[part 4 of 5: packages /Cluster to /NmConfig]
AUTOSAR XML (schema 4-3-0)
package /Cluster  (continued)
  can cluster BMC_CAN01: baudrate=500000, protocol-name=CAN, protocol-version=2.0, bus-off-recovery={bor-counter-l-1-to-l-2=1, bor-time-l-1=0.05, bor-time-l-2=0.2}
    can physical channel CHNL: comm-connectors=CN_BMC_CAN01
      frame BJB_08_XIX_BMC_CAN01: id 0x12DD556E, to BMC_HV, frame-length=8, can-addressing-mode=EXTENDED, can-frame-rx-behavior=CAN-20, can-frame-tx-behavior=CAN-20
        pdu BJB_08_XIX_BMC_CAN01: length=8, transmission-mode-true-timing=cyclic-timing={time-offset=0, time-period=0.1}, unused-bit-pattern=0
          signal BJB_ErrMem_State_XIX_BJB_08_XIX_BMC_CAN01: start 12, 2 bit, little-endian, data-type-policy=OVERRIDE, i-signal-type=PRIMITIVE, init-value=2, base-type=BT_BJB_ErrMem_State, compu-method=CM_BJB_ErrMem_State, data-constr=DC_BJB_ErrMem_State, transfer-property=PENDING, to BMC_HV(timeout 1 s)  # Error Memory State
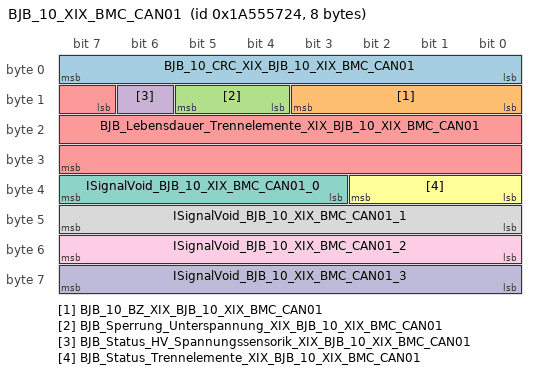
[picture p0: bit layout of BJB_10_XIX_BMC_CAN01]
      frame BJB_10_XIX_BMC_CAN01: id 0x1A555724, to BMC_HV, frame-length=8, can-addressing-mode=EXTENDED, can-frame-rx-behavior=CAN-20, can-frame-tx-behavior=CAN-20
        pdu BJB_10_XIX_BMC_CAN01_E2E: length=8, transmission-mode-true-timing=event-controlled-timing={number-of-repetitions=0, repetition-period=0}, unused-bit-pattern=0  # Fuer die Botschaft ist das Cyclic-Timing 1.0 zu verwenden.
          signal BJB_10_CRC_XIX_BJB_10_XIX_BMC_CAN01: start 0, 8 bit, little-endian, data-type-policy=OVERRIDE, i-signal-type=PRIMITIVE, init-value=0, base-type=BT_BJB_10_CRC, to BMC_HV(timeout 5 s)
          signal BJB_10_BZ_XIX_BJB_10_XIX_BMC_CAN01: start 8, 4 bit, little-endian, data-type-policy=OVERRIDE, i-signal-type=PRIMITIVE, init-value=0, base-type=BT_BJB_10_BZ, to BMC_HV(timeout 5 s)
          signal BJB_Sperrung_Unterspannung_XIX_BJB_10_XIX_BMC_CAN01: start 12, 2 bit, little-endian, data-type-policy=OVERRIDE, i-signal-type=PRIMITIVE, init-value=2, base-type=BT_BJB_Sperrung_Unterspannung, invalid-value=Invalid_BJB_Sperrung_Unterspannung_XIX_BJB_10_XIX_BMC_CAN01:3, compu-method=CM_BJB_Sperrung_Unterspannung, data-constr=DC_BJB_Sperrung_Unterspannung, to BMC_HV(timeout 5 s)  # Status Sperrung durch Unterspannung zum Datenaustausch für redundante Datenspeicherung
          signal BJB_Status_HV_Spannungssensorik_XIX_BJB_10_XIX_BMC_CAN01: start 14, 1 bit, little-endian, data-type-policy=OVERRIDE, i-signal-type=PRIMITIVE, init-value=0, base-type=BT_BJB_Status_HV_Spannungssensorik, invalid-value=Invalid_BJB_Status_HV_Spannungssensorik_XIX_BJB_10_XIX_BMC_CAN01:1, compu-method=CM_BJB_Status_HV_Spannungssensorik, data-constr=DC_BJB_Status_HV_Spannungssensorik, to BMC_HV(timeout 5 s)  # Status HV Spannungssensorik zum Datenaustausch für redundante Datenspeicherung
          signal BJB_Lebensdauer_Trennelemente_XIX_BJB_10_XIX_BMC_CAN01: start 15, 17 bit, little-endian, data-type-policy=OVERRIDE, i-signal-type=PRIMITIVE, init-value=131070, base-type=BT_BJB_Lebensdauer_Trennelemente, invalid-value=Invalid_BJB_Lebensdauer_Trennelemente_XIX_BJB_10_XIX_BMC_CAN01:131071, compu-method=CM_BJB_Lebensdauer_Trennelemente, data-constr=DC_BJB_Lebensdauer_Trennelemente, unit=Unit_Unit_None, to BMC_HV(timeout 5 s)  # Lebensdauerzähler Trennelemente zum Datenaustausch für redundante Datenspeicherung
          signal BJB_Status_Trennelemente_XIX_BJB_10_XIX_BMC_CAN01: start 32, 3 bit, little-endian, data-type-policy=OVERRIDE, i-signal-type=PRIMITIVE, init-value=6, base-type=BT_BJB_Status_Trennelemente, invalid-value=Invalid_BJB_Status_Trennelemente_XIX_BJB_10_XIX_BMC_CAN01:7, compu-method=CM_BJB_Status_Trennelemente, data-constr=DC_BJB_Status_Trennelemente, to BMC_HV(timeout 5 s)  # Status Trennelemente zum Datenaustausch für redundante Datenspeicherung
          signal ISignalVoid_BJB_10_XIX_BMC_CAN01_0: start 35, 5 bit, little-endian, system signal SignalVoid_BJB_10_0, data-type-policy=OVERRIDE, i-signal-type=PRIMITIVE, base-type=BT_SignalVoid
          signal ISignalVoid_BJB_10_XIX_BMC_CAN01_1: start 40, 8 bit, little-endian, system signal SignalVoid_BJB_10_1, data-type-policy=OVERRIDE, i-signal-type=PRIMITIVE, base-type=BT_SignalVoid
          signal ISignalVoid_BJB_10_XIX_BMC_CAN01_2: start 48, 8 bit, little-endian, system signal SignalVoid_BJB_10_2, data-type-policy=OVERRIDE, i-signal-type=PRIMITIVE, base-type=BT_SignalVoid
          signal ISignalVoid_BJB_10_XIX_BMC_CAN01_3: start 56, 8 bit, little-endian, system signal SignalVoid_BJB_10_3, data-type-policy=OVERRIDE, i-signal-type=PRIMITIVE, base-type=BT_SignalVoid
          mapping SG_BJB_10_XIX_BMC_CAN01: i-signal-group=SG_BJB_10_XIX_BMC_CAN01, transfer-property=TRIGGERED-WITHOUT-REPETITION
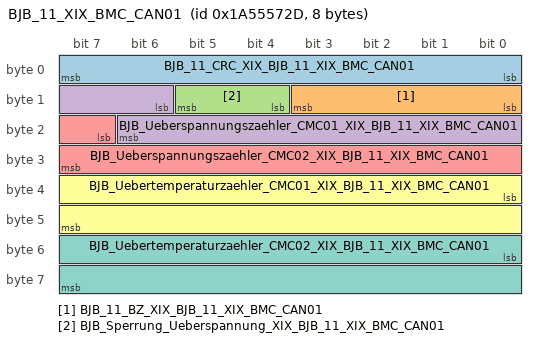
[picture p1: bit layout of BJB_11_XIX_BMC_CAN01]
      frame BJB_11_XIX_BMC_CAN01: id 0x1A55572D, to BMC_HV, frame-length=8, can-addressing-mode=EXTENDED, can-frame-rx-behavior=CAN-20, can-frame-tx-behavior=CAN-20
        pdu BJB_11_XIX_BMC_CAN01_E2E: length=8, transmission-mode-true-timing=event-controlled-timing={number-of-repetitions=0, repetition-period=0}, unused-bit-pattern=0  # Fuer die Botschaft ist das Cyclic-Timing 1.0 zu verwenden.
          signal BJB_11_CRC_XIX_BJB_11_XIX_BMC_CAN01: start 0, 8 bit, little-endian, data-type-policy=OVERRIDE, i-signal-type=PRIMITIVE, init-value=0, base-type=BT_BJB_11_CRC, to BMC_HV(timeout 5 s)
          signal BJB_11_BZ_XIX_BJB_11_XIX_BMC_CAN01: start 8, 4 bit, little-endian, data-type-policy=OVERRIDE, i-signal-type=PRIMITIVE, init-value=0, base-type=BT_BJB_11_BZ, to BMC_HV(timeout 5 s)
          signal BJB_Sperrung_Ueberspannung_XIX_BJB_11_XIX_BMC_CAN01: start 12, 2 bit, little-endian, data-type-policy=OVERRIDE, i-signal-type=PRIMITIVE, init-value=2, base-type=BT_BJB_Sperrung_Ueberspannung, invalid-value=Invalid_BJB_Sperrung_Ueberspannung_XIX_BJB_11_XIX_BMC_CAN01:3, compu-method=CM_BJB_Sperrung_Ueberspannung, data-constr=DC_BJB_Sperrung_Ueberspannung, to BMC_HV(timeout 5 s)  # Status Sperrung durch Ueberspannung zum Datenaustausch für redundante Datenspeicherung
          signal BJB_Ueberspannungszaehler_CMC01_XIX_BJB_11_XIX_BMC_CAN01: start 14, 9 bit, little-endian, data-type-policy=OVERRIDE, i-signal-type=PRIMITIVE, init-value=510, base-type=BT_BJB_Ueberspannungszaehler_CMC01, invalid-value=Invalid_BJB_Ueberspannungszaehler_CMC01_XIX_BJB_11_XIX_BMC_CAN01:511, compu-method=CM_BJB_Ueberspannungszaehler_CMC01, data-constr=DC_BJB_Ueberspannungszaehler_CMC01, unit=Unit_Unit_None, to BMC_HV(timeout 5 s)  # Überspannungszähler zum Datenaustausch für redundante Datenspeicherung
          signal BJB_Ueberspannungszaehler_CMC02_XIX_BJB_11_XIX_BMC_CAN01: start 23, 9 bit, little-endian, data-type-policy=OVERRIDE, i-signal-type=PRIMITIVE, init-value=510, base-type=BT_BJB_Ueberspannungszaehler_CMC02, invalid-value=Invalid_BJB_Ueberspannungszaehler_CMC02_XIX_BJB_11_XIX_BMC_CAN01:511, compu-method=CM_BJB_Ueberspannungszaehler_CMC02, data-constr=DC_BJB_Ueberspannungszaehler_CMC02, unit=Unit_Unit_None, to BMC_HV(timeout 5 s)  # Überspannungszähler zum Datenaustausch für redundante Datenspeicherung
          signal BJB_Uebertemperaturzaehler_CMC01_XIX_BJB_11_XIX_BMC_CAN01: start 32, 16 bit, little-endian, data-type-policy=OVERRIDE, i-signal-type=PRIMITIVE, init-value=65534, base-type=BT_BJB_Uebertemperaturzaehler_CMC01, invalid-value=Invalid_BJB_Uebertemperaturzaehler_CMC01_XIX_BJB_11_XIX_BMC_CAN01:65535, compu-method=CM_BJB_Uebertemperaturzaehler_CMC01, data-constr=DC_BJB_Uebertemperaturzaehler_CMC01, unit=Unit_Unit_None, to BMC_HV(timeout 5 s)  # Übertemperaturzähler zum Datenaustausch für redundante Datenspeicherung
          signal BJB_Uebertemperaturzaehler_CMC02_XIX_BJB_11_XIX_BMC_CAN01: start 48, 16 bit, little-endian, data-type-policy=OVERRIDE, i-signal-type=PRIMITIVE, init-value=65534, base-type=BT_BJB_Uebertemperaturzaehler_CMC02, invalid-value=Invalid_BJB_Uebertemperaturzaehler_CMC02_XIX_BJB_11_XIX_BMC_CAN01:65535, compu-method=CM_BJB_Uebertemperaturzaehler_CMC02, data-constr=DC_BJB_Uebertemperaturzaehler_CMC02, unit=Unit_Unit_None, to BMC_HV(timeout 5 s)  # Übertemperaturzähler zum Datenaustausch für redundante Datenspeicherung
          mapping SG_BJB_11_XIX_BMC_CAN01: i-signal-group=SG_BJB_11_XIX_BMC_CAN01, transfer-property=TRIGGERED-WITHOUT-REPETITION
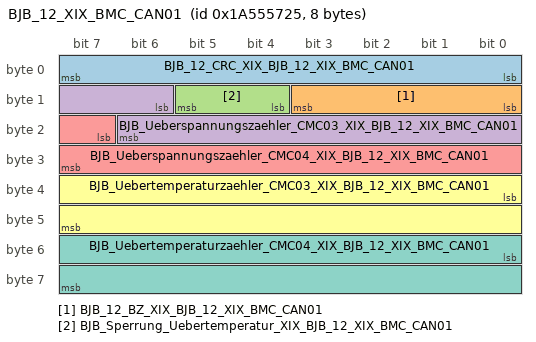
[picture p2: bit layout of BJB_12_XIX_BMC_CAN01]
      frame BJB_12_XIX_BMC_CAN01: id 0x1A555725, to BMC_HV, frame-length=8, can-addressing-mode=EXTENDED, can-frame-rx-behavior=CAN-20, can-frame-tx-behavior=CAN-20
        pdu BJB_12_XIX_BMC_CAN01_E2E: length=8, transmission-mode-true-timing=event-controlled-timing={number-of-repetitions=0, repetition-period=0}, unused-bit-pattern=0  # Fuer die Botschaft ist das Cyclic-Timing 1.0 zu verwenden.
          signal BJB_12_CRC_XIX_BJB_12_XIX_BMC_CAN01: start 0, 8 bit, little-endian, data-type-policy=OVERRIDE, i-signal-type=PRIMITIVE, init-value=0, base-type=BT_BJB_12_CRC, to BMC_HV(timeout 5 s)
          signal BJB_12_BZ_XIX_BJB_12_XIX_BMC_CAN01: start 8, 4 bit, little-endian, data-type-policy=OVERRIDE, i-signal-type=PRIMITIVE, init-value=0, base-type=BT_BJB_12_BZ, to BMC_HV(timeout 5 s)
          signal BJB_Sperrung_Uebertemperatur_XIX_BJB_12_XIX_BMC_CAN01: start 12, 2 bit, little-endian, data-type-policy=OVERRIDE, i-signal-type=PRIMITIVE, init-value=2, base-type=BT_BJB_Sperrung_Uebertemperatur, invalid-value=Invalid_BJB_Sperrung_Uebertemperatur_XIX_BJB_12_XIX_BMC_CAN01:3, compu-method=CM_BJB_Sperrung_Uebertemperatur, data-constr=DC_BJB_Sperrung_Uebertemperatur, to BMC_HV(timeout 5 s)  # Status Sperrung durch Uebertemperatur zum Datenaustausch für redundante Datenspeicherung
          signal BJB_Ueberspannungszaehler_CMC03_XIX_BJB_12_XIX_BMC_CAN01: start 14, 9 bit, little-endian, data-type-policy=OVERRIDE, i-signal-type=PRIMITIVE, init-value=510, base-type=BT_BJB_Ueberspannungszaehler_CMC03, invalid-value=Invalid_BJB_Ueberspannungszaehler_CMC03_XIX_BJB_12_XIX_BMC_CAN01:511, compu-method=CM_BJB_Ueberspannungszaehler_CMC03, data-constr=DC_BJB_Ueberspannungszaehler_CMC03, unit=Unit_Unit_None, to BMC_HV(timeout 5 s)  # Überspannungszähler zum Datenaustausch für redundante Datenspeicherung
          signal BJB_Ueberspannungszaehler_CMC04_XIX_BJB_12_XIX_BMC_CAN01: start 23, 9 bit, little-endian, data-type-policy=OVERRIDE, i-signal-type=PRIMITIVE, init-value=510, base-type=BT_BJB_Ueberspannungszaehler_CMC04, invalid-value=Invalid_BJB_Ueberspannungszaehler_CMC04_XIX_BJB_12_XIX_BMC_CAN01:511, compu-method=CM_BJB_Ueberspannungszaehler_CMC04, data-constr=DC_BJB_Ueberspannungszaehler_CMC04, unit=Unit_Unit_None, to BMC_HV(timeout 5 s)  # Überspannungszähler zum Datenaustausch für redundante Datenspeicherung
          signal BJB_Uebertemperaturzaehler_CMC03_XIX_BJB_12_XIX_BMC_CAN01: start 32, 16 bit, little-endian, data-type-policy=OVERRIDE, i-signal-type=PRIMITIVE, init-value=65534, base-type=BT_BJB_Uebertemperaturzaehler_CMC03, invalid-value=Invalid_BJB_Uebertemperaturzaehler_CMC03_XIX_BJB_12_XIX_BMC_CAN01:65535, compu-method=CM_BJB_Uebertemperaturzaehler_CMC03, data-constr=DC_BJB_Uebertemperaturzaehler_CMC03, unit=Unit_Unit_None, to BMC_HV(timeout 5 s)  # Übertemperaturzähler zum Datenaustausch für redundante Datenspeicherung
          signal BJB_Uebertemperaturzaehler_CMC04_XIX_BJB_12_XIX_BMC_CAN01: start 48, 16 bit, little-endian, data-type-policy=OVERRIDE, i-signal-type=PRIMITIVE, init-value=65534, base-type=BT_BJB_Uebertemperaturzaehler_CMC04, invalid-value=Invalid_BJB_Uebertemperaturzaehler_CMC04_XIX_BJB_12_XIX_BMC_CAN01:65535, compu-method=CM_BJB_Uebertemperaturzaehler_CMC04, data-constr=DC_BJB_Uebertemperaturzaehler_CMC04, unit=Unit_Unit_None, to BMC_HV(timeout 5 s)  # Übertemperaturzähler zum Datenaustausch für redundante Datenspeicherung
          mapping SG_BJB_12_XIX_BMC_CAN01: i-signal-group=SG_BJB_12_XIX_BMC_CAN01, transfer-property=TRIGGERED-WITHOUT-REPETITION
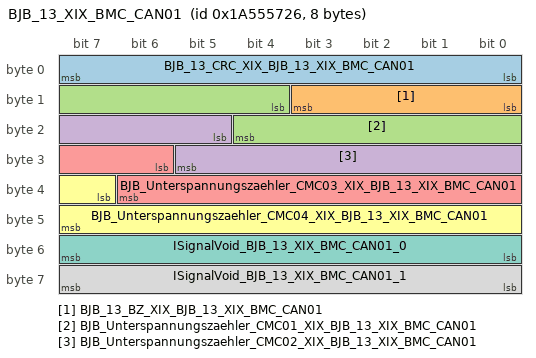
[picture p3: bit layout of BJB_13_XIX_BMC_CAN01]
      frame BJB_13_XIX_BMC_CAN01: id 0x1A555726, to BMC_HV, frame-length=8, can-addressing-mode=EXTENDED, can-frame-rx-behavior=CAN-20, can-frame-tx-behavior=CAN-20
        pdu BJB_13_XIX_BMC_CAN01_E2E: length=8, transmission-mode-true-timing=event-controlled-timing={number-of-repetitions=0, repetition-period=0}, unused-bit-pattern=0  # Fuer die Botschaft ist das Cyclic-Timing 1.0 zu verwenden.
          signal BJB_13_CRC_XIX_BJB_13_XIX_BMC_CAN01: start 0, 8 bit, little-endian, data-type-policy=OVERRIDE, i-signal-type=PRIMITIVE, init-value=0, base-type=BT_BJB_13_CRC, to BMC_HV(timeout 5 s)
          signal BJB_13_BZ_XIX_BJB_13_XIX_BMC_CAN01: start 8, 4 bit, little-endian, data-type-policy=OVERRIDE, i-signal-type=PRIMITIVE, init-value=0, base-type=BT_BJB_13_BZ, to BMC_HV(timeout 5 s)
          signal BJB_Unterspannungszaehler_CMC01_XIX_BJB_13_XIX_BMC_CAN01: start 12, 9 bit, little-endian, data-type-policy=OVERRIDE, i-signal-type=PRIMITIVE, init-value=510, base-type=BT_BJB_Unterspannungszaehler_CMC01, invalid-value=Invalid_BJB_Unterspannungszaehler_CMC01_XIX_BJB_13_XIX_BMC_CAN01:511, compu-method=CM_BJB_Unterspannungszaehler_CMC01, data-constr=DC_BJB_Unterspannungszaehler_CMC01, unit=Unit_Unit_None, to BMC_HV(timeout 5 s)  # Unterspannungszähler zum Datenaustausch für redundante Datenspeicherung
          signal BJB_Unterspannungszaehler_CMC02_XIX_BJB_13_XIX_BMC_CAN01: start 21, 9 bit, little-endian, data-type-policy=OVERRIDE, i-signal-type=PRIMITIVE, init-value=510, base-type=BT_BJB_Unterspannungszaehler_CMC02, invalid-value=Invalid_BJB_Unterspannungszaehler_CMC02_XIX_BJB_13_XIX_BMC_CAN01:511, compu-method=CM_BJB_Unterspannungszaehler_CMC02, data-constr=DC_BJB_Unterspannungszaehler_CMC02, unit=Unit_Unit_None, to BMC_HV(timeout 5 s)  # Unterspannungszähler zum Datenaustausch für redundante Datenspeicherung
          signal BJB_Unterspannungszaehler_CMC03_XIX_BJB_13_XIX_BMC_CAN01: start 30, 9 bit, little-endian, data-type-policy=OVERRIDE, i-signal-type=PRIMITIVE, init-value=510, base-type=BT_BJB_Unterspannungszaehler_CMC03, invalid-value=Invalid_BJB_Unterspannungszaehler_CMC03_XIX_BJB_13_XIX_BMC_CAN01:511, compu-method=CM_BJB_Unterspannungszaehler_CMC03, data-constr=DC_BJB_Unterspannungszaehler_CMC03, unit=Unit_Unit_None, to BMC_HV(timeout 5 s)  # Unterspannungszähler zum Datenaustausch für redundante Datenspeicherung
          signal BJB_Unterspannungszaehler_CMC04_XIX_BJB_13_XIX_BMC_CAN01: start 39, 9 bit, little-endian, data-type-policy=OVERRIDE, i-signal-type=PRIMITIVE, init-value=510, base-type=BT_BJB_Unterspannungszaehler_CMC04, invalid-value=Invalid_BJB_Unterspannungszaehler_CMC04_XIX_BJB_13_XIX_BMC_CAN01:511, compu-method=CM_BJB_Unterspannungszaehler_CMC04, data-constr=DC_BJB_Unterspannungszaehler_CMC04, unit=Unit_Unit_None, to BMC_HV(timeout 5 s)  # Unterspannungszähler zum Datenaustausch für redundante Datenspeicherung
          signal ISignalVoid_BJB_13_XIX_BMC_CAN01_0: start 48, 8 bit, little-endian, system signal SignalVoid_BJB_13_0, data-type-policy=OVERRIDE, i-signal-type=PRIMITIVE, base-type=BT_SignalVoid
          signal ISignalVoid_BJB_13_XIX_BMC_CAN01_1: start 56, 8 bit, little-endian, system signal SignalVoid_BJB_13_1, data-type-policy=OVERRIDE, i-signal-type=PRIMITIVE, base-type=BT_SignalVoid
          mapping SG_BJB_13_XIX_BMC_CAN01: i-signal-group=SG_BJB_13_XIX_BMC_CAN01, transfer-property=TRIGGERED-WITHOUT-REPETITION
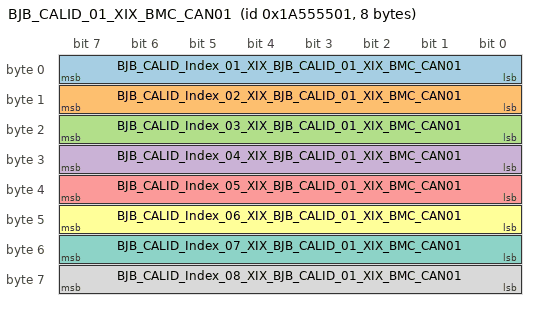
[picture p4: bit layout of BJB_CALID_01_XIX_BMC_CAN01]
      frame BJB_CALID_01_XIX_BMC_CAN01: id 0x1A555501, to BMC_HV, frame-length=8, can-addressing-mode=EXTENDED, can-frame-rx-behavior=CAN-20, can-frame-tx-behavior=CAN-20
        pdu BJB_CALID_01_XIX_BMC_CAN01: length=8, transmission-mode-true-timing=cyclic-timing={time-offset=0, time-period=1}, unused-bit-pattern=0
          signal BJB_CALID_Index_01_XIX_BJB_CALID_01_XIX_BMC_CAN01: start 0, 8 bit, little-endian, data-type-policy=OVERRIDE, i-signal-type=PRIMITIVE, init-value=63, base-type=BT_BJB_CALID_Index_01, compu-method=CM_BJB_CALID_Index_01, data-constr=DC_BJB_CALID_Index_01, transfer-property=PENDING, to BMC_HV(timeout 5 s)  # Calibration-Identification Index_01
          signal BJB_CALID_Index_02_XIX_BJB_CALID_01_XIX_BMC_CAN01: start 8, 8 bit, little-endian, data-type-policy=OVERRIDE, i-signal-type=PRIMITIVE, init-value=63, base-type=BT_BJB_CALID_Index_02, compu-method=CM_BJB_CALID_Index_02, data-constr=DC_BJB_CALID_Index_02, transfer-property=PENDING, to BMC_HV(timeout 5 s)  # Calibration-Identification Index_02
          signal BJB_CALID_Index_03_XIX_BJB_CALID_01_XIX_BMC_CAN01: start 16, 8 bit, little-endian, data-type-policy=OVERRIDE, i-signal-type=PRIMITIVE, init-value=63, base-type=BT_BJB_CALID_Index_03, compu-method=CM_BJB_CALID_Index_03, data-constr=DC_BJB_CALID_Index_03, transfer-property=PENDING, to BMC_HV(timeout 5 s)  # Calibration-Identification Index_03
          signal BJB_CALID_Index_04_XIX_BJB_CALID_01_XIX_BMC_CAN01: start 24, 8 bit, little-endian, data-type-policy=OVERRIDE, i-signal-type=PRIMITIVE, init-value=63, base-type=BT_BJB_CALID_Index_04, compu-method=CM_BJB_CALID_Index_04, data-constr=DC_BJB_CALID_Index_04, transfer-property=PENDING, to BMC_HV(timeout 5 s)  # Calibration-Identification Index_04
          signal BJB_CALID_Index_05_XIX_BJB_CALID_01_XIX_BMC_CAN01: start 32, 8 bit, little-endian, data-type-policy=OVERRIDE, i-signal-type=PRIMITIVE, init-value=63, base-type=BT_BJB_CALID_Index_05, compu-method=CM_BJB_CALID_Index_05, data-constr=DC_BJB_CALID_Index_05, transfer-property=PENDING, to BMC_HV(timeout 5 s)  # Calibration-Identification Index_05
          signal BJB_CALID_Index_06_XIX_BJB_CALID_01_XIX_BMC_CAN01: start 40, 8 bit, little-endian, data-type-policy=OVERRIDE, i-signal-type=PRIMITIVE, init-value=63, base-type=BT_BJB_CALID_Index_06, compu-method=CM_BJB_CALID_Index_06, data-constr=DC_BJB_CALID_Index_06, transfer-property=PENDING, to BMC_HV(timeout 5 s)  # Calibration-Identification Index_06
          signal BJB_CALID_Index_07_XIX_BJB_CALID_01_XIX_BMC_CAN01: start 48, 8 bit, little-endian, data-type-policy=OVERRIDE, i-signal-type=PRIMITIVE, init-value=63, base-type=BT_BJB_CALID_Index_07, compu-method=CM_BJB_CALID_Index_07, data-constr=DC_BJB_CALID_Index_07, transfer-property=PENDING, to BMC_HV(timeout 5 s)  # Calibration-Identification Index_07
          signal BJB_CALID_Index_08_XIX_BJB_CALID_01_XIX_BMC_CAN01: start 56, 8 bit, little-endian, data-type-policy=OVERRIDE, i-signal-type=PRIMITIVE, init-value=63, base-type=BT_BJB_CALID_Index_08, compu-method=CM_BJB_CALID_Index_08, data-constr=DC_BJB_CALID_Index_08, transfer-property=PENDING, to BMC_HV(timeout 5 s)  # Calibration-Identification Index_08
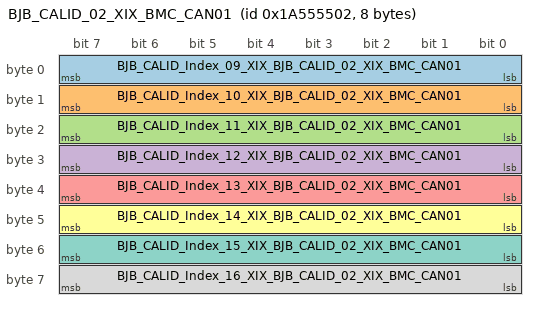
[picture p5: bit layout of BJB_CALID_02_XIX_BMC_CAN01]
      frame BJB_CALID_02_XIX_BMC_CAN01: id 0x1A555502, to BMC_HV, frame-length=8, can-addressing-mode=EXTENDED, can-frame-rx-behavior=CAN-20, can-frame-tx-behavior=CAN-20
        pdu BJB_CALID_02_XIX_BMC_CAN01: length=8, transmission-mode-true-timing=cyclic-timing={time-offset=0, time-period=1}, unused-bit-pattern=0
          signal BJB_CALID_Index_09_XIX_BJB_CALID_02_XIX_BMC_CAN01: start 0, 8 bit, little-endian, data-type-policy=OVERRIDE, i-signal-type=PRIMITIVE, init-value=63, base-type=BT_BJB_CALID_Index_09, compu-method=CM_BJB_CALID_Index_09, data-constr=DC_BJB_CALID_Index_09, transfer-property=PENDING, to BMC_HV(timeout 5 s)  # Calibration-Identification Index_09
          signal BJB_CALID_Index_10_XIX_BJB_CALID_02_XIX_BMC_CAN01: start 8, 8 bit, little-endian, data-type-policy=OVERRIDE, i-signal-type=PRIMITIVE, init-value=63, base-type=BT_BJB_CALID_Index_10, compu-method=CM_BJB_CALID_Index_10, data-constr=DC_BJB_CALID_Index_10, transfer-property=PENDING, to BMC_HV(timeout 5 s)  # Calibration-Identification Index_10
          signal BJB_CALID_Index_11_XIX_BJB_CALID_02_XIX_BMC_CAN01: start 16, 8 bit, little-endian, data-type-policy=OVERRIDE, i-signal-type=PRIMITIVE, init-value=63, base-type=BT_BJB_CALID_Index_11, compu-method=CM_BJB_CALID_Index_11, data-constr=DC_BJB_CALID_Index_11, transfer-property=PENDING, to BMC_HV(timeout 5 s)  # Calibration-Identification Index_01
          signal BJB_CALID_Index_12_XIX_BJB_CALID_02_XIX_BMC_CAN01: start 24, 8 bit, little-endian, data-type-policy=OVERRIDE, i-signal-type=PRIMITIVE, init-value=63, base-type=BT_BJB_CALID_Index_12, compu-method=CM_BJB_CALID_Index_12, data-constr=DC_BJB_CALID_Index_12, transfer-property=PENDING, to BMC_HV(timeout 5 s)  # Calibration-Identification Index_12
          signal BJB_CALID_Index_13_XIX_BJB_CALID_02_XIX_BMC_CAN01: start 32, 8 bit, little-endian, data-type-policy=OVERRIDE, i-signal-type=PRIMITIVE, init-value=63, base-type=BT_BJB_CALID_Index_13, compu-method=CM_BJB_CALID_Index_13, data-constr=DC_BJB_CALID_Index_13, transfer-property=PENDING, to BMC_HV(timeout 5 s)  # Calibration-Identification Index_13
          signal BJB_CALID_Index_14_XIX_BJB_CALID_02_XIX_BMC_CAN01: start 40, 8 bit, little-endian, data-type-policy=OVERRIDE, i-signal-type=PRIMITIVE, init-value=63, base-type=BT_BJB_CALID_Index_14, compu-method=CM_BJB_CALID_Index_14, data-constr=DC_BJB_CALID_Index_14, transfer-property=PENDING, to BMC_HV(timeout 5 s)  # Calibration-Identification Index_14
          signal BJB_CALID_Index_15_XIX_BJB_CALID_02_XIX_BMC_CAN01: start 48, 8 bit, little-endian, data-type-policy=OVERRIDE, i-signal-type=PRIMITIVE, init-value=63, base-type=BT_BJB_CALID_Index_15, compu-method=CM_BJB_CALID_Index_15, data-constr=DC_BJB_CALID_Index_15, transfer-property=PENDING, to BMC_HV(timeout 5 s)  # Calibration-Identification Index_15
          signal BJB_CALID_Index_16_XIX_BJB_CALID_02_XIX_BMC_CAN01: start 56, 8 bit, little-endian, data-type-policy=OVERRIDE, i-signal-type=PRIMITIVE, init-value=63, base-type=BT_BJB_CALID_Index_16, compu-method=CM_BJB_CALID_Index_16, data-constr=DC_BJB_CALID_Index_16, transfer-property=PENDING, to BMC_HV(timeout 5 s)  # Calibration-Identification Index_16
      frame BJB_CVN_01_XIX_BMC_CAN01: id 0x1A555503, to BMC_HV, frame-length=8, can-addressing-mode=EXTENDED, can-frame-rx-behavior=CAN-20, can-frame-tx-behavior=CAN-20
        pdu BJB_CVN_01_XIX_BMC_CAN01: length=8, transmission-mode-true-timing=cyclic-timing={time-offset=0, time-period=1}, unused-bit-pattern=0
          signal BJB_CVN_VLD_XIX_BJB_CVN_01_XIX_BMC_CAN01: start 0, 1 bit, little-endian, data-type-policy=OVERRIDE, i-signal-type=PRIMITIVE, init-value=0, base-type=BT_BJB_CVN_VLD, compu-method=CM_BJB_CVN_VLD, data-constr=DC_BJB_CVN_VLD, transfer-property=PENDING, to BMC_HV(timeout 5 s)  # Über dieses Signal wird gekennzeichnet, ob die Berechnung der CVN im SecondaryOBDECU abgeschlossen ist.
          signal BJB_CVN_Byte_1_XIX_BJB_CVN_01_XIX_BMC_CAN01: start 1, 8 bit, little-endian, data-type-policy=OVERRIDE, i-signal-type=PRIMITIVE, init-value=0, base-type=BT_BJB_CVN_Byte_1, compu-method=CM_BJB_CVN_Byte_1, data-constr=DC_BJB_CVN_Byte_1, transfer-property=PENDING, to BMC_HV(timeout 5 s)  # Calibration Verification Number
          signal BJB_CVN_Byte_2_XIX_BJB_CVN_01_XIX_BMC_CAN01: start 9, 8 bit, little-endian, data-type-policy=OVERRIDE, i-signal-type=PRIMITIVE, init-value=0, base-type=BT_BJB_CVN_Byte_2, compu-method=CM_BJB_CVN_Byte_2, data-constr=DC_BJB_CVN_Byte_2, transfer-property=PENDING, to BMC_HV(timeout 5 s)  # Calibration Verification Number
          signal BJB_CVN_Byte_3_XIX_BJB_CVN_01_XIX_BMC_CAN01: start 17, 8 bit, little-endian, data-type-policy=OVERRIDE, i-signal-type=PRIMITIVE, init-value=0, base-type=BT_BJB_CVN_Byte_3, compu-method=CM_BJB_CVN_Byte_3, data-constr=DC_BJB_CVN_Byte_3, transfer-property=PENDING, to BMC_HV(timeout 5 s)  # Calibration Verification Number
          signal BJB_CVN_Byte_4_XIX_BJB_CVN_01_XIX_BMC_CAN01: start 25, 8 bit, little-endian, data-type-policy=OVERRIDE, i-signal-type=PRIMITIVE, init-value=0, base-type=BT_BJB_CVN_Byte_4, compu-method=CM_BJB_CVN_Byte_4, data-constr=DC_BJB_CVN_Byte_4, transfer-property=PENDING, to BMC_HV(timeout 5 s)  # Calibration Verification Number
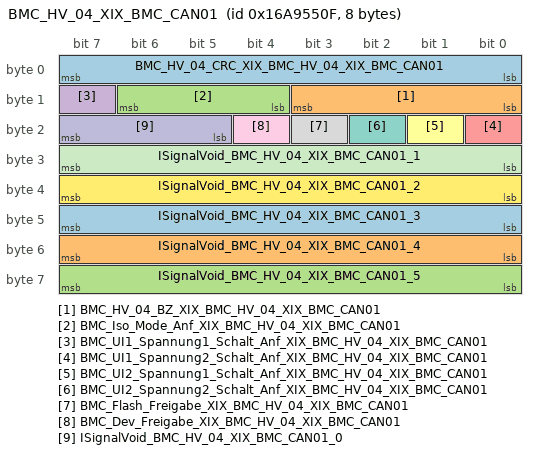
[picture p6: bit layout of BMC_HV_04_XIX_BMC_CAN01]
      frame BMC_HV_04_XIX_BMC_CAN01: id 0x16A9550F, from BMC_HV, frame-length=8, can-addressing-mode=EXTENDED, can-frame-rx-behavior=CAN-20, can-frame-tx-behavior=CAN-20
        pdu BMC_HV_04_XIX_BMC_CAN01_E2E: length=8, minimum-delay=0.05, transmission-mode-true-timing=event-controlled-timing={number-of-repetitions=0, repetition-period=0}, unused-bit-pattern=0  # Fuer die Botschaft ist das Cyclic-Timing 1.0 zu verwenden.
          signal BMC_HV_04_CRC_XIX_BMC_HV_04_XIX_BMC_CAN01: start 0, 8 bit, little-endian, data-type-policy=OVERRIDE, i-signal-type=PRIMITIVE, init-value=0, base-type=BT_BMC_HV_04_CRC, compu-method=CM_BMC_HV_04_CRC, data-constr=DC_BMC_HV_04_CRC
          signal BMC_HV_04_BZ_XIX_BMC_HV_04_XIX_BMC_CAN01: start 8, 4 bit, little-endian, data-type-policy=OVERRIDE, i-signal-type=PRIMITIVE, init-value=0, base-type=BT_BMC_HV_04_BZ, compu-method=CM_BMC_HV_04_BZ, data-constr=DC_BMC_HV_04_BZ
          signal BMC_Iso_Mode_Anf_XIX_BMC_HV_04_XIX_BMC_CAN01: start 12, 3 bit, little-endian, data-type-policy=OVERRIDE, i-signal-type=PRIMITIVE, init-value=0, base-type=BT_BMC_Iso_Mode_Anf, compu-method=CM_BMC_Iso_Mode_Anf, data-constr=DC_BMC_Iso_Mode_Anf  # Anforderung Isolationsmessung an UI-Sensor
          signal BMC_UI1_Spannung1_Schalt_Anf_XIX_BMC_HV_04_XIX_BMC_CAN01: start 15, 1 bit, little-endian, data-type-policy=OVERRIDE, i-signal-type=PRIMITIVE, init-value=0, base-type=BT_BMC_UI1_Spannung1_Schalt_Anf, compu-method=CM_BMC_UI1_Spannung1_Schalt_Anf, data-constr=DC_BMC_UI1_Spannung1_Schalt_Anf  # Aktivierung des Spannungsmesskanals1
          signal BMC_UI1_Spannung2_Schalt_Anf_XIX_BMC_HV_04_XIX_BMC_CAN01: start 16, 1 bit, little-endian, data-type-policy=OVERRIDE, i-signal-type=PRIMITIVE, init-value=0, base-type=BT_BMC_UI1_Spannung2_Schalt_Anf, compu-method=CM_BMC_UI1_Spannung2_Schalt_Anf, data-constr=DC_BMC_UI1_Spannung2_Schalt_Anf  # Aktivierung des Spannungsmesskanals2
          signal BMC_UI2_Spannung1_Schalt_Anf_XIX_BMC_HV_04_XIX_BMC_CAN01: start 17, 1 bit, little-endian, data-type-policy=OVERRIDE, i-signal-type=PRIMITIVE, init-value=0, base-type=BT_BMC_UI2_Spannung1_Schalt_Anf, compu-method=CM_BMC_UI2_Spannung1_Schalt_Anf, data-constr=DC_BMC_UI2_Spannung1_Schalt_Anf  # Aktivierung des Spannungsmesskanals1
          signal BMC_UI2_Spannung2_Schalt_Anf_XIX_BMC_HV_04_XIX_BMC_CAN01: start 18, 1 bit, little-endian, data-type-policy=OVERRIDE, i-signal-type=PRIMITIVE, init-value=0, base-type=BT_BMC_UI2_Spannung2_Schalt_Anf, compu-method=CM_BMC_UI2_Spannung2_Schalt_Anf, data-constr=DC_BMC_UI2_Spannung2_Schalt_Anf  # Aktivierung des Spannungsmesskanals2
          signal BMC_Flash_Freigabe_XIX_BMC_HV_04_XIX_BMC_CAN01: start 19, 1 bit, little-endian, data-type-policy=OVERRIDE, i-signal-type=PRIMITIVE, init-value=0, base-type=BT_BMC_Flash_Freigabe, compu-method=CM_BMC_Flash_Freigabe, data-constr=DC_BMC_Flash_Freigabe
          signal BMC_Dev_Freigabe_XIX_BMC_HV_04_XIX_BMC_CAN01: start 20, 1 bit, little-endian, data-type-policy=OVERRIDE, i-signal-type=PRIMITIVE, init-value=0, base-type=BT_BMC_Dev_Freigabe, compu-method=CM_BMC_Dev_Freigabe, data-constr=DC_BMC_Dev_Freigabe  # Aktivierung der Entwicklerbotschaften von BMC Subkomponenten
          signal ISignalVoid_BMC_HV_04_XIX_BMC_CAN01_0: start 21, 3 bit, little-endian, system signal SignalVoid_BMC_HV_04_0, data-type-policy=OVERRIDE, i-signal-type=PRIMITIVE, base-type=BT_SignalVoid
          signal ISignalVoid_BMC_HV_04_XIX_BMC_CAN01_1: start 24, 8 bit, little-endian, system signal SignalVoid_BMC_HV_04_1, data-type-policy=OVERRIDE, i-signal-type=PRIMITIVE, base-type=BT_SignalVoid
          signal ISignalVoid_BMC_HV_04_XIX_BMC_CAN01_2: start 32, 8 bit, little-endian, system signal SignalVoid_BMC_HV_04_2, data-type-policy=OVERRIDE, i-signal-type=PRIMITIVE, base-type=BT_SignalVoid
          signal ISignalVoid_BMC_HV_04_XIX_BMC_CAN01_3: start 40, 8 bit, little-endian, system signal SignalVoid_BMC_HV_04_3, data-type-policy=OVERRIDE, i-signal-type=PRIMITIVE, base-type=BT_SignalVoid
          signal ISignalVoid_BMC_HV_04_XIX_BMC_CAN01_4: start 48, 8 bit, little-endian, system signal SignalVoid_BMC_HV_04_4, data-type-policy=OVERRIDE, i-signal-type=PRIMITIVE, base-type=BT_SignalVoid
          signal ISignalVoid_BMC_HV_04_XIX_BMC_CAN01_5: start 56, 8 bit, little-endian, system signal SignalVoid_BMC_HV_04_5, data-type-policy=OVERRIDE, i-signal-type=PRIMITIVE, base-type=BT_SignalVoid
          mapping SG_BMC_HV_04_XIX_BMC_CAN01: i-signal-group=SG_BMC_HV_04_XIX_BMC_CAN01, transfer-property=TRIGGERED-WITHOUT-REPETITION
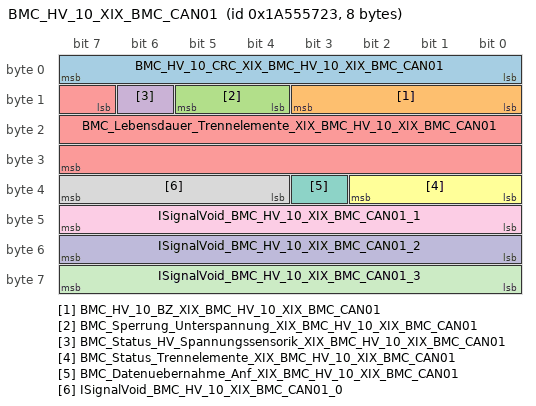
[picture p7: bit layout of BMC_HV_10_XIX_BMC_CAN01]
      frame BMC_HV_10_XIX_BMC_CAN01: id 0x1A555723, from BMC_HV, frame-length=8, can-addressing-mode=EXTENDED, can-frame-rx-behavior=CAN-20, can-frame-tx-behavior=CAN-20
        pdu BMC_HV_10_XIX_BMC_CAN01_E2E: length=8, transmission-mode-true-timing=event-controlled-timing={number-of-repetitions=0, repetition-period=0}, unused-bit-pattern=0  # Fuer die Botschaft ist das Cyclic-Timing 1.0 zu verwenden.
          signal BMC_HV_10_CRC_XIX_BMC_HV_10_XIX_BMC_CAN01: start 0, 8 bit, little-endian, data-type-policy=OVERRIDE, i-signal-type=PRIMITIVE, init-value=0, base-type=BT_BMC_HV_10_CRC
          signal BMC_HV_10_BZ_XIX_BMC_HV_10_XIX_BMC_CAN01: start 8, 4 bit, little-endian, data-type-policy=OVERRIDE, i-signal-type=PRIMITIVE, init-value=0, base-type=BT_BMC_HV_10_BZ
          signal BMC_Sperrung_Unterspannung_XIX_BMC_HV_10_XIX_BMC_CAN01: start 12, 2 bit, little-endian, data-type-policy=OVERRIDE, i-signal-type=PRIMITIVE, init-value=2, base-type=BT_BMC_Sperrung_Unterspannung, invalid-value=Invalid_BMC_Sperrung_Unterspannung_XIX_BMC_HV_10_XIX_BMC_CAN01:3, compu-method=CM_BMC_Sperrung_Unterspannung, data-constr=DC_BMC_Sperrung_Unterspannung  # Status Sperrung durch Unterspannung zum Datenaustausch für redundante Datenspeicherung
          signal BMC_Status_HV_Spannungssensorik_XIX_BMC_HV_10_XIX_BMC_CAN01: start 14, 1 bit, little-endian, data-type-policy=OVERRIDE, i-signal-type=PRIMITIVE, init-value=0, base-type=BT_BMC_Status_HV_Spannungssensorik, invalid-value=Invalid_BMC_Status_HV_Spannungssensorik_XIX_BMC_HV_10_XIX_BMC_CAN01:1, compu-method=CM_BMC_Status_HV_Spannungssensorik, data-constr=DC_BMC_Status_HV_Spannungssensorik  # Status HV Spannungssensorik zum Datenaustausch für redundante Datenspeicherung
          signal BMC_Lebensdauer_Trennelemente_XIX_BMC_HV_10_XIX_BMC_CAN01: start 15, 17 bit, little-endian, data-type-policy=OVERRIDE, i-signal-type=PRIMITIVE, init-value=131070, base-type=BT_BMC_Lebensdauer_Trennelemente, invalid-value=Invalid_BMC_Lebensdauer_Trennelemente_XIX_BMC_HV_10_XIX_BMC_CAN01:131071, compu-method=CM_BMC_Lebensdauer_Trennelemente, data-constr=DC_BMC_Lebensdauer_Trennelemente, unit=Unit_Unit_None  # Lebensdauerzähler Trennelemente zum Datenaustausch für redundante Datenspeicherung
          signal BMC_Status_Trennelemente_XIX_BMC_HV_10_XIX_BMC_CAN01: start 32, 3 bit, little-endian, data-type-policy=OVERRIDE, i-signal-type=PRIMITIVE, init-value=6, base-type=BT_BMC_Status_Trennelemente, invalid-value=Invalid_BMC_Status_Trennelemente_XIX_BMC_HV_10_XIX_BMC_CAN01:7, compu-method=CM_BMC_Status_Trennelemente, data-constr=DC_BMC_Status_Trennelemente  # Status Trennelemente zum Datenaustausch für redundante Datenspeicherung
          signal BMC_Datenuebernahme_Anf_XIX_BMC_HV_10_XIX_BMC_CAN01: start 35, 1 bit, little-endian, data-type-policy=OVERRIDE, i-signal-type=PRIMITIVE, init-value=0, base-type=BT_BMC_Datenuebernahme_Anf, compu-method=CM_BMC_Datenuebernahme_Anf, data-constr=DC_BMC_Datenuebernahme_Anf  # Trigger zur Datenuebernahme für redundante Datenspeicherung
          signal ISignalVoid_BMC_HV_10_XIX_BMC_CAN01_0: start 36, 4 bit, little-endian, system signal SignalVoid_BMC_HV_10_0, data-type-policy=OVERRIDE, i-signal-type=PRIMITIVE, base-type=BT_SignalVoid
          signal ISignalVoid_BMC_HV_10_XIX_BMC_CAN01_1: start 40, 8 bit, little-endian, system signal SignalVoid_BMC_HV_10_1, data-type-policy=OVERRIDE, i-signal-type=PRIMITIVE, base-type=BT_SignalVoid
          signal ISignalVoid_BMC_HV_10_XIX_BMC_CAN01_2: start 48, 8 bit, little-endian, system signal SignalVoid_BMC_HV_10_2, data-type-policy=OVERRIDE, i-signal-type=PRIMITIVE, base-type=BT_SignalVoid
          signal ISignalVoid_BMC_HV_10_XIX_BMC_CAN01_3: start 56, 8 bit, little-endian, system signal SignalVoid_BMC_HV_10_3, data-type-policy=OVERRIDE, i-signal-type=PRIMITIVE, base-type=BT_SignalVoid
          mapping SG_BMC_HV_10_XIX_BMC_CAN01: i-signal-group=SG_BMC_HV_10_XIX_BMC_CAN01, transfer-property=TRIGGERED-WITHOUT-REPETITION
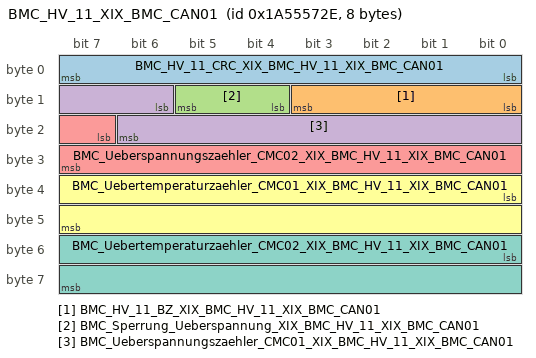
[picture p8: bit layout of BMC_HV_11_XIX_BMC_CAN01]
      frame BMC_HV_11_XIX_BMC_CAN01: id 0x1A55572E, from BMC_HV, frame-length=8, can-addressing-mode=EXTENDED, can-frame-rx-behavior=CAN-20, can-frame-tx-behavior=CAN-20
        pdu BMC_HV_11_XIX_BMC_CAN01_E2E: length=8, transmission-mode-true-timing=event-controlled-timing={number-of-repetitions=0, repetition-period=0}, unused-bit-pattern=0
          signal BMC_HV_11_CRC_XIX_BMC_HV_11_XIX_BMC_CAN01: start 0, 8 bit, little-endian, data-type-policy=OVERRIDE, i-signal-type=PRIMITIVE, init-value=0, base-type=BT_BMC_HV_11_CRC
          signal BMC_HV_11_BZ_XIX_BMC_HV_11_XIX_BMC_CAN01: start 8, 4 bit, little-endian, data-type-policy=OVERRIDE, i-signal-type=PRIMITIVE, init-value=0, base-type=BT_BMC_HV_11_BZ
          signal BMC_Sperrung_Ueberspannung_XIX_BMC_HV_11_XIX_BMC_CAN01: start 12, 2 bit, little-endian, data-type-policy=OVERRIDE, i-signal-type=PRIMITIVE, init-value=2, base-type=BT_BMC_Sperrung_Ueberspannung, invalid-value=Invalid_BMC_Sperrung_Ueberspannung_XIX_BMC_HV_11_XIX_BMC_CAN01:3, compu-method=CM_BMC_Sperrung_Ueberspannung, data-constr=DC_BMC_Sperrung_Ueberspannung  # Status Sperrung durch Ueberspannung zum Datenaustausch für redundante Datenspeicherung
          signal BMC_Ueberspannungszaehler_CMC01_XIX_BMC_HV_11_XIX_BMC_CAN01: start 14, 9 bit, little-endian, data-type-policy=OVERRIDE, i-signal-type=PRIMITIVE, init-value=510, base-type=BT_BMC_Ueberspannungszaehler_CMC01, invalid-value=Invalid_BMC_Ueberspannungszaehler_CMC01_XIX_BMC_HV_11_XIX_BMC_CAN01:511, compu-method=CM_BMC_Ueberspannungszaehler_CMC01, data-constr=DC_BMC_Ueberspannungszaehler_CMC01, unit=Unit_Unit_None  # Überspannungszähler zum Datenaustausch für redundante Datenspeicherung
          signal BMC_Ueberspannungszaehler_CMC02_XIX_BMC_HV_11_XIX_BMC_CAN01: start 23, 9 bit, little-endian, data-type-policy=OVERRIDE, i-signal-type=PRIMITIVE, init-value=510, base-type=BT_BMC_Ueberspannungszaehler_CMC02, invalid-value=Invalid_BMC_Ueberspannungszaehler_CMC02_XIX_BMC_HV_11_XIX_BMC_CAN01:511, compu-method=CM_BMC_Ueberspannungszaehler_CMC02, data-constr=DC_BMC_Ueberspannungszaehler_CMC02, unit=Unit_Unit_None  # Überspannungszähler zum Datenaustausch für redundante Datenspeicherung
          signal BMC_Uebertemperaturzaehler_CMC01_XIX_BMC_HV_11_XIX_BMC_CAN01: start 32, 16 bit, little-endian, data-type-policy=OVERRIDE, i-signal-type=PRIMITIVE, init-value=65534, base-type=BT_BMC_Uebertemperaturzaehler_CMC01, invalid-value=Invalid_BMC_Uebertemperaturzaehler_CMC01_XIX_BMC_HV_11_XIX_BMC_CAN01:65535, compu-method=CM_BMC_Uebertemperaturzaehler_CMC01, data-constr=DC_BMC_Uebertemperaturzaehler_CMC01, unit=Unit_Unit_None  # Übertemperaturzähler zum Datenaustausch für redundante Datenspeicherung
          signal BMC_Uebertemperaturzaehler_CMC02_XIX_BMC_HV_11_XIX_BMC_CAN01: start 48, 16 bit, little-endian, data-type-policy=OVERRIDE, i-signal-type=PRIMITIVE, init-value=65534, base-type=BT_BMC_Uebertemperaturzaehler_CMC02, invalid-value=Invalid_BMC_Uebertemperaturzaehler_CMC02_XIX_BMC_HV_11_XIX_BMC_CAN01:65535, compu-method=CM_BMC_Uebertemperaturzaehler_CMC02, data-constr=DC_BMC_Uebertemperaturzaehler_CMC02, unit=Unit_Unit_None  # Übertemperaturzähler zum Datenaustausch für redundante Datenspeicherung
          mapping SG_BMC_HV_11_XIX_BMC_CAN01: i-signal-group=SG_BMC_HV_11_XIX_BMC_CAN01, transfer-property=TRIGGERED-WITHOUT-REPETITION
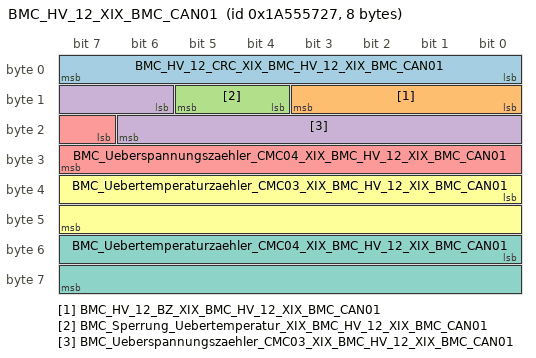
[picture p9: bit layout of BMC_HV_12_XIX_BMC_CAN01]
      frame BMC_HV_12_XIX_BMC_CAN01: id 0x1A555727, from BMC_HV, frame-length=8, can-addressing-mode=EXTENDED, can-frame-rx-behavior=CAN-20, can-frame-tx-behavior=CAN-20
        pdu BMC_HV_12_XIX_BMC_CAN01_E2E: length=8, transmission-mode-true-timing=event-controlled-timing={number-of-repetitions=0, repetition-period=0}, unused-bit-pattern=0
          signal BMC_HV_12_CRC_XIX_BMC_HV_12_XIX_BMC_CAN01: start 0, 8 bit, little-endian, data-type-policy=OVERRIDE, i-signal-type=PRIMITIVE, init-value=0, base-type=BT_BMC_HV_12_CRC
          signal BMC_HV_12_BZ_XIX_BMC_HV_12_XIX_BMC_CAN01: start 8, 4 bit, little-endian, data-type-policy=OVERRIDE, i-signal-type=PRIMITIVE, init-value=0, base-type=BT_BMC_HV_12_BZ
          signal BMC_Sperrung_Uebertemperatur_XIX_BMC_HV_12_XIX_BMC_CAN01: start 12, 2 bit, little-endian, data-type-policy=OVERRIDE, i-signal-type=PRIMITIVE, init-value=2, base-type=BT_BMC_Sperrung_Uebertemperatur, invalid-value=Invalid_BMC_Sperrung_Uebertemperatur_XIX_BMC_HV_12_XIX_BMC_CAN01:3, compu-method=CM_BMC_Sperrung_Uebertemperatur, data-constr=DC_BMC_Sperrung_Uebertemperatur  # Status Sperrung durch Uebertemperatur zum Datenaustausch für redundante Datenspeicherung
          signal BMC_Ueberspannungszaehler_CMC03_XIX_BMC_HV_12_XIX_BMC_CAN01: start 14, 9 bit, little-endian, data-type-policy=OVERRIDE, i-signal-type=PRIMITIVE, init-value=510, base-type=BT_BMC_Ueberspannungszaehler_CMC03, invalid-value=Invalid_BMC_Ueberspannungszaehler_CMC03_XIX_BMC_HV_12_XIX_BMC_CAN01:511, compu-method=CM_BMC_Ueberspannungszaehler_CMC03, data-constr=DC_BMC_Ueberspannungszaehler_CMC03, unit=Unit_Unit_None  # Überspannungszähler zum Datenaustausch für redundante Datenspeicherung
          signal BMC_Ueberspannungszaehler_CMC04_XIX_BMC_HV_12_XIX_BMC_CAN01: start 23, 9 bit, little-endian, data-type-policy=OVERRIDE, i-signal-type=PRIMITIVE, init-value=510, base-type=BT_BMC_Ueberspannungszaehler_CMC04, invalid-value=Invalid_BMC_Ueberspannungszaehler_CMC04_XIX_BMC_HV_12_XIX_BMC_CAN01:511, compu-method=CM_BMC_Ueberspannungszaehler_CMC04, data-constr=DC_BMC_Ueberspannungszaehler_CMC04, unit=Unit_Unit_None  # Überspannungszähler zum Datenaustausch für redundante Datenspeicherung
          signal BMC_Uebertemperaturzaehler_CMC03_XIX_BMC_HV_12_XIX_BMC_CAN01: start 32, 16 bit, little-endian, data-type-policy=OVERRIDE, i-signal-type=PRIMITIVE, init-value=65534, base-type=BT_BMC_Uebertemperaturzaehler_CMC03, invalid-value=Invalid_BMC_Uebertemperaturzaehler_CMC03_XIX_BMC_HV_12_XIX_BMC_CAN01:65535, compu-method=CM_BMC_Uebertemperaturzaehler_CMC03, data-constr=DC_BMC_Uebertemperaturzaehler_CMC03, unit=Unit_Unit_Ohm  # Übertemperaturzähler zum Datenaustausch für redundante Datenspeicherung
          signal BMC_Uebertemperaturzaehler_CMC04_XIX_BMC_HV_12_XIX_BMC_CAN01: start 48, 16 bit, little-endian, data-type-policy=OVERRIDE, i-signal-type=PRIMITIVE, init-value=65534, base-type=BT_BMC_Uebertemperaturzaehler_CMC04, invalid-value=Invalid_BMC_Uebertemperaturzaehler_CMC04_XIX_BMC_HV_12_XIX_BMC_CAN01:65535, compu-method=CM_BMC_Uebertemperaturzaehler_CMC04, data-constr=DC_BMC_Uebertemperaturzaehler_CMC04, unit=Unit_Unit_None  # Übertemperaturzähler zum Datenaustausch für redundante Datenspeicherung
          mapping SG_BMC_HV_12_XIX_BMC_CAN01: i-signal-group=SG_BMC_HV_12_XIX_BMC_CAN01, transfer-property=TRIGGERED-WITHOUT-REPETITION
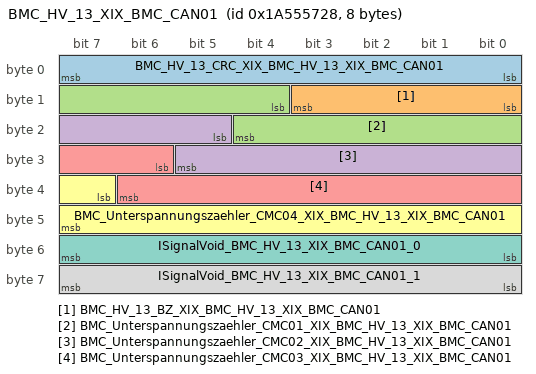
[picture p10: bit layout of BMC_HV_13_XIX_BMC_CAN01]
      frame BMC_HV_13_XIX_BMC_CAN01: id 0x1A555728, from BMC_HV, frame-length=8, can-addressing-mode=EXTENDED, can-frame-rx-behavior=CAN-20, can-frame-tx-behavior=CAN-20
        pdu BMC_HV_13_XIX_BMC_CAN01_E2E: length=8, transmission-mode-true-timing=event-controlled-timing={number-of-repetitions=0, repetition-period=0}, unused-bit-pattern=0
          signal BMC_HV_13_CRC_XIX_BMC_HV_13_XIX_BMC_CAN01: start 0, 8 bit, little-endian, data-type-policy=OVERRIDE, i-signal-type=PRIMITIVE, init-value=0, base-type=BT_BMC_HV_13_CRC
          signal BMC_HV_13_BZ_XIX_BMC_HV_13_XIX_BMC_CAN01: start 8, 4 bit, little-endian, data-type-policy=OVERRIDE, i-signal-type=PRIMITIVE, init-value=0, base-type=BT_BMC_HV_13_BZ
          signal BMC_Unterspannungszaehler_CMC01_XIX_BMC_HV_13_XIX_BMC_CAN01: start 12, 9 bit, little-endian, data-type-policy=OVERRIDE, i-signal-type=PRIMITIVE, init-value=510, base-type=BT_BMC_Unterspannungszaehler_CMC01, invalid-value=Invalid_BMC_Unterspannungszaehler_CMC01_XIX_BMC_HV_13_XIX_BMC_CAN01:511, compu-method=CM_BMC_Unterspannungszaehler_CMC01, data-constr=DC_BMC_Unterspannungszaehler_CMC01, unit=Unit_Unit_None  # Unterspannungszähler zum Datenaustausch für redundante Datenspeicherung
          signal BMC_Unterspannungszaehler_CMC02_XIX_BMC_HV_13_XIX_BMC_CAN01: start 21, 9 bit, little-endian, data-type-policy=OVERRIDE, i-signal-type=PRIMITIVE, init-value=510, base-type=BT_BMC_Unterspannungszaehler_CMC02, invalid-value=Invalid_BMC_Unterspannungszaehler_CMC02_XIX_BMC_HV_13_XIX_BMC_CAN01:511, compu-method=CM_BMC_Unterspannungszaehler_CMC02, data-constr=DC_BMC_Unterspannungszaehler_CMC02, unit=Unit_Unit_None  # Unterspannungszähler zum Datenaustausch für redundante Datenspeicherung
          signal BMC_Unterspannungszaehler_CMC03_XIX_BMC_HV_13_XIX_BMC_CAN01: start 30, 9 bit, little-endian, data-type-policy=OVERRIDE, i-signal-type=PRIMITIVE, init-value=510, base-type=BT_BMC_Unterspannungszaehler_CMC03, invalid-value=Invalid_BMC_Unterspannungszaehler_CMC03_XIX_BMC_HV_13_XIX_BMC_CAN01:511, compu-method=CM_BMC_Unterspannungszaehler_CMC03, data-constr=DC_BMC_Unterspannungszaehler_CMC03, unit=Unit_Unit_None  # Unterspannungszähler zum Datenaustausch für redundante Datenspeicherung
          signal BMC_Unterspannungszaehler_CMC04_XIX_BMC_HV_13_XIX_BMC_CAN01: start 39, 9 bit, little-endian, data-type-policy=OVERRIDE, i-signal-type=PRIMITIVE, init-value=510, base-type=BT_BMC_Unterspannungszaehler_CMC04, invalid-value=Invalid_BMC_Unterspannungszaehler_CMC04_XIX_BMC_HV_13_XIX_BMC_CAN01:511, compu-method=CM_BMC_Unterspannungszaehler_CMC04, data-constr=DC_BMC_Unterspannungszaehler_CMC04, unit=Unit_Unit_None  # Unterspannungszähler zum Datenaustausch für redundante Datenspeicherung
          signal ISignalVoid_BMC_HV_13_XIX_BMC_CAN01_0: start 48, 8 bit, little-endian, system signal SignalVoid_BMC_HV_13_0, data-type-policy=OVERRIDE, i-signal-type=PRIMITIVE, base-type=BT_SignalVoid
          signal ISignalVoid_BMC_HV_13_XIX_BMC_CAN01_1: start 56, 8 bit, little-endian, system signal SignalVoid_BMC_HV_13_1, data-type-policy=OVERRIDE, i-signal-type=PRIMITIVE, base-type=BT_SignalVoid
          mapping SG_BMC_HV_13_XIX_BMC_CAN01: i-signal-group=SG_BMC_HV_13_XIX_BMC_CAN01, transfer-property=TRIGGERED-WITHOUT-REPETITION
      frame ClampControl_01_XIX_BMC_CAN01: id 0x12DD54FE, from BMC_HV, frame-length=8, can-addressing-mode=EXTENDED, can-frame-rx-behavior=CAN-20, can-frame-tx-behavior=CAN-20
        pdu ClampControl_01_XIX_BMC_CAN01: length=8, minimum-delay=0.01, transmission-mode-true-timing={cyclic-timing={time-offset=0, time-period=0.1}, event-controlled-timing={number-of-repetitions=0, repetition-period=0}}, unused-bit-pattern=0
          signal ClampControl_01_CRC_XIX_ClampControl_01_XIX_BMC_CAN01: start 0, 8 bit, little-endian, data-type-policy=OVERRIDE, i-signal-type=PRIMITIVE, init-value=0, base-type=BT_ClampControl_01_CRC, compu-method=CM_ClampControl_01_CRC, data-constr=DC_ClampControl_01_CRC, transfer-property=PENDING  # Für MLB: Berechnung siehe Lastenheft "Kommunikationsabsicherung für FlexRay und CAN" Ab MQB und MLBevo: Berechnung siehe Lastenheft "End-to-End Kommunikationsabsicherung" Endwerte siehe Begleitdokument "S-PDU Kennungsfolgen"
          signal ClampControl_01_BZ_XIX_ClampControl_01_XIX_BMC_CAN01: start 8, 4 bit, little-endian, data-type-policy=OVERRIDE, i-signal-type=PRIMITIVE, init-value=0, base-type=BT_ClampControl_01_BZ, compu-method=CM_ClampControl_01_BZ, data-constr=DC_ClampControl_01_BZ, transfer-property=PENDING  # 4bit Botschaftszähler, wird mit jeder Sendebotschaft inkrementiert
          signal KST_Warn_P1_ZAT_def_XIX_ClampControl_01_XIX_BMC_CAN01: start 12, 1 bit, little-endian, data-type-policy=OVERRIDE, i-signal-type=PRIMITIVE, init-value=0, base-type=BT_KST_Warn_P1_ZAT_def, compu-method=CM_KST_Warn_P1_ZAT_def, data-constr=DC_KST_Warn_P1_ZAT_def, transfer-property=TRIGGERED-ON-CHANGE-WITHOUT-REPETITION  # Kombi Prio Warnung Klemmensteuerung Zündschloß defekt, Service aufsuchen!
          signal KST_Warn_P2_ZAT_def_XIX_ClampControl_01_XIX_BMC_CAN01: start 13, 1 bit, little-endian, data-type-policy=OVERRIDE, i-signal-type=PRIMITIVE, init-value=0, base-type=BT_KST_Warn_P2_ZAT_def, compu-method=CM_KST_Warn_P2_ZAT_def, data-constr=DC_KST_Warn_P2_ZAT_def, transfer-property=TRIGGERED-ON-CHANGE-WITHOUT-REPETITION  # Kombi Prio Warnung Klemmensteuerung Zündschloß defekt!
          signal KST_Deaktivierungs_Trigger_XIX_ClampControl_01_XIX_BMC_CAN01: start 14, 2 bit, little-endian, data-type-policy=OVERRIDE, i-signal-type=PRIMITIVE, init-value=0, base-type=BT_KST_Deaktivierungs_Trigger, compu-method=CM_KST_Deaktivierungs_Trigger, data-constr=DC_KST_Deaktivierungs_Trigger, transfer-property=TRIGGERED-ON-CHANGE-WITHOUT-REPETITION  # Ausgabe des Deaktivierungstriggers für Funktionen mit Goodbye-Szenario zur Unterscheidung zwischen manueller und automatischer Deaktivierung bei Fzg.-Verlassen
          signal KST_Kl_S_XIX_ClampControl_01_XIX_BMC_CAN01: start 16, 1 bit, little-endian, data-type-policy=OVERRIDE, i-signal-type=PRIMITIVE, init-value=0, base-type=BT_KST_Kl_S, compu-method=CM_KST_Kl_S, data-constr=DC_KST_Kl_S, transfer-property=TRIGGERED-ON-CHANGE-WITHOUT-REPETITION  # Klemme S: S-Kontakt (Schluessel steckt)
          signal KST_KL_15_XIX_ClampControl_01_XIX_BMC_CAN01: start 17, 1 bit, little-endian, data-type-policy=OVERRIDE, i-signal-type=PRIMITIVE, init-value=0, base-type=BT_KST_KL_15, compu-method=CM_KST_KL_15, data-constr=DC_KST_KL_15, transfer-property=TRIGGERED-ON-CHANGE-WITHOUT-REPETITION  # Klemme 15: Zuendung (SW-Kl.15)
          signal KST_Kl_50_Startanforderung_XIX_ClampControl_01_XIX_BMC_CAN01: start 18, 1 bit, little-endian, data-type-policy=OVERRIDE, i-signal-type=PRIMITIVE, init-value=0, base-type=BT_KST_Kl_50_Startanforderung, compu-method=CM_KST_Kl_50_Startanforderung, data-constr=DC_KST_Kl_50_Startanforderung, transfer-property=TRIGGERED-ON-CHANGE-WITHOUT-REPETITION  # Klemme 50: Startwunsch Fahrer
          signal KST_Sonderzustand_Status_XIX_ClampControl_01_XIX_BMC_CAN01: start 19, 2 bit, little-endian, data-type-policy=OVERRIDE, i-signal-type=PRIMITIVE, init-value=0, base-type=BT_KST_Sonderzustand_Status, invalid-value=Invalid_KST_Sonderzustand_Status_XIX_ClampControl_01_XIX_BMC_CAN01:3, compu-method=CM_KST_Sonderzustand_Status, data-constr=DC_KST_Sonderzustand_Status, transfer-property=TRIGGERED-ON-CHANGE-WITHOUT-REPETITION  # Hiermit wird signalisiert, dass eine Sonderfunktion aktiv ist und die Klemme 15 durch diese angefordert wurde bzw. ein Übergang von Sonderfunktionen stattfindet
          signal KST_Ausstiegswunsch_Status_XIX_ClampControl_01_XIX_BMC_CAN01: start 21, 1 bit, little-endian, data-type-policy=OVERRIDE, i-signal-type=PRIMITIVE, init-value=0, base-type=BT_KST_Ausstiegswunsch_Status, compu-method=CM_KST_Ausstiegswunsch_Status, data-constr=DC_KST_Ausstiegswunsch_Status, transfer-property=TRIGGERED-ON-CHANGE-WITHOUT-REPETITION  # Ausstiegswunsch über den Funktionen mit Goodbye-Szenario zentral getriggert werden können.
          signal KST_BulbCheckReq_XIX_ClampControl_01_XIX_BMC_CAN01: start 23, 1 bit, little-endian, data-type-policy=OVERRIDE, i-signal-type=PRIMITIVE, init-value=0, base-type=BT_KST_BulbCheckReq, compu-method=CM_KST_BulbCheckReq, data-constr=DC_KST_BulbCheckReq, transfer-property=TRIGGERED-ON-CHANGE-WITHOUT-REPETITION  # Signal fordert eine Lampenaufprüfung (Bulb Check) an.
          signal KST_Kl_X_XIX_ClampControl_01_XIX_BMC_CAN01: start 24, 1 bit, little-endian, data-type-policy=OVERRIDE, i-signal-type=PRIMITIVE, init-value=0, base-type=BT_KST_Kl_X, compu-method=CM_KST_Kl_X, data-constr=DC_KST_Kl_X, transfer-property=TRIGGERED-ON-CHANGE-WITHOUT-REPETITION  # Ausgabe der Klemme 75 aus Kompatibilitätsgründen für COP-Übernahmen aus MEB.
          signal KST_Ausparken_Betrieb_XIX_ClampControl_01_XIX_BMC_CAN01: start 25, 1 bit, little-endian, data-type-policy=OVERRIDE, i-signal-type=PRIMITIVE, init-value=0, base-type=BT_KST_Ausparken_Betrieb, compu-method=CM_KST_Ausparken_Betrieb, data-constr=DC_KST_Ausparken_Betrieb, transfer-property=TRIGGERED-ON-CHANGE-WITHOUT-REPETITION  # Anforderung zur erneuten Lampenaufprüfung und Anzeige von Warnhinweisen nach einem pilotierten Ausparkvorgang (Trigger: fallende Flanke)
          signal KST_Fahrerhinweis_1_XIX_ClampControl_01_XIX_BMC_CAN01: start 26, 1 bit, little-endian, data-type-policy=OVERRIDE, i-signal-type=PRIMITIVE, init-value=0, base-type=BT_KST_Fahrerhinweis_1, compu-method=CM_KST_Fahrerhinweis_1, data-constr=DC_KST_Fahrerhinweis_1, transfer-property=TRIGGERED-ON-CHANGE-WITHOUT-REPETITION  # Signalisierung Fahrerhinweis 1 der Klemmensteuerung an das Kombi
          signal KST_Fahrerhinweis_2_XIX_ClampControl_01_XIX_BMC_CAN01: start 27, 1 bit, little-endian, data-type-policy=OVERRIDE, i-signal-type=PRIMITIVE, init-value=0, base-type=BT_KST_Fahrerhinweis_2, compu-method=CM_KST_Fahrerhinweis_2, data-constr=DC_KST_Fahrerhinweis_2, transfer-property=TRIGGERED-ON-CHANGE-WITHOUT-REPETITION  # Signalisierung Fahrerhinweis 2 der Klemmensteuerung an das Kombi
          signal KST_Fahrerhinweis_3_XIX_ClampControl_01_XIX_BMC_CAN01: start 28, 1 bit, little-endian, data-type-policy=OVERRIDE, i-signal-type=PRIMITIVE, init-value=0, base-type=BT_KST_Fahrerhinweis_3, compu-method=CM_KST_Fahrerhinweis_3, data-constr=DC_KST_Fahrerhinweis_3, transfer-property=TRIGGERED-ON-CHANGE-WITHOUT-REPETITION  # Signalisierung Fahrerhinweis 3 der Klemmensteuerung an das Kombi
          signal KST_Fahrerhinweis_4_XIX_ClampControl_01_XIX_BMC_CAN01: start 29, 1 bit, little-endian, data-type-policy=OVERRIDE, i-signal-type=PRIMITIVE, init-value=0, base-type=BT_KST_Fahrerhinweis_4, compu-method=CM_KST_Fahrerhinweis_4, data-constr=DC_KST_Fahrerhinweis_4, transfer-property=TRIGGERED-ON-CHANGE-WITHOUT-REPETITION  # Signalisierung Fahrerhinweis 4 der Klemmensteuerung an das Kombi
          signal KST_Fahrerhinweis_5_XIX_ClampControl_01_XIX_BMC_CAN01: start 30, 1 bit, little-endian, data-type-policy=OVERRIDE, i-signal-type=PRIMITIVE, init-value=0, base-type=BT_KST_Fahrerhinweis_5, compu-method=CM_KST_Fahrerhinweis_5, data-constr=DC_KST_Fahrerhinweis_5, transfer-property=TRIGGERED-ON-CHANGE-WITHOUT-REPETITION  # Anzeigesignal für RemoteStart
          signal KST_Fahrerhinweis_6_XIX_ClampControl_01_XIX_BMC_CAN01: start 31, 1 bit, little-endian, data-type-policy=OVERRIDE, i-signal-type=PRIMITIVE, init-value=0, base-type=BT_KST_Fahrerhinweis_6, compu-method=CM_KST_Fahrerhinweis_6, data-constr=DC_KST_Fahrerhinweis_6, transfer-property=TRIGGERED-ON-CHANGE-WITHOUT-REPETITION  # Signal aktiviert die Kombi-Anzeigeinstrumente (Drehzahl, Tankinhalt, Kühlmitteltemperatur) während aktiviertem RemoteStart-Betrieb
          signal KST_Txt_Panikabschaltung_XIX_ClampControl_01_XIX_BMC_CAN01: start 34, 1 bit, little-endian, data-type-policy=OVERRIDE, i-signal-type=PRIMITIVE, init-value=0, base-type=BT_KST_Txt_Panikabschaltung, compu-method=CM_KST_Txt_Panikabschaltung, data-constr=DC_KST_Txt_Panikabschaltung, transfer-property=TRIGGERED-ON-CHANGE-WITHOUT-REPETITION  # Text: 'Notabschaltung''
          signal KST_Anf_Klemmenfreigabe_ELV_XIX_ClampControl_01_XIX_BMC_CAN01: start 41, 1 bit, little-endian, data-type-policy=OVERRIDE, i-signal-type=PRIMITIVE, init-value=0, base-type=BT_KST_Anf_Klemmenfreigabe_ELV, compu-method=CM_KST_Anf_Klemmenfreigabe_ELV, data-constr=DC_KST_Anf_Klemmenfreigabe_ELV, transfer-property=PENDING  # Klemmensteuerung fordert Klemmen-Freigabe durch die ELV an.
          signal KST_aut_Abschaltung_Zuendung_XIX_ClampControl_01_XIX_BMC_CAN01: start 42, 1 bit, little-endian, data-type-policy=OVERRIDE, i-signal-type=PRIMITIVE, init-value=0, base-type=BT_KST_aut_Abschaltung_Zuendung, compu-method=CM_KST_aut_Abschaltung_Zuendung, data-constr=DC_KST_aut_Abschaltung_Zuendung, transfer-property=TRIGGERED-ON-CHANGE-WITHOUT-REPETITION  # Falls bei eingeschalteter Zündung das Abblendlicht aktiv war, muss nach der automatischen Abschaltung der Kl_15 & Kl_S, dass Standlicht aktiv bleiben. Das Signal sendet die Information, dass eine automatische Abschaltung der Kl_15 und Kl_S erfogt.
          signal KST_StPtAcvReq_XIX_ClampControl_01_XIX_BMC_CAN01: start 43, 2 bit, little-endian, data-type-policy=OVERRIDE, i-signal-type=PRIMITIVE, init-value=0, base-type=BT_KST_StPtAcvReq, compu-method=CM_KST_StPtAcvReq, data-constr=DC_KST_StPtAcvReq, transfer-property=TRIGGERED-ON-CHANGE-WITHOUT-REPETITION  # ZAT-activation-demand
          signal KST_StPtDeacReq_XIX_ClampControl_01_XIX_BMC_CAN01: start 45, 1 bit, little-endian, data-type-policy=OVERRIDE, i-signal-type=PRIMITIVE, init-value=0, base-type=BT_KST_StPtDeacReq, compu-method=CM_KST_StPtDeacReq, data-constr=DC_KST_StPtDeacReq, transfer-property=TRIGGERED-ON-CHANGE-WITHOUT-REPETITION  # Anforderung Deaktivierung des Antriebsstrangs durch Klemmensteuerung
          signal KST_ZAT_betaetigt_XIX_ClampControl_01_XIX_BMC_CAN01: start 46, 1 bit, little-endian, data-type-policy=OVERRIDE, i-signal-type=PRIMITIVE, init-value=0, base-type=BT_KST_ZAT_betaetigt, compu-method=CM_KST_ZAT_betaetigt, data-constr=DC_KST_ZAT_betaetigt, transfer-property=TRIGGERED-ON-CHANGE-WITHOUT-REPETITION  # Zündanlass-Taster (ZAT) betätigt
          signal KST_ComfortReadyStatus_XIX_ClampControl_01_XIX_BMC_CAN01: start 47, 1 bit, little-endian, data-type-policy=OVERRIDE, i-signal-type=PRIMITIVE, init-value=0, base-type=BT_KST_ComfortReadyStatus, compu-method=CM_KST_ComfortReadyStatus, data-constr=DC_KST_ComfortReadyStatus, transfer-property=TRIGGERED-ON-CHANGE-WITHOUT-REPETITION  # Zustand des ComfortReadyStatus über den Komfortfunktionen aktiviert werden können.
          signal KST_Sonderzustand_Anforderung_XIX_ClampControl_01_XIX_BMC_CAN01: start 48, 5 bit, little-endian, data-type-policy=OVERRIDE, i-signal-type=PRIMITIVE, init-value=0, base-type=BT_KST_Sonderzustand_Anforderung, invalid-value=Invalid_KST_Sonderzustand_Anforderung_XIX_ClampControl_01_XIX_BMC_CAN01:31, compu-method=CM_KST_Sonderzustand_Anforderung, data-constr=DC_KST_Sonderzustand_Anforderung, transfer-property=TRIGGERED-ON-CHANGE-WITHOUT-REPETITION  # Hiermit wird die aktive bzw. aktuell angeforderte (s. KST_Sonderzustand_Status) Sonderfunktion identifiziert
          signal KST_WFS_Fahrfreigabe_Anforderung_XIX_ClampControl_01_XIX_BMC_CAN01: start 53, 2 bit, little-endian, data-type-policy=OVERRIDE, i-signal-type=PRIMITIVE, init-value=0, base-type=BT_KST_WFS_Fahrfreigabe_Anforderung, compu-method=CM_KST_WFS_Fahrfreigabe_Anforderung, data-constr=DC_KST_WFS_Fahrfreigabe_Anforderung, transfer-property=TRIGGERED-ON-CHANGE-WITHOUT-REPETITION  # Hiermit wird den Wegfahrsperren-Teilnehmern signalisiert welche Art der Fahrfreigabe von der anfordernden Sonderfunktion benötigt wird
      frame DEV_BJB_Req_01_XIX_BMC_CAN01: id 0x18FED000, from BMC_HV, frame-length=8, can-addressing-mode=EXTENDED, can-frame-rx-behavior=CAN-20, can-frame-tx-behavior=CAN-20
        user defined pdu CDD_DEV_BJB_Req_01_XIX_BMC_CAN01: length=8, cdd-type=EID
      frame DEV_BJB_Resp_FF_XIX_BMC_CAN01: id 0x18FED0FF, to BMC_HV, frame-length=8, can-addressing-mode=EXTENDED, can-frame-rx-behavior=CAN-20, can-frame-tx-behavior=CAN-20
        user defined pdu CDD_DEV_BJB_Resp_FF_XIX_BMC_CAN01: length=8, cdd-type=EID
      frame DEV_BMS_Resp_00_XIX_BMC_CAN01: id 0x1BFFDA00, to BMC_HV, frame-length=8, can-addressing-mode=EXTENDED, can-frame-rx-behavior=CAN-20, can-frame-tx-behavior=CAN-20
        user defined pdu CDD_DEV_BMS_Resp_00_XIX_BMC_CAN01: length=8, cdd-type=EID
      frame DEV_BMS_Resp_01_XIX_BMC_CAN01: id 0x1BFFDA01, to BMC_HV, frame-length=8, can-addressing-mode=EXTENDED, can-frame-rx-behavior=CAN-20, can-frame-tx-behavior=CAN-20
        user defined pdu CDD_DEV_BMS_Resp_01_XIX_BMC_CAN01: length=8, cdd-type=EID
      frame DEV_BMS_Resp_176_XIX_BMC_CAN01: id 0x1BFFDAB0, to BMC_HV, frame-length=8, can-addressing-mode=EXTENDED, can-frame-rx-behavior=CAN-20, can-frame-tx-behavior=CAN-20
        user defined pdu CDD_DEV_BMS_Resp_176_XIX_BMC_CAN01: length=8, cdd-type=EID
      frame DEV_BMS_Resp_177_XIX_BMC_CAN01: id 0x1BFFDAB1, to BMC_HV, frame-length=8, can-addressing-mode=EXTENDED, can-frame-rx-behavior=CAN-20, can-frame-tx-behavior=CAN-20
        user defined pdu CDD_DEV_BMS_Resp_177_XIX_BMC_CAN01: length=8, cdd-type=EID
      frame DEV_BMS_Resp_178_XIX_BMC_CAN01: id 0x1BFFDAB2, to BMC_HV, frame-length=8, can-addressing-mode=EXTENDED, can-frame-rx-behavior=CAN-20, can-frame-tx-behavior=CAN-20
        user defined pdu CDD_DEV_BMS_Resp_178_XIX_BMC_CAN01: length=8, cdd-type=EID
      frame DEV_BMS_Resp_192_XIX_BMC_CAN01: id 0x1BFFDAC0, to BMC_HV, frame-length=8, can-addressing-mode=EXTENDED, can-frame-rx-behavior=CAN-20, can-frame-tx-behavior=CAN-20
        user defined pdu CDD_DEV_BMS_Resp_192_XIX_BMC_CAN01: length=8, cdd-type=EID
      frame DEV_BMS_Resp_193_XIX_BMC_CAN01: id 0x1BFFDAC1, to BMC_HV, frame-length=8, can-addressing-mode=EXTENDED, can-frame-rx-behavior=CAN-20, can-frame-tx-behavior=CAN-20
        user defined pdu CDD_DEV_BMS_Resp_193_XIX_BMC_CAN01: length=8, cdd-type=EID
      frame DEV_BMS_Resp_194_XIX_BMC_CAN01: id 0x1BFFDAC2, to BMC_HV, frame-length=8, can-addressing-mode=EXTENDED, can-frame-rx-behavior=CAN-20, can-frame-tx-behavior=CAN-20
        user defined pdu CDD_DEV_BMS_Resp_194_XIX_BMC_CAN01: length=8, cdd-type=EID
      frame DIA_BJB_Req_XIX_BMC_CAN01: id 0x17FC16D0, from BMC_HV, frame-length=8, can-addressing-mode=EXTENDED, can-frame-rx-behavior=CAN-20, can-frame-tx-behavior=CAN-20
        n pdu DIA_BJB_Req_XIX_BMC_CAN01: length=8
      frame DIA_BJB_Resp_XIX_BMC_CAN01: id 0x17FE16D0, to BMC_HV, frame-length=8, can-addressing-mode=EXTENDED, can-frame-rx-behavior=CAN-20, can-frame-tx-behavior=CAN-20
        n pdu DIA_BJB_Resp_XIX_BMC_CAN01: length=8
      frame DIA_UI2Sens01_Req_XIX_BMC_CAN01: id 0x17FC17B1, from BMC_HV, frame-length=8, can-addressing-mode=EXTENDED, can-frame-rx-behavior=CAN-20, can-frame-tx-behavior=CAN-20
        n pdu DIA_UI2Sens01_Req_XIX_BMC_CAN01: length=8
      frame DIA_UI2Sens01_Resp_XIX_BMC_CAN01: id 0x17FE17B1, to BMC_HV, frame-length=8, can-addressing-mode=EXTENDED, can-frame-rx-behavior=CAN-20, can-frame-tx-behavior=CAN-20
        n pdu DIA_UI2Sens01_Resp_XIX_BMC_CAN01: length=8
      frame DIA_UI2Sens02_Req_XIX_BMC_CAN01: id 0x17FC17B2, from BMC_HV, frame-length=8, can-addressing-mode=EXTENDED, can-frame-rx-behavior=CAN-20, can-frame-tx-behavior=CAN-20
        n pdu DIA_UI2Sens02_Req_XIX_BMC_CAN01: length=8
      frame DIA_UI2Sens02_Resp_XIX_BMC_CAN01: id 0x17FE17B2, to BMC_HV, frame-length=8, can-addressing-mode=EXTENDED, can-frame-rx-behavior=CAN-20, can-frame-tx-behavior=CAN-20
        n pdu DIA_UI2Sens02_Resp_XIX_BMC_CAN01: length=8
      frame ISO_Funktionaler_Req_All_XIX_BMC_CAN01: id 0x700, from BMC_HV, frame-length=8, can-addressing-mode=STANDARD, can-frame-rx-behavior=CAN-20, can-frame-tx-behavior=CAN-20
        n pdu ISO_Funktionaler_Req_All_XIX_BMC_CAN01: length=8
      frame NM_Dummy01_XIX_BMC_CAN01: id 0x1B0003FF, to BMC_HV, frame-length=8, can-addressing-mode=EXTENDED, can-frame-rx-behavior=CAN-20, can-frame-tx-behavior=CAN-20, rx-identifier-range={lower-can-id=452984832, upper-can-id=452985855}
        nm pdu NM_Dummy01_XIX_BMC_CAN01: length=8, unused-bit-pattern=0
          signal NM_Dummy01_CBV_AWB_XIX_NM_Dummy01_XIX_BMC_CAN01: start 12, 1 bit, little-endian, data-type-policy=OVERRIDE, i-signal-type=PRIMITIVE, init-value=0, base-type=BT_NM_Dummy01_CBV_AWB, compu-method=CM_NM_Dummy01_CBV_AWB, data-constr=DC_NM_Dummy01_CBV_AWB, transfer-property=TRIGGERED  # Das Signal ist zu setzen, wenn das SG aktiv den Bus geweckt hat 0 = Passiver_WakeUp = SG hat das Netzwerk nicht aktiv geweckt 1 = Akitiver_WakeUp = SG hat das Netzwerk aktiv geweckt
          signal NM_Dummy01_CBV_CRI_XIX_NM_Dummy01_XIX_BMC_CAN01: start 14, 1 bit, little-endian, data-type-policy=OVERRIDE, i-signal-type=PRIMITIVE, init-value=0, base-type=BT_NM_Dummy01_CBV_CRI, compu-method=CM_NM_Dummy01_CBV_CRI, data-constr=DC_NM_Dummy01_CBV_CRI, transfer-property=TRIGGERED  # Das Signal ist dauerhaft gesetzt, wenn das NM-Layout Cluster- Anforderungen enthält
          signal NM_Dummy01_NM_State_XIX_NM_Dummy01_XIX_BMC_CAN01: start 16, 6 bit, little-endian, data-type-policy=OVERRIDE, i-signal-type=PRIMITIVE, init-value=0, base-type=BT_NM_Dummy01_NM_State, compu-method=CM_NM_Dummy01_NM_State, data-constr=DC_NM_Dummy01_NM_State, transfer-property=TRIGGERED, to BMC_HV(timeout 2 s)  # 1 = Zustand Repeat Message (<-- Bus-Sleep Mode) 2 = Zustand Repeat Message (<-- Prepare Bus-Sleep Mode) 4 = Zustand Normal Operation (<-- Repeat Message) 8 = Zustand Normal Operation (<-- Ready Sleep)
          signal NM_Dummy01_CAB_XIX_NM_Dummy01_XIX_BMC_CAN01: start 40, 24 bit, opaque, data-type-policy=OVERRIDE, i-signal-type=ARRAY, init-value=[0, 0, 0], base-type=BT_NM_Dummy01_CAB, compu-method=CM_NM_Dummy01_CAB, data-constr=DC_NM_Dummy01_CAB, transfer-property=TRIGGERED-ON-CHANGE  # CAB = Clusteraktivbits
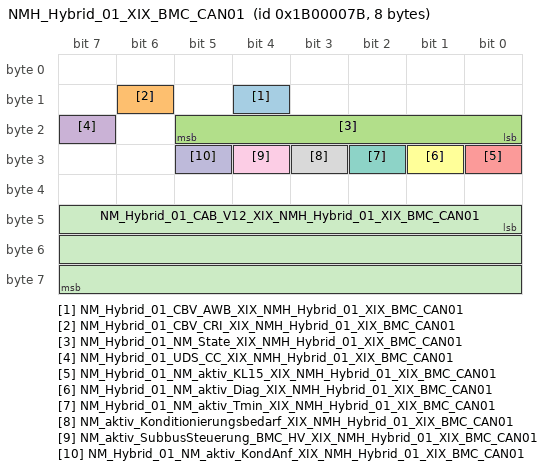
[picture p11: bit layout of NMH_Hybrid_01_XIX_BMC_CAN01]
      frame NMH_Hybrid_01_XIX_BMC_CAN01: id 0x1B00007B, from BMC_HV, frame-length=8, can-addressing-mode=EXTENDED, can-frame-rx-behavior=CAN-20, can-frame-tx-behavior=CAN-20, rx-identifier-range={lower-can-id=452984832, upper-can-id=452985855}
        nm pdu NMH_Hybrid_01_XIX_BMC_CAN01: length=8, unused-bit-pattern=0
          signal NM_Hybrid_01_CBV_AWB_XIX_NMH_Hybrid_01_XIX_BMC_CAN01: start 12, 1 bit, little-endian, data-type-policy=OVERRIDE, i-signal-type=PRIMITIVE, init-value=0, base-type=BT_NM_Hybrid_01_CBV_AWB, compu-method=CM_NM_Hybrid_01_CBV_AWB, data-constr=DC_NM_Hybrid_01_CBV_AWB, transfer-property=TRIGGERED  # Das Signal ist zu setzen, wenn das SG aktiv den Bus geweckt hat 0 = Passiver_WakeUp = SG hat das Netzwerk nicht aktiv geweckt 1 = Akitiver_WakeUp = SG hat das Netzwerk aktiv geweckt
          signal NM_Hybrid_01_CBV_CRI_XIX_NMH_Hybrid_01_XIX_BMC_CAN01: start 14, 1 bit, little-endian, data-type-policy=OVERRIDE, i-signal-type=PRIMITIVE, init-value=1, base-type=BT_NM_Hybrid_01_CBV_CRI, compu-method=CM_NM_Hybrid_01_CBV_CRI, data-constr=DC_NM_Hybrid_01_CBV_CRI, transfer-property=TRIGGERED  # Das Signal ist dauerhaft gesetzt, wenn das NM-Layout Cluster- Anforderungen enthält
          signal NM_Hybrid_01_NM_State_XIX_NMH_Hybrid_01_XIX_BMC_CAN01: start 16, 6 bit, little-endian, data-type-policy=OVERRIDE, i-signal-type=PRIMITIVE, init-value=0, base-type=BT_NM_Hybrid_01_NM_State, compu-method=CM_NM_Hybrid_01_NM_State, data-constr=DC_NM_Hybrid_01_NM_State, transfer-property=TRIGGERED-ON-CHANGE  # 1 = Zustand Repeat Message (<-- Bus-Sleep Mode) 2 = Zustand Repeat Message (<-- Prepare Bus-Sleep Mode) 4 = Zustand Normal Operation (<-- Repeat Message) 8 = Zustand Normal Operation (<-- Ready Sleep)
          signal NM_Hybrid_01_UDS_CC_XIX_NMH_Hybrid_01_XIX_BMC_CAN01: start 23, 1 bit, little-endian, data-type-policy=OVERRIDE, i-signal-type=PRIMITIVE, init-value=0, base-type=BT_NM_Hybrid_01_UDS_CC, compu-method=CM_NM_Hybrid_01_UDS_CC, data-constr=DC_NM_Hybrid_01_UDS_CC, transfer-property=TRIGGERED  # Funktionseinschränkung aufgrund aktivem UDS-Communication Control, siehe VW80124
          signal NM_Hybrid_01_NM_aktiv_KL15_XIX_NMH_Hybrid_01_XIX_BMC_CAN01: start 24, 1 bit, little-endian, data-type-policy=OVERRIDE, i-signal-type=PRIMITIVE, init-value=0, base-type=BT_NM_Hybrid_01_NM_aktiv_KL15, compu-method=CM_NM_Hybrid_01_NM_aktiv_KL15, data-constr=DC_NM_Hybrid_01_NM_aktiv_KL15, transfer-property=TRIGGERED  # Steuergerät hat KL15-EIN erkannt
          signal NM_Hybrid_01_NM_aktiv_Diag_XIX_NMH_Hybrid_01_XIX_BMC_CAN01: start 25, 1 bit, little-endian, data-type-policy=OVERRIDE, i-signal-type=PRIMITIVE, init-value=0, base-type=BT_NM_Hybrid_01_NM_aktiv_Diag, compu-method=CM_NM_Hybrid_01_NM_aktiv_Diag, data-constr=DC_NM_Hybrid_01_NM_aktiv_Diag, transfer-property=TRIGGERED  # Diagnose befindet sich nach VW80124 in einer NonDefaultDiagnostic-Session, z.B. ExtendedDiagnostic-Session
          signal NM_Hybrid_01_NM_aktiv_Tmin_XIX_NMH_Hybrid_01_XIX_BMC_CAN01: start 26, 1 bit, little-endian, data-type-policy=OVERRIDE, i-signal-type=PRIMITIVE, init-value=0, base-type=BT_NM_Hybrid_01_NM_aktiv_Tmin, compu-method=CM_NM_Hybrid_01_NM_aktiv_Tmin, data-constr=DC_NM_Hybrid_01_NM_aktiv_Tmin, transfer-property=TRIGGERED  # Mindestaktivzeit ist noch nicht abgelaufen (bei jedem Weckereignis wird die Mindestaktivzeit neu gestartet)
          signal NM_aktiv_Konditionierungsbedarf_XIX_NMH_Hybrid_01_XIX_BMC_CAN01: start 27, 1 bit, little-endian, data-type-policy=OVERRIDE, i-signal-type=PRIMITIVE, init-value=0, base-type=BT_NM_aktiv_Konditionierungsbedarf, compu-method=CM_NM_aktiv_Konditionierungsbedarf, data-constr=DC_NM_aktiv_Konditionierungsbedarf, transfer-property=TRIGGERED  # Die Batterie überwacht die Temperatur der Batterie und kann eine Konditionierung fordern.
          signal NM_aktiv_SubbusSteuerung_BMC_HV_XIX_NMH_Hybrid_01_XIX_BMC_CAN01: start 28, 1 bit, little-endian, data-type-policy=OVERRIDE, i-signal-type=PRIMITIVE, init-value=0, base-type=BT_NM_aktiv_SubbusSteuerung_BMC_HV, compu-method=CM_NM_aktiv_SubbusSteuerung_BMC_HV, data-constr=DC_NM_aktiv_SubbusSteuerung_BMC_HV, transfer-property=TRIGGERED  # Wird für die Weiterleitung der Weckanforderungen an den SubCAN benötigt.
          signal NM_Hybrid_01_NM_aktiv_KondAnf_XIX_NMH_Hybrid_01_XIX_BMC_CAN01: start 29, 1 bit, little-endian, data-type-policy=OVERRIDE, i-signal-type=PRIMITIVE, base-type=BT_NM_Hybrid_01_NM_aktiv_KondAnf, compu-method=CM_NM_Hybrid_01_NM_aktiv_KondAnf, data-constr=DC_NM_Hybrid_01_NM_aktiv_KondAnf, transfer-property=TRIGGERED  # Hochvoltbatterie Dauerkonditionierung
          signal NM_Hybrid_01_CAB_V12_XIX_NMH_Hybrid_01_XIX_BMC_CAN01: start 40, 24 bit, opaque, data-type-policy=OVERRIDE, i-signal-type=ARRAY, init-value=[0, 0, 0], base-type=BT_NM_Hybrid_01_CAB_V12, compu-method=CM_NM_Hybrid_01_CAB_V12, data-constr=DC_NM_Hybrid_01_CAB_V12, transfer-property=TRIGGERED  # CAB = Clusteraktivbits
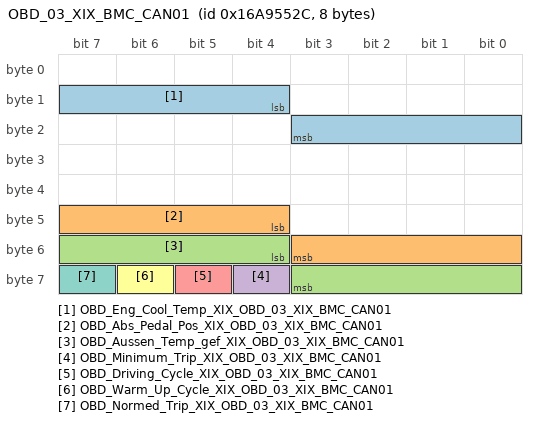
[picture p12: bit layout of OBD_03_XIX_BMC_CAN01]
      frame OBD_03_XIX_BMC_CAN01: id 0x16A9552C, from BMC_HV, frame-length=8, can-addressing-mode=EXTENDED, can-frame-rx-behavior=CAN-20, can-frame-tx-behavior=CAN-20
        pdu OBD_03_XIX_BMC_CAN01: length=8, transmission-mode-true-timing=cyclic-timing={time-offset=0, time-period=0.32}, unused-bit-pattern=0
          signal OBD_Eng_Cool_Temp_XIX_OBD_03_XIX_BMC_CAN01: start 12, 8 bit, little-endian, data-type-policy=OVERRIDE, i-signal-type=PRIMITIVE, init-value=255, base-type=BT_OBD_Eng_Cool_Temp, compu-method=CM_OBD_Eng_Cool_Temp, data-constr=DC_OBD_Eng_Cool_Temp, unit=Unit_Unit_DegreCelsi, transfer-property=PENDING  # Engine Coolant Temperature Übertragung von Meßgrößen an das Getriebesteuergerät für Freeze Frame Abspeicherung bei Getriebefehlern PID $05 Engine Coolant Temperature; -40 .. +215°C mit 1°C/bit und 40°C Offset
          signal OBD_Abs_Pedal_Pos_XIX_OBD_03_XIX_BMC_CAN01: start 44, 8 bit, little-endian, data-type-policy=OVERRIDE, i-signal-type=PRIMITIVE, init-value=255, base-type=BT_OBD_Abs_Pedal_Pos, compu-method=CM_OBD_Abs_Pedal_Pos, data-constr=DC_OBD_Abs_Pedal_Pos, unit=Unit_Unit_PerCent, transfer-property=PENDING  # Absolute Pedal Position Übertragung von Meßgrößen an das Getriebesteuergerät für Freeze Frame Abspeicherung bei Getriebefehlern PID $49 Accelerator Pedal Position D; 0 .. 100% mit 100/255 %/bit
          signal OBD_Aussen_Temp_gef_XIX_OBD_03_XIX_BMC_CAN01: start 52, 8 bit, little-endian, data-type-policy=OVERRIDE, i-signal-type=PRIMITIVE, init-value=254, base-type=BT_OBD_Aussen_Temp_gef, invalid-value=Invalid_OBD_Aussen_Temp_gef_XIX_OBD_03_XIX_BMC_CAN01:255, compu-method=CM_OBD_Aussen_Temp_gef, data-constr=DC_OBD_Aussen_Temp_gef, unit=Unit_Unit_DegreCelsi, transfer-property=PENDING  # Gefilterte Aussentemperatur vom Motor für OBD Funktionen.
          signal OBD_Minimum_Trip_XIX_OBD_03_XIX_BMC_CAN01: start 60, 1 bit, little-endian, data-type-policy=OVERRIDE, i-signal-type=PRIMITIVE, init-value=0, base-type=BT_OBD_Minimum_Trip, compu-method=CM_OBD_Minimum_Trip, data-constr=DC_OBD_Minimum_Trip, transfer-property=PENDING  # Grundlage OBD-Gesetz CCR 1968.2 (d)(4.3) Denominator Specifications Bildung des General Denominator "Normed Trip": 600 sec. (kumulativ) Zeit nach Motorstart 300 sec. (kumulativ) mit Fahrzeuggeschwindigkeit > 25 mph (40 km/h) 30 sec. (kontinuierlich) Leerlauf Wenn alle diese Bedingungen erfüllt wurden ist ein OBD_Min_Normed_Trip erfüllt
          signal OBD_Driving_Cycle_XIX_OBD_03_XIX_BMC_CAN01: start 61, 1 bit, little-endian, data-type-policy=OVERRIDE, i-signal-type=PRIMITIVE, init-value=0, base-type=BT_OBD_Driving_Cycle, compu-method=CM_OBD_Driving_Cycle, data-constr=DC_OBD_Driving_Cycle, transfer-property=PENDING  # Signalisierung Driving Cycle Qualifizierung - Trigger Ignition Cycle Counter
          signal OBD_Warm_Up_Cycle_XIX_OBD_03_XIX_BMC_CAN01: start 62, 1 bit, little-endian, data-type-policy=OVERRIDE, i-signal-type=PRIMITIVE, init-value=0, base-type=BT_OBD_Warm_Up_Cycle, compu-method=CM_OBD_Warm_Up_Cycle, data-constr=DC_OBD_Warm_Up_Cycle, transfer-property=PENDING  # Mit dem Warm-Up-Cycle wird der zentrale Verlernzähler vom Gateway inkrementiert
          signal OBD_Normed_Trip_XIX_OBD_03_XIX_BMC_CAN01: start 63, 1 bit, little-endian, data-type-policy=OVERRIDE, i-signal-type=PRIMITIVE, init-value=0, base-type=BT_OBD_Normed_Trip, compu-method=CM_OBD_Normed_Trip, data-constr=DC_OBD_Normed_Trip, transfer-property=PENDING  # Gesetzlich definierte "Normed Condition" erfüllt, "General Denominator" darf erhöht werden
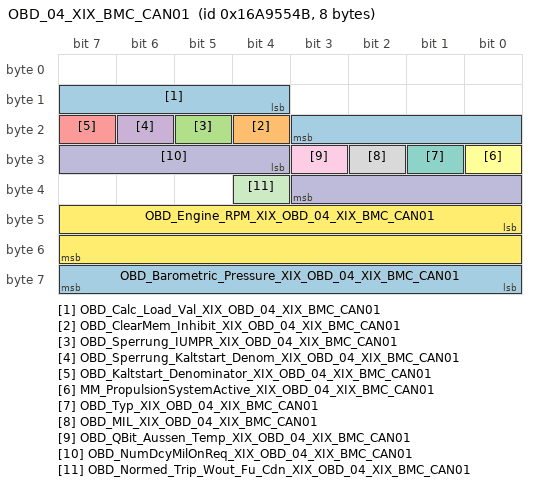
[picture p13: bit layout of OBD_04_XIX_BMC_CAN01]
      frame OBD_04_XIX_BMC_CAN01: id 0x16A9554B, from BMC_HV, frame-length=8, can-addressing-mode=EXTENDED, can-frame-rx-behavior=CAN-20, can-frame-tx-behavior=CAN-20
        pdu OBD_04_XIX_BMC_CAN01: length=8, minimum-delay=0.08, transmission-mode-true-timing={cyclic-timing={time-offset=0, time-period=0.32}, event-controlled-timing={number-of-repetitions=0, repetition-period=0}}, unused-bit-pattern=0
          signal OBD_Calc_Load_Val_XIX_OBD_04_XIX_BMC_CAN01: start 12, 8 bit, little-endian, data-type-policy=OVERRIDE, i-signal-type=PRIMITIVE, init-value=255, base-type=BT_OBD_Calc_Load_Val, compu-method=CM_OBD_Calc_Load_Val, data-constr=DC_OBD_Calc_Load_Val, unit=Unit_Unit_PerCent, transfer-property=PENDING  # Calculated Load Value Übertragung von Meßgrößen an das Getriebesteuergerät für Freeze Frame Abspeicherung bei Getriebefehlern PID $04 Calculated Load Value; 0 .. 100% mit 100/255 % per bit
          signal OBD_ClearMem_Inhibit_XIX_OBD_04_XIX_BMC_CAN01: start 20, 1 bit, little-endian, data-type-policy=OVERRIDE, i-signal-type=PRIMITIVE, init-value=0, base-type=BT_OBD_ClearMem_Inhibit, compu-method=CM_OBD_ClearMem_Inhibit, data-constr=DC_OBD_ClearMem_Inhibit, transfer-property=PENDING  # Bei FSP_Loeschen_zulässig müssen alle OBD-ECUs im Gesamtfahrzeug einen Service 04hex Request (Ereignisspeicher löschen) korrekt ausführen. In MLB-, MLBevo-, MQB-Fahrzeugkonzepten muss der MIL-Master/Motorsteuergerät bei Kl.15 ein, projektabhängig, konstant OBD_ClearMem_Inhibit = 0 senden, sofern das Löschen des Ereignisspeichers noch in jedem Betriebszustand (auch bei laufendem Motor, etc.) gefordert ist. Projektspezifisch im MLB-, MLBevo-, und MQB-Fahrzeugkonzepten und vollumfänglich in MQB_37W- und MLB3-Fahrzeugkonzepten wird das Ereignisspeicher löschen in allen OBD-ECUs auf den Betriebszustand stehendes Fahrzeug und stehender Motor beschränkt und die entsprechende Freigabe das Ereignisspeicher Löschens vom MIL-Master über das Bussignal OBD_ClearMem_Inhibit für alle anderen OBD-ECUs im Gesamtfahrzeug signalisiert. Hinweis: Steuergerät- oder Komponentenspezifische Randbedingungen sind unter Abhängigkeit des Sicherheitskonzepts zu prüfen und zu bewerten.
          signal OBD_Sperrung_IUMPR_XIX_OBD_04_XIX_BMC_CAN01: start 21, 1 bit, little-endian, data-type-policy=OVERRIDE, i-signal-type=PRIMITIVE, init-value=0, base-type=BT_OBD_Sperrung_IUMPR, compu-method=CM_OBD_Sperrung_IUMPR, data-constr=DC_OBD_Sperrung_IUMPR, transfer-property=PENDING  # Wenn der General Denominator auf Grund eines Fehlers in den Eingangsgrößen gesperrt wird, wird diese Information über Bussystem als OBD-Statusinformation OBD_Sperrung_IUMPR für andere OBD-Steuergeräte bereitgestellt. Das MSG (MIL-Master) setzt dieses Bit, wenn auf Grund vorliegender Sperrbedingungen keine Inkrementierung des GeneralDenominator mehr stattfindet. Im Empfänger-SG ist entsprechend die Inkrementierung des oder der Numeratoren einzufrieren.
          signal OBD_Sperrung_Kaltstart_Denom_XIX_OBD_04_XIX_BMC_CAN01: start 22, 1 bit, little-endian, data-type-policy=OVERRIDE, i-signal-type=PRIMITIVE, init-value=0, base-type=BT_OBD_Sperrung_Kaltstart_Denom, compu-method=CM_OBD_Sperrung_Kaltstart_Denom, data-constr=DC_OBD_Sperrung_Kaltstart_Denom, transfer-property=PENDING  # Information vom MIL Master, dass die Bildung des EVAP Denominators im Motor nicht möglich ist und damit der noECM-Denominator gesperrt werden darf.
          signal OBD_Kaltstart_Denominator_XIX_OBD_04_XIX_BMC_CAN01: start 23, 1 bit, little-endian, data-type-policy=OVERRIDE, i-signal-type=PRIMITIVE, init-value=0, base-type=BT_OBD_Kaltstart_Denominator, compu-method=CM_OBD_Kaltstart_Denominator, data-constr=DC_OBD_Kaltstart_Denominator, transfer-property=PENDING  # Bestimmte Diagnosen werden nur unter Kaltstartbedingungen durchgeführt, der entsprechende Denominator bei IUMPR-pflichtigen Systemen wird anhand dieses vom MSG gebildeten Signals inkrementiert. (Entspricht EVAP-Denominator)
          signal MM_PropulsionSystemActive_XIX_OBD_04_XIX_BMC_CAN01: start 24, 1 bit, little-endian, data-type-policy=OVERRIDE, i-signal-type=PRIMITIVE, init-value=0, base-type=BT_MM_PropulsionSystemActive, compu-method=CM_MM_PropulsionSystemActive, data-constr=DC_MM_PropulsionSystemActive, transfer-property=TRIGGERED-ON-CHANGE-WITHOUT-REPETITION  # Fahrzeug ist fahrbereit
          signal OBD_Typ_XIX_OBD_04_XIX_BMC_CAN01: start 25, 1 bit, little-endian, data-type-policy=OVERRIDE, i-signal-type=PRIMITIVE, init-value=0, base-type=BT_OBD_Typ, compu-method=CM_OBD_Typ, data-constr=DC_OBD_Typ, transfer-property=PENDING  # Abgastyp OBD Hinweis: In Fahrzeugen mit dem Zielmarkt China und einer Zertifizierung ab China 6 muss auf dem Signal "OBD_Typ" der Wert "US_OBD" gesendet werden."
          signal OBD_MIL_XIX_OBD_04_XIX_BMC_CAN01: start 26, 1 bit, little-endian, data-type-policy=OVERRIDE, i-signal-type=PRIMITIVE, init-value=0, base-type=BT_OBD_MIL, invalid-value=Invalid_OBD_MIL_XIX_OBD_04_XIX_BMC_CAN01:1, compu-method=CM_OBD_MIL, data-constr=DC_OBD_MIL, transfer-property=TRIGGERED-ON-CHANGE-WITHOUT-REPETITION  # Ansteuerung der MIL
          signal OBD_QBit_Aussen_Temp_XIX_OBD_04_XIX_BMC_CAN01: start 27, 1 bit, little-endian, data-type-policy=OVERRIDE, i-signal-type=PRIMITIVE, init-value=1, base-type=BT_OBD_QBit_Aussen_Temp, compu-method=CM_OBD_QBit_Aussen_Temp, data-constr=DC_OBD_QBit_Aussen_Temp, transfer-property=TRIGGERED-ON-CHANGE-WITHOUT-REPETITION  # QBit der Aussentemperatur. Gesetzt bei Ersatzwert, Init oder Fehler.
          signal OBD_NumDcyMilOnReq_XIX_OBD_04_XIX_BMC_CAN01: start 28, 8 bit, little-endian, data-type-policy=OVERRIDE, i-signal-type=PRIMITIVE, init-value=0, base-type=BT_OBD_NumDcyMilOnReq, compu-method=CM_OBD_NumDcyMilOnReq, data-constr=DC_OBD_NumDcyMilOnReq, unit=Unit_Unit_None, transfer-property=PENDING  # Anzahl der DrivingCycle für MIL-Entprellung von MIL-Master
          signal OBD_Normed_Trip_Wout_Fu_Cdn_XIX_OBD_04_XIX_BMC_CAN01: start 36, 1 bit, little-endian, data-type-policy=OVERRIDE, i-signal-type=PRIMITIVE, init-value=0, base-type=BT_OBD_Normed_Trip_Wout_Fu_Cdn, compu-method=CM_OBD_Normed_Trip_Wout_Fu_Cdn, data-constr=DC_OBD_Normed_Trip_Wout_Fu_Cdn, transfer-property=PENDING  # Bedingung für General Denominator-Inkrementierung ohne FueledEngine-Operation -> wird für die Berechnung des General Denominators in der Motorsteuerung (ScanTool-Ausgabe Mode$09, InfoType$08, OBDCOND) benötigt
          signal OBD_Engine_RPM_XIX_OBD_04_XIX_BMC_CAN01: start 40, 16 bit, little-endian, data-type-policy=OVERRIDE, i-signal-type=PRIMITIVE, init-value=0, base-type=BT_OBD_Engine_RPM, compu-method=CM_OBD_Engine_RPM, data-constr=DC_OBD_Engine_RPM, unit=Unit_Unit_MinutInver, transfer-property=PENDING  # Motordrehzahl des Verbrennungsmotors für OBD freeze frame
          signal OBD_Barometric_Pressure_XIX_OBD_04_XIX_BMC_CAN01: start 56, 8 bit, little-endian, data-type-policy=OVERRIDE, i-signal-type=PRIMITIVE, init-value=0, base-type=BT_OBD_Barometric_Pressure, compu-method=CM_OBD_Barometric_Pressure, data-constr=DC_OBD_Barometric_Pressure, unit=Unit_Unit_KiloPascal, transfer-property=PENDING  # Umgebungsdruck für OBD freeze frame
      frame OBDC_Funktionaler_Req_All_XIX_BMC_CAN01: id 0x17FD0200, from BMC_HV, frame-length=8, can-addressing-mode=EXTENDED, can-frame-rx-behavior=CAN-20, can-frame-tx-behavior=CAN-20
        n pdu OBDC_Funktionaler_Req_All_XIX_BMC_CAN01: length=8
      frame OBDC_SSN_BJB_Req_XIX_BMC_CAN01: id 0x17FC70D0, from BMC_HV, frame-length=8, can-addressing-mode=EXTENDED, can-frame-rx-behavior=CAN-20, can-frame-tx-behavior=CAN-20
        n pdu OBDC_SSN_BJB_Req_XIX_BMC_CAN01: length=8
      frame OBDC_SSN_BJB_Resp_XIX_BMC_CAN01: id 0x17FE70D0, to BMC_HV, frame-length=8, can-addressing-mode=EXTENDED, can-frame-rx-behavior=CAN-20, can-frame-tx-behavior=CAN-20
        n pdu OBDC_SSN_BJB_Resp_XIX_BMC_CAN01: length=8
      frame OBDC_SSN_UI2Sens01_Req_XIX_BMC_CAN01: id 0x17FC71B1, from BMC_HV, frame-length=8, can-addressing-mode=EXTENDED, can-frame-rx-behavior=CAN-20, can-frame-tx-behavior=CAN-20
        n pdu OBDC_SSN_UI2Sens01_Req_XIX_BMC_CAN01: length=8
      frame OBDC_SSN_UI2Sens01_Resp_XIX_BMC_CAN01: id 0x17FE71B1, to BMC_HV, frame-length=8, can-addressing-mode=EXTENDED, can-frame-rx-behavior=CAN-20, can-frame-tx-behavior=CAN-20
        n pdu OBDC_SSN_UI2Sens01_Resp_XIX_BMC_CAN01: length=8
      frame OBDC_SSN_UI2Sens02_Req_XIX_BMC_CAN01: id 0x17FC71B2, from BMC_HV, frame-length=8, can-addressing-mode=EXTENDED, can-frame-rx-behavior=CAN-20, can-frame-tx-behavior=CAN-20
        n pdu OBDC_SSN_UI2Sens02_Req_XIX_BMC_CAN01: length=8
      frame OBDC_SSN_UI2Sens02_Resp_XIX_BMC_CAN01: id 0x17FE71B2, to BMC_HV, frame-length=8, can-addressing-mode=EXTENDED, can-frame-rx-behavior=CAN-20, can-frame-tx-behavior=CAN-20
        n pdu OBDC_SSN_UI2Sens02_Resp_XIX_BMC_CAN01: length=8
      frame OBDx_allOBD_Req_XIX_BMC_CAN01: id 0x18DB33F1, from BMC_HV, frame-length=8, can-addressing-mode=EXTENDED, can-frame-rx-behavior=CAN-20, can-frame-tx-behavior=CAN-20
        n pdu OBDx_allOBD_Req_XIX_BMC_CAN01: length=8
      frame ORU_01_XIX_BMC_CAN01: id 0x1A555548, from BMC_HV, frame-length=8, can-addressing-mode=EXTENDED, can-frame-rx-behavior=CAN-20, can-frame-tx-behavior=CAN-20
        pdu ORU_01_XIX_BMC_CAN01: length=8, transmission-mode-true-timing=cyclic-timing={time-offset=0, time-period=0.5}, unused-bit-pattern=0
          signal ORU_AgLgtSdsl_XIX_ORU_01_XIX_BMC_CAN01: start 12, 11 bit, little-endian, data-type-policy=OVERRIDE, i-signal-type=PRIMITIVE, init-value=2001, base-type=BT_ORU_AgLgtSdsl, invalid-value=Invalid_ORU_AgLgtSdsl_XIX_ORU_01_XIX_BMC_CAN01:2002, compu-method=CM_ORU_AgLgtSdsl, data-constr=DC_ORU_AgLgtSdsl, unit=Unit_Unit_PerCent, transfer-property=PENDING  # Vehicle inclination angle at standstill in percent
          signal ORU_Status_XIX_ORU_01_XIX_BMC_CAN01: start 61, 3 bit, little-endian, data-type-policy=OVERRIDE, i-signal-type=PRIMITIVE, init-value=0, base-type=BT_ORU_Status, compu-method=CM_ORU_Status, data-constr=DC_ORU_Status, transfer-property=PENDING  # Verteilung des internen ORU Zustandes
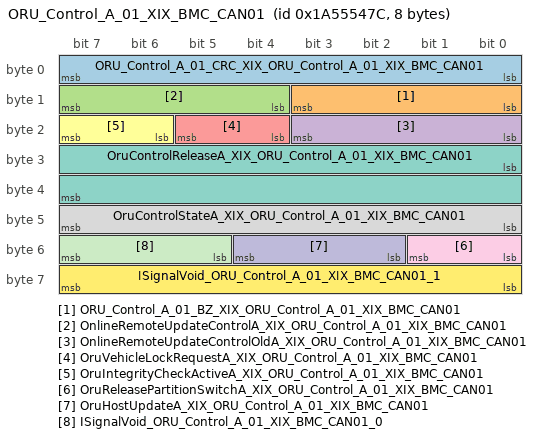
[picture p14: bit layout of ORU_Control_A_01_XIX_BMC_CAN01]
      frame ORU_Control_A_01_XIX_BMC_CAN01: id 0x1A55547C, from BMC_HV, frame-length=8, can-addressing-mode=EXTENDED, can-frame-rx-behavior=CAN-20, can-frame-tx-behavior=CAN-20
        pdu ORU_Control_A_01_XIX_BMC_CAN01: length=8, transmission-mode-true-timing=cyclic-timing={time-offset=0, time-period=0.5}, unused-bit-pattern=0
          signal ORU_Control_A_01_CRC_XIX_ORU_Control_A_01_XIX_BMC_CAN01: start 0, 8 bit, little-endian, data-type-policy=OVERRIDE, i-signal-type=PRIMITIVE, init-value=0, base-type=BT_ORU_Control_A_01_CRC, compu-method=CM_ORU_Control_A_01_CRC, data-constr=DC_ORU_Control_A_01_CRC
          signal ORU_Control_A_01_BZ_XIX_ORU_Control_A_01_XIX_BMC_CAN01: start 8, 4 bit, little-endian, data-type-policy=OVERRIDE, i-signal-type=PRIMITIVE, init-value=0, base-type=BT_ORU_Control_A_01_BZ, compu-method=CM_ORU_Control_A_01_BZ, data-constr=DC_ORU_Control_A_01_BZ
          signal OnlineRemoteUpdateControlA_XIX_ORU_Control_A_01_XIX_BMC_CAN01: start 12, 4 bit, little-endian, data-type-policy=OVERRIDE, i-signal-type=PRIMITIVE, init-value=0, base-type=BT_OnlineRemoteUpdateControlA, invalid-value=Invalid_OnlineRemoteUpdateControlA_XIX_ORU_Control_A_01_XIX_BMC_CAN01:15, compu-method=CM_OnlineRemoteUpdateControlA, data-constr=DC_OnlineRemoteUpdateControlA  # Current state of the oru control component
          signal OnlineRemoteUpdateControlOldA_XIX_ORU_Control_A_01_XIX_BMC_CAN01: start 16, 4 bit, little-endian, data-type-policy=OVERRIDE, i-signal-type=PRIMITIVE, init-value=0, base-type=BT_OnlineRemoteUpdateControlOldA, invalid-value=Invalid_OnlineRemoteUpdateControlOldA_XIX_ORU_Control_A_01_XIX_BMC_CAN01:15, compu-method=CM_OnlineRemoteUpdateControlOldA, data-constr=DC_OnlineRemoteUpdateControlOldA  # Old state of the ORU control A signal (state 5 cycles before)
          signal OruVehicleLockRequestA_XIX_ORU_Control_A_01_XIX_BMC_CAN01: start 20, 2 bit, little-endian, data-type-policy=OVERRIDE, i-signal-type=PRIMITIVE, init-value=0, base-type=BT_OruVehicleLockRequestA, invalid-value=Invalid_OruVehicleLockRequestA_XIX_ORU_Control_A_01_XIX_BMC_CAN01:3, compu-method=CM_OruVehicleLockRequestA, data-constr=DC_OruVehicleLockRequestA  # Releases or locks one or more ECUs with their specific functions (e.g. immobilizer)
          signal OruIntegrityCheckActiveA_XIX_ORU_Control_A_01_XIX_BMC_CAN01: start 22, 2 bit, little-endian, data-type-policy=OVERRIDE, i-signal-type=PRIMITIVE, init-value=0, base-type=BT_OruIntegrityCheckActiveA, invalid-value=Invalid_OruIntegrityCheckActiveA_XIX_ORU_Control_A_01_XIX_BMC_CAN01:3, compu-method=CM_OruIntegrityCheckActiveA, data-constr=DC_OruIntegrityCheckActiveA  # Signal to indicate if the integrity check is active
          signal OruControlReleaseA_XIX_ORU_Control_A_01_XIX_BMC_CAN01: start 24, 16 bit, little-endian, data-type-policy=OVERRIDE, i-signal-type=PRIMITIVE, init-value=0, base-type=BT_OruControlReleaseA, compu-method=CM_OruControlReleaseA, data-constr=DC_OruControlReleaseA, unit=Unit_Unit_None  # Release of an ecu to be flashed by oru
          signal OruControlStateA_XIX_ORU_Control_A_01_XIX_BMC_CAN01: start 40, 8 bit, little-endian, data-type-policy=OVERRIDE, i-signal-type=PRIMITIVE, init-value=0, base-type=BT_OruControlStateA, invalid-value=Invalid_OruControlStateA_XIX_ORU_Control_A_01_XIX_BMC_CAN01:129, compu-method=CM_OruControlStateA, data-constr=DC_OruControlStateA  # Internal State of ORU Control component.
          signal OruReleasePartitionSwitchA_XIX_ORU_Control_A_01_XIX_BMC_CAN01: start 48, 2 bit, little-endian, data-type-policy=OVERRIDE, i-signal-type=PRIMITIVE, init-value=0, base-type=BT_OruReleasePartitionSwitchA, invalid-value=Invalid_OruReleasePartitionSwitchA_XIX_ORU_Control_A_01_XIX_BMC_CAN01:3, compu-method=CM_OruReleasePartitionSwitchA, data-constr=DC_OruReleasePartitionSwitchA  # Release to switch the partition in case of an A/B partition update
          signal OruHostUpdateA_XIX_ORU_Control_A_01_XIX_BMC_CAN01: start 50, 3 bit, little-endian, data-type-policy=OVERRIDE, i-signal-type=PRIMITIVE, init-value=0, base-type=BT_OruHostUpdateA, invalid-value=Invalid_OruHostUpdateA_XIX_ORU_Control_A_01_XIX_BMC_CAN01:4, compu-method=CM_OruHostUpdateA, data-constr=DC_OruHostUpdateA  # Releases an update of an critical funcion's host (due to functional safety)
          mapping SG_ORU_Control_A_01_XIX_BMC_CAN01: i-signal-group=SG_ORU_Control_A_01_XIX_BMC_CAN01, transfer-property=PENDING
          signal ISignalVoid_ORU_Control_A_01_XIX_BMC_CAN01_0: start 53, 3 bit, little-endian, system signal SignalVoid_ORU_Control_A_01_0, data-type-policy=OVERRIDE, i-signal-type=PRIMITIVE, base-type=BT_SignalVoid
          signal ISignalVoid_ORU_Control_A_01_XIX_BMC_CAN01_1: start 56, 8 bit, little-endian, system signal SignalVoid_ORU_Control_A_01_1, data-type-policy=OVERRIDE, i-signal-type=PRIMITIVE, base-type=BT_SignalVoid
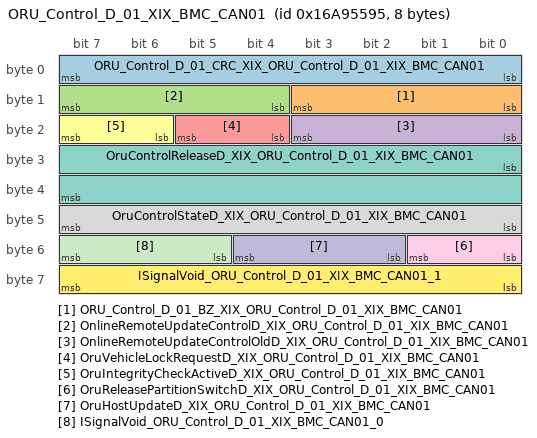
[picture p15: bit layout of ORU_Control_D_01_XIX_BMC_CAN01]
      frame ORU_Control_D_01_XIX_BMC_CAN01: id 0x16A95595, from BMC_HV, frame-length=8, can-addressing-mode=EXTENDED, can-frame-rx-behavior=CAN-20, can-frame-tx-behavior=CAN-20
        pdu ORU_Control_D_01_XIX_BMC_CAN01: length=8, transmission-mode-true-timing=cyclic-timing={time-offset=0, time-period=0.32}, unused-bit-pattern=0
          signal ORU_Control_D_01_CRC_XIX_ORU_Control_D_01_XIX_BMC_CAN01: start 0, 8 bit, little-endian, data-type-policy=OVERRIDE, i-signal-type=PRIMITIVE, init-value=0, base-type=BT_ORU_Control_D_01_CRC, compu-method=CM_ORU_Control_D_01_CRC, data-constr=DC_ORU_Control_D_01_CRC
          signal ORU_Control_D_01_BZ_XIX_ORU_Control_D_01_XIX_BMC_CAN01: start 8, 4 bit, little-endian, data-type-policy=OVERRIDE, i-signal-type=PRIMITIVE, init-value=0, base-type=BT_ORU_Control_D_01_BZ, compu-method=CM_ORU_Control_D_01_BZ, data-constr=DC_ORU_Control_D_01_BZ
          signal OnlineRemoteUpdateControlD_XIX_ORU_Control_D_01_XIX_BMC_CAN01: start 12, 4 bit, little-endian, data-type-policy=OVERRIDE, i-signal-type=PRIMITIVE, init-value=0, base-type=BT_OnlineRemoteUpdateControlD, invalid-value=Invalid_OnlineRemoteUpdateControlD_XIX_ORU_Control_D_01_XIX_BMC_CAN01:15, compu-method=CM_OnlineRemoteUpdateControlD, data-constr=DC_OnlineRemoteUpdateControlD  # This signal is part of the ORU functional safety concept to inform ECUs, if an update is possible
          signal OnlineRemoteUpdateControlOldD_XIX_ORU_Control_D_01_XIX_BMC_CAN01: start 16, 4 bit, little-endian, data-type-policy=OVERRIDE, i-signal-type=PRIMITIVE, init-value=0, base-type=BT_OnlineRemoteUpdateControlOldD, invalid-value=Invalid_OnlineRemoteUpdateControlOldD_XIX_ORU_Control_D_01_XIX_BMC_CAN01:15, compu-method=CM_OnlineRemoteUpdateControlOldD, data-constr=DC_OnlineRemoteUpdateControlOldD  # Old state of the ORU control C component (state as of 5 previous cycles)
          signal OruVehicleLockRequestD_XIX_ORU_Control_D_01_XIX_BMC_CAN01: start 20, 2 bit, little-endian, data-type-policy=OVERRIDE, i-signal-type=PRIMITIVE, init-value=0, base-type=BT_OruVehicleLockRequestD, invalid-value=Invalid_OruVehicleLockRequestD_XIX_ORU_Control_D_01_XIX_BMC_CAN01:3, compu-method=CM_OruVehicleLockRequestD, data-constr=DC_OruVehicleLockRequestD  # Releases or locks one or more ECUs with their specific functions (e.g. immobilizer)
          signal OruIntegrityCheckActiveD_XIX_ORU_Control_D_01_XIX_BMC_CAN01: start 22, 2 bit, little-endian, data-type-policy=OVERRIDE, i-signal-type=PRIMITIVE, init-value=0, base-type=BT_OruIntegrityCheckActiveD, invalid-value=Invalid_OruIntegrityCheckActiveD_XIX_ORU_Control_D_01_XIX_BMC_CAN01:3, compu-method=CM_OruIntegrityCheckActiveD, data-constr=DC_OruIntegrityCheckActiveD  # Signal to indicate if the integrity check is active
          signal OruControlReleaseD_XIX_ORU_Control_D_01_XIX_BMC_CAN01: start 24, 16 bit, little-endian, data-type-policy=OVERRIDE, i-signal-type=PRIMITIVE, init-value=0, base-type=BT_OruControlReleaseD, compu-method=CM_OruControlReleaseD, data-constr=DC_OruControlReleaseD, unit=Unit_Unit_None  # This signal is used to allow an ECU to start an update session. As this is a critical point, 2 components have to approve this
          signal OruControlStateD_XIX_ORU_Control_D_01_XIX_BMC_CAN01: start 40, 8 bit, little-endian, data-type-policy=OVERRIDE, i-signal-type=PRIMITIVE, init-value=0, base-type=BT_OruControlStateD, invalid-value=Invalid_OruControlStateD_XIX_ORU_Control_D_01_XIX_BMC_CAN01:129, compu-method=CM_OruControlStateD, data-constr=DC_OruControlStateD  # This signal is used to allow an ECU to start an update session.
          signal OruReleasePartitionSwitchD_XIX_ORU_Control_D_01_XIX_BMC_CAN01: start 48, 2 bit, little-endian, data-type-policy=OVERRIDE, i-signal-type=PRIMITIVE, init-value=0, base-type=BT_OruReleasePartitionSwitchD, invalid-value=Invalid_OruReleasePartitionSwitchD_XIX_ORU_Control_D_01_XIX_BMC_CAN01:3, compu-method=CM_OruReleasePartitionSwitchD, data-constr=DC_OruReleasePartitionSwitchD  # Release to switch the partition in case of an A/B partition update
          signal OruHostUpdateD_XIX_ORU_Control_D_01_XIX_BMC_CAN01: start 50, 3 bit, little-endian, data-type-policy=OVERRIDE, i-signal-type=PRIMITIVE, init-value=0, base-type=BT_OruHostUpdateD, invalid-value=Invalid_OruHostUpdateD_XIX_ORU_Control_D_01_XIX_BMC_CAN01:4, compu-method=CM_OruHostUpdateD, data-constr=DC_OruHostUpdateD  # Releases an update of an critical funcion's host (due to functional safety)
          mapping SG_ORU_Control_D_01_XIX_BMC_CAN01: i-signal-group=SG_ORU_Control_D_01_XIX_BMC_CAN01, transfer-property=PENDING
          signal ISignalVoid_ORU_Control_D_01_XIX_BMC_CAN01_0: start 53, 3 bit, little-endian, system signal SignalVoid_ORU_Control_D_01_0, data-type-policy=OVERRIDE, i-signal-type=PRIMITIVE, base-type=BT_SignalVoid
          signal ISignalVoid_ORU_Control_D_01_XIX_BMC_CAN01_1: start 56, 8 bit, little-endian, system signal SignalVoid_ORU_Control_D_01_1, data-type-policy=OVERRIDE, i-signal-type=PRIMITIVE, base-type=BT_SignalVoid
      frame OTAMC_D_01_XIX_BMC_CAN01: id 0x16A95596, from BMC_HV, frame-length=4, can-addressing-mode=EXTENDED, can-frame-rx-behavior=CAN-20, can-frame-tx-behavior=CAN-20
        pdu OTAMC_D_01_XIX_BMC_CAN01: length=4, transmission-mode-true-timing=cyclic-timing={time-offset=0, time-period=0.32}, unused-bit-pattern=0
          signal OTAMC_D_01_CRC_XIX_OTAMC_D_01_XIX_BMC_CAN01: start 0, 8 bit, little-endian, data-type-policy=OVERRIDE, i-signal-type=PRIMITIVE, init-value=0, base-type=BT_OTAMC_D_01_CRC, compu-method=CM_OTAMC_D_01_CRC, data-constr=DC_OTAMC_D_01_CRC
          signal OTAMC_D_01_BZ_XIX_OTAMC_D_01_XIX_BMC_CAN01: start 8, 4 bit, little-endian, data-type-policy=OVERRIDE, i-signal-type=PRIMITIVE, init-value=0, base-type=BT_OTAMC_D_01_BZ, compu-method=CM_OTAMC_D_01_BZ, data-constr=DC_OTAMC_D_01_BZ
          signal VehicleProtectedEnvironment_D_XIX_OTAMC_D_01_XIX_BMC_CAN01: start 12, 2 bit, little-endian, data-type-policy=OVERRIDE, i-signal-type=PRIMITIVE, init-value=0, base-type=BT_VehicleProtectedEnvironment_D, compu-method=CM_VehicleProtectedEnvironment_D, data-constr=DC_VehicleProtectedEnvironment_D  # Environment of vehicle in case of Remote Production
          mapping SG_OTAMC_D_01_XIX_BMC_CAN01: i-signal-group=SG_OTAMC_D_01_XIX_BMC_CAN01, transfer-property=PENDING
          signal ISignalVoid_OTAMC_D_01_XIX_BMC_CAN01_0: start 14, 2 bit, little-endian, system signal SignalVoid_OTAMC_D_01_0, data-type-policy=OVERRIDE, i-signal-type=PRIMITIVE, base-type=BT_SignalVoid
          signal ISignalVoid_OTAMC_D_01_XIX_BMC_CAN01_1: start 16, 8 bit, little-endian, system signal SignalVoid_OTAMC_D_01_1, data-type-policy=OVERRIDE, i-signal-type=PRIMITIVE, base-type=BT_SignalVoid
          signal ISignalVoid_OTAMC_D_01_XIX_BMC_CAN01_2: start 24, 8 bit, little-endian, system signal SignalVoid_OTAMC_D_01_2, data-type-policy=OVERRIDE, i-signal-type=PRIMITIVE, base-type=BT_SignalVoid
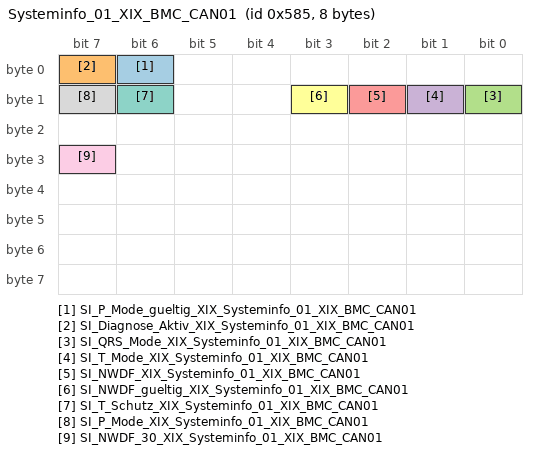
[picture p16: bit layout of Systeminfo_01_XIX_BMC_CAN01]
      frame Systeminfo_01_XIX_BMC_CAN01: id 0x585, from BMC_HV, frame-length=8, can-addressing-mode=STANDARD, can-frame-rx-behavior=CAN-20, can-frame-tx-behavior=CAN-20
        pdu Systeminfo_01_XIX_BMC_CAN01: length=8, minimum-delay=0.01, transmission-mode-true-timing={cyclic-timing={time-offset=0, time-period=1}, event-controlled-timing={number-of-repetitions=0, repetition-period=0}}, unused-bit-pattern=0  # MQB, MLBevo
          signal SI_P_Mode_gueltig_XIX_Systeminfo_01_XIX_BMC_CAN01: start 6, 1 bit, little-endian, data-type-policy=OVERRIDE, i-signal-type=PRIMITIVE, init-value=0, base-type=BT_SI_P_Mode_gueltig, compu-method=CM_SI_P_Mode_gueltig, data-constr=DC_SI_P_Mode_gueltig, transfer-property=PENDING  # zeigt an, ob es sich um ein Fahrzeug mit zentraler oder dezentraler Steu-erung des Produktionsmodes handelt Siehe Q-LAH Produktionsmode (LAH.DUM.907.AS)
          signal SI_Diagnose_Aktiv_XIX_Systeminfo_01_XIX_BMC_CAN01: start 7, 1 bit, little-endian, data-type-policy=OVERRIDE, i-signal-type=PRIMITIVE, init-value=0, base-type=BT_SI_Diagnose_Aktiv, compu-method=CM_SI_Diagnose_Aktiv, data-constr=DC_SI_Diagnose_Aktiv, transfer-property=PENDING  # Gibt an ob Diagnose-Botschaften empfangen werden und somit eine Diagnose aktiv ist. MQB: Gibt an ob Diagnose-Bus Botschaften empfangen werden und somit eine Diagnose aktiv ist.
          signal SI_QRS_Mode_XIX_Systeminfo_01_XIX_BMC_CAN01: start 8, 1 bit, little-endian, data-type-policy=OVERRIDE, i-signal-type=PRIMITIVE, init-value=0, base-type=BT_SI_QRS_Mode, compu-method=CM_SI_QRS_Mode, data-constr=DC_SI_QRS_Mode, transfer-property=PENDING  # Messmodus Quick-Ruhestrom
          signal SI_T_Mode_XIX_Systeminfo_01_XIX_BMC_CAN01: start 9, 1 bit, little-endian, data-type-policy=OVERRIDE, i-signal-type=PRIMITIVE, init-value=0, base-type=BT_SI_T_Mode, compu-method=CM_SI_T_Mode, data-constr=DC_SI_T_Mode, transfer-property=PENDING  # 0x0: Transportmodus nicht aktiv 0x1: Transportmodus aktiv
          signal SI_NWDF_XIX_Systeminfo_01_XIX_BMC_CAN01: start 10, 1 bit, little-endian, data-type-policy=OVERRIDE, i-signal-type=PRIMITIVE, init-value=0, base-type=BT_SI_NWDF, compu-method=CM_SI_NWDF, data-constr=DC_SI_NWDF, transfer-property=TRIGGERED-ON-CHANGE-WITHOUT-REPETITION  # Netzwerk-Diagnose Freigebe zur zentralen Aktivierung der Netzwerkdiagnose
          signal SI_NWDF_gueltig_XIX_Systeminfo_01_XIX_BMC_CAN01: start 11, 1 bit, little-endian, data-type-policy=OVERRIDE, i-signal-type=PRIMITIVE, init-value=1, base-type=BT_SI_NWDF_gueltig, compu-method=CM_SI_NWDF_gueltig, data-constr=DC_SI_NWDF_gueltig, transfer-property=PENDING  # Gültigkeitsbit zu SI_NWDF gemäß Lastenheft: Zentrale Aktivierung Netzwerkdiagnose
          signal SI_T_Schutz_XIX_Systeminfo_01_XIX_BMC_CAN01: start 14, 1 bit, little-endian, data-type-policy=OVERRIDE, i-signal-type=PRIMITIVE, init-value=0, base-type=BT_SI_T_Schutz, compu-method=CM_SI_T_Schutz, data-constr=DC_SI_T_Schutz, transfer-property=PENDING  # Transportschutz-Signal, das bei Transportmodus und Motorlauf aktiv bleibt 0x0: Transportschutz nicht aktiv 0x1: Transportschutz aktiv
          signal SI_P_Mode_XIX_Systeminfo_01_XIX_BMC_CAN01: start 15, 1 bit, little-endian, data-type-policy=OVERRIDE, i-signal-type=PRIMITIVE, init-value=0, base-type=BT_SI_P_Mode, compu-method=CM_SI_P_Mode, data-constr=DC_SI_P_Mode, transfer-property=PENDING  # Zentrale Steuerung des Produktionsmodes gemäß Q-LAH-Produktionsmode (LAH.DUM.907.AS)
          signal SI_NWDF_30_XIX_Systeminfo_01_XIX_BMC_CAN01: start 31, 1 bit, little-endian, data-type-policy=OVERRIDE, i-signal-type=PRIMITIVE, init-value=0, base-type=BT_SI_NWDF_30, compu-method=CM_SI_NWDF_30, data-constr=DC_SI_NWDF_30, transfer-property=TRIGGERED-ON-CHANGE-WITHOUT-REPETITION  # Netzwerk-Diagnose Freigabe zur zentralen Aktivierung der Netzwerkdiagnose (keine Ausblendbedingung aktiv)
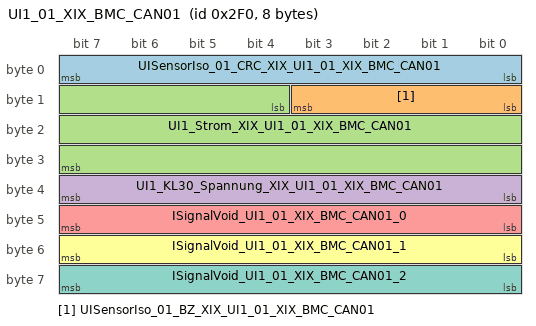
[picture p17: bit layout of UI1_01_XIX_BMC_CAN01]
      frame UI1_01_XIX_BMC_CAN01: id 0x2F0, to BMC_HV, frame-length=8, can-addressing-mode=STANDARD, can-frame-rx-behavior=CAN-20, can-frame-tx-behavior=CAN-20
        pdu UI1_01_XIX_BMC_CAN01_E2E: length=8, transmission-mode-true-timing=event-controlled-timing={number-of-repetitions=0, repetition-period=0}, unused-bit-pattern=0  # Fuer die Botschaft ist das Cyclic-Timing 0.01 zu verwenden.
          signal UISensorIso_01_CRC_XIX_UI1_01_XIX_BMC_CAN01: start 0, 8 bit, little-endian, data-type-policy=OVERRIDE, i-signal-type=PRIMITIVE, init-value=0, base-type=BT_UISensorIso_01_CRC, compu-method=CM_UISensorIso_01_CRC, data-constr=DC_UISensorIso_01_CRC, to BMC_HV(timeout 0.5 s)
          signal UISensorIso_01_BZ_XIX_UI1_01_XIX_BMC_CAN01: start 8, 4 bit, little-endian, data-type-policy=OVERRIDE, i-signal-type=PRIMITIVE, init-value=0, base-type=BT_UISensorIso_01_BZ, compu-method=CM_UISensorIso_01_BZ, data-constr=DC_UISensorIso_01_BZ, to BMC_HV(timeout 0.5 s)
          signal UI1_Strom_XIX_UI1_01_XIX_BMC_CAN01: start 12, 20 bit, little-endian, data-type-policy=OVERRIDE, i-signal-type=PRIMITIVE, init-value=1048574, base-type=BT_UI1_Strom, invalid-value=Invalid_UI1_Strom_XIX_UI1_01_XIX_BMC_CAN01:1048575, compu-method=CM_UI1_Strom, data-constr=DC_UI1_Strom, unit=Unit_Unit_Amper, to BMC_HV(timeout 0.5 s)  # Momentanwert: Batteriestrom
          signal UI1_KL30_Spannung_XIX_UI1_01_XIX_BMC_CAN01: start 32, 8 bit, little-endian, data-type-policy=OVERRIDE, i-signal-type=PRIMITIVE, init-value=254, base-type=BT_UI1_KL30_Spannung, invalid-value=Invalid_UI1_KL30_Spannung_XIX_UI1_01_XIX_BMC_CAN01:255, compu-method=CM_UI1_KL30_Spannung, data-constr=DC_UI1_KL30_Spannung, unit=Unit_Unit_Volt, to BMC_HV(timeout 0.5 s)  # Momentanwert: gemessene Klemme30-Spannung am UI-Sensor
          signal ISignalVoid_UI1_01_XIX_BMC_CAN01_0: start 40, 8 bit, little-endian, system signal SignalVoid_UI1_01_0, data-type-policy=OVERRIDE, i-signal-type=PRIMITIVE, base-type=BT_SignalVoid
          signal ISignalVoid_UI1_01_XIX_BMC_CAN01_1: start 48, 8 bit, little-endian, system signal SignalVoid_UI1_01_1, data-type-policy=OVERRIDE, i-signal-type=PRIMITIVE, base-type=BT_SignalVoid
          signal ISignalVoid_UI1_01_XIX_BMC_CAN01_2: start 56, 8 bit, little-endian, system signal SignalVoid_UI1_01_2, data-type-policy=OVERRIDE, i-signal-type=PRIMITIVE, base-type=BT_SignalVoid
          mapping SG_UI1_01_XIX_BMC_CAN01: i-signal-group=SG_UI1_01_XIX_BMC_CAN01, transfer-property=TRIGGERED-WITHOUT-REPETITION
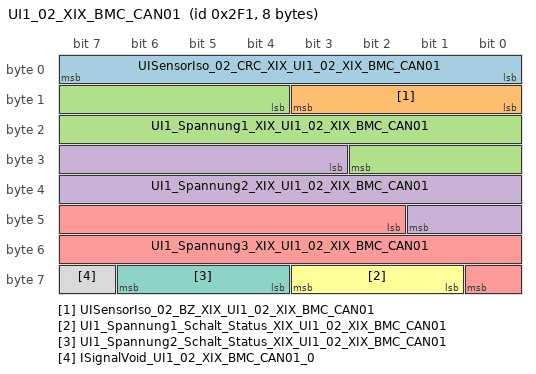
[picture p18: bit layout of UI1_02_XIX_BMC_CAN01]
      frame UI1_02_XIX_BMC_CAN01: id 0x2F1, to BMC_HV, frame-length=8, can-addressing-mode=STANDARD, can-frame-rx-behavior=CAN-20, can-frame-tx-behavior=CAN-20
        pdu UI1_02_XIX_BMC_CAN01_E2E: length=8, transmission-mode-true-timing=event-controlled-timing={number-of-repetitions=0, repetition-period=0}, unused-bit-pattern=0  # Fuer die Botschaft ist das Cyclic-Timing 0.01 zu verwenden.
          signal UISensorIso_02_CRC_XIX_UI1_02_XIX_BMC_CAN01: start 0, 8 bit, little-endian, data-type-policy=OVERRIDE, i-signal-type=PRIMITIVE, init-value=0, base-type=BT_UISensorIso_02_CRC, compu-method=CM_UISensorIso_02_CRC, data-constr=DC_UISensorIso_02_CRC, to BMC_HV(timeout 0.5 s)
          signal UISensorIso_02_BZ_XIX_UI1_02_XIX_BMC_CAN01: start 8, 4 bit, little-endian, data-type-policy=OVERRIDE, i-signal-type=PRIMITIVE, init-value=0, base-type=BT_UISensorIso_02_BZ, compu-method=CM_UISensorIso_02_BZ, data-constr=DC_UISensorIso_02_BZ, to BMC_HV(timeout 0.5 s)
          signal UI1_Spannung1_XIX_UI1_02_XIX_BMC_CAN01: start 12, 15 bit, little-endian, data-type-policy=OVERRIDE, i-signal-type=PRIMITIVE, init-value=32766, base-type=BT_UI1_Spannung1, invalid-value=Invalid_UI1_Spannung1_XIX_UI1_02_XIX_BMC_CAN01:32767, compu-method=CM_UI1_Spannung1, data-constr=DC_UI1_Spannung1, unit=Unit_Unit_Volt, to BMC_HV(timeout 0.5 s)  # Spannungsmesskanal 1
          signal UI1_Spannung2_XIX_UI1_02_XIX_BMC_CAN01: start 27, 15 bit, little-endian, data-type-policy=OVERRIDE, i-signal-type=PRIMITIVE, init-value=32766, base-type=BT_UI1_Spannung2, invalid-value=Invalid_UI1_Spannung2_XIX_UI1_02_XIX_BMC_CAN01:32767, compu-method=CM_UI1_Spannung2, data-constr=DC_UI1_Spannung2, unit=Unit_Unit_Volt, to BMC_HV(timeout 0.5 s)  # Spannungsmesskanal 2
          signal UI1_Spannung3_XIX_UI1_02_XIX_BMC_CAN01: start 42, 15 bit, little-endian, data-type-policy=OVERRIDE, i-signal-type=PRIMITIVE, init-value=32766, base-type=BT_UI1_Spannung3, invalid-value=Invalid_UI1_Spannung3_XIX_UI1_02_XIX_BMC_CAN01:32767, compu-method=CM_UI1_Spannung3, data-constr=DC_UI1_Spannung3, unit=Unit_Unit_Volt, to BMC_HV(timeout 0.5 s)  # Spannungsmesskanal 3
          signal UI1_Spannung1_Schalt_Status_XIX_UI1_02_XIX_BMC_CAN01: start 57, 3 bit, little-endian, data-type-policy=OVERRIDE, i-signal-type=PRIMITIVE, init-value=6, base-type=BT_UI1_Spannung1_Schalt_Status, invalid-value=Invalid_UI1_Spannung1_Schalt_Status_XIX_UI1_02_XIX_BMC_CAN01:7, compu-method=CM_UI1_Spannung1_Schalt_Status, data-constr=DC_UI1_Spannung1_Schalt_Status, to BMC_HV(timeout 0.5 s)  # Status des abschaltbaren Spannungsmesskanal1
          signal UI1_Spannung2_Schalt_Status_XIX_UI1_02_XIX_BMC_CAN01: start 60, 3 bit, little-endian, data-type-policy=OVERRIDE, i-signal-type=PRIMITIVE, init-value=6, base-type=BT_UI1_Spannung2_Schalt_Status, invalid-value=Invalid_UI1_Spannung2_Schalt_Status_XIX_UI1_02_XIX_BMC_CAN01:7, compu-method=CM_UI1_Spannung2_Schalt_Status, data-constr=DC_UI1_Spannung2_Schalt_Status, to BMC_HV(timeout 0.5 s)  # Status des abschaltbaren Spannungsmesskanal2
          signal ISignalVoid_UI1_02_XIX_BMC_CAN01_0: start 63, 1 bit, little-endian, system signal SignalVoid_UI1_02_0, data-type-policy=OVERRIDE, i-signal-type=PRIMITIVE, base-type=BT_SignalVoid
          mapping SG_UI1_02_XIX_BMC_CAN01: i-signal-group=SG_UI1_02_XIX_BMC_CAN01, transfer-property=TRIGGERED-WITHOUT-REPETITION
      frame UI1_03_XIX_BMC_CAN01: id 0x2F2, to BMC_HV, frame-length=8, can-addressing-mode=STANDARD, can-frame-rx-behavior=CAN-20, can-frame-tx-behavior=CAN-20
        pdu UI1_03_XIX_BMC_CAN01: length=8, transmission-mode-true-timing=cyclic-timing={time-offset=0, time-period=0.01}, unused-bit-pattern=0
          signal UI1_Spannung4_XIX_UI1_03_XIX_BMC_CAN01: start 12, 15 bit, little-endian, data-type-policy=OVERRIDE, i-signal-type=PRIMITIVE, init-value=32766, base-type=BT_UI1_Spannung4, invalid-value=Invalid_UI1_Spannung4_XIX_UI1_03_XIX_BMC_CAN01:32767, compu-method=CM_UI1_Spannung4, data-constr=DC_UI1_Spannung4, unit=Unit_Unit_Volt, transfer-property=PENDING, to BMC_HV(timeout 0.5 s)  # Spannungsmesskanal 4
          signal UI1_Spannung5_XIX_UI1_03_XIX_BMC_CAN01: start 27, 15 bit, little-endian, data-type-policy=OVERRIDE, i-signal-type=PRIMITIVE, init-value=32766, base-type=BT_UI1_Spannung5, invalid-value=Invalid_UI1_Spannung5_XIX_UI1_03_XIX_BMC_CAN01:32767, compu-method=CM_UI1_Spannung5, data-constr=DC_UI1_Spannung5, unit=Unit_Unit_Volt, transfer-property=PENDING, to BMC_HV(timeout 0.5 s)  # Spannungsmesskanal 5
          signal UI1_Spannung6_XIX_UI1_03_XIX_BMC_CAN01: start 42, 15 bit, little-endian, data-type-policy=OVERRIDE, i-signal-type=PRIMITIVE, init-value=32766, base-type=BT_UI1_Spannung6, invalid-value=Invalid_UI1_Spannung6_XIX_UI1_03_XIX_BMC_CAN01:32767, compu-method=CM_UI1_Spannung6, data-constr=DC_UI1_Spannung6, unit=Unit_Unit_Volt, transfer-property=PENDING, to BMC_HV(timeout 0.5 s)  # Spannungsmesskanal 6
      frame UI1_04_XIX_BMC_CAN01: id 0x12DD545C, to BMC_HV, frame-length=8, can-addressing-mode=EXTENDED, can-frame-rx-behavior=CAN-20, can-frame-tx-behavior=CAN-20
        pdu UI1_04_XIX_BMC_CAN01: length=8, transmission-mode-true-timing=cyclic-timing={time-offset=0, time-period=0.1}, unused-bit-pattern=0
          signal UI2Sens01_ErrMem_State_XIX_UI1_04_XIX_BMC_CAN01: start 13, 2 bit, little-endian, data-type-policy=OVERRIDE, i-signal-type=PRIMITIVE, init-value=2, base-type=BT_UI2Sens01_ErrMem_State, compu-method=CM_UI2Sens01_ErrMem_State, data-constr=DC_UI2Sens01_ErrMem_State, transfer-property=PENDING, to BMC_HV(timeout 1 s)  # Error Memory State
          signal UI1_Status_XIX_UI1_04_XIX_BMC_CAN01: start 15, 1 bit, little-endian, data-type-policy=OVERRIDE, i-signal-type=PRIMITIVE, init-value=0, base-type=BT_UI1_Status, compu-method=CM_UI1_Status, data-constr=DC_UI1_Status, transfer-property=PENDING, to BMC_HV(timeout 1 s)  # dient zur Signalisierung Neustart oder Reset des UI-Sensors
          signal UI1_Temperatur_2_XIX_UI1_04_XIX_BMC_CAN01: start 16, 8 bit, little-endian, data-type-policy=OVERRIDE, i-signal-type=PRIMITIVE, init-value=254, base-type=BT_UI1_Temperatur_2, invalid-value=Invalid_UI1_Temperatur_2_XIX_UI1_04_XIX_BMC_CAN01:255, compu-method=CM_UI1_Temperatur_2, data-constr=DC_UI1_Temperatur_2, unit=Unit_Unit_DegreCelsi, transfer-property=PENDING, to BMC_HV(timeout 1 s)  # Temperatur 2
          signal UI1_Temperatur_1_XIX_UI1_04_XIX_BMC_CAN01: start 24, 8 bit, little-endian, data-type-policy=OVERRIDE, i-signal-type=PRIMITIVE, init-value=254, base-type=BT_UI1_Temperatur_1, invalid-value=Invalid_UI1_Temperatur_1_XIX_UI1_04_XIX_BMC_CAN01:255, compu-method=CM_UI1_Temperatur_1, data-constr=DC_UI1_Temperatur_1, unit=Unit_Unit_DegreCelsi, transfer-property=PENDING, to BMC_HV(timeout 1 s)  # Temperatur 1
          signal UI1_Stromintegral_Laden_XIX_UI1_04_XIX_BMC_CAN01: start 32, 16 bit, little-endian, data-type-policy=OVERRIDE, i-signal-type=PRIMITIVE, init-value=65534, base-type=BT_UI1_Stromintegral_Laden, invalid-value=Invalid_UI1_Stromintegral_Laden_XIX_UI1_04_XIX_BMC_CAN01:65535, compu-method=CM_UI1_Stromintegral_Laden, data-constr=DC_UI1_Stromintegral_Laden, unit=Unit_Unit_AmperSecon, transfer-property=PENDING, to BMC_HV(timeout 1 s)  # Ladungszaehler des UI1 Sensors fuer Laden
          signal UI1_Stromintegral_Entladen_XIX_UI1_04_XIX_BMC_CAN01: start 48, 16 bit, little-endian, data-type-policy=OVERRIDE, i-signal-type=PRIMITIVE, init-value=65534, base-type=BT_UI1_Stromintegral_Entladen, invalid-value=Invalid_UI1_Stromintegral_Entladen_XIX_UI1_04_XIX_BMC_CAN01:65535, compu-method=CM_UI1_Stromintegral_Entladen, data-constr=DC_UI1_Stromintegral_Entladen, unit=Unit_Unit_AmperSecon, transfer-property=PENDING, to BMC_HV(timeout 1 s)  # Ladungszaehler des UI1 Sensors fuer Entladen
      frame UI1_05_XIX_BMC_CAN01: id 0x12DD545D, to BMC_HV, frame-length=8, can-addressing-mode=EXTENDED, can-frame-rx-behavior=CAN-20, can-frame-tx-behavior=CAN-20
        pdu UI1_05_XIX_BMC_CAN01: length=8, transmission-mode-true-timing=cyclic-timing={time-offset=0, time-period=0.1}, unused-bit-pattern=0
          signal UI1_Iso_Status_XIX_UI1_05_XIX_BMC_CAN01: start 29, 3 bit, little-endian, data-type-policy=OVERRIDE, i-signal-type=PRIMITIVE, init-value=0, base-type=BT_UI1_Iso_Status, invalid-value=Invalid_UI1_Iso_Status_XIX_UI1_05_XIX_BMC_CAN01:1, compu-method=CM_UI1_Iso_Status, data-constr=DC_UI1_Iso_Status, transfer-property=PENDING, to BMC_HV(timeout 1 s)  # Rueckmeldung Status Isolationswaechter
          signal UI1_Iso_Pos_XIX_UI1_05_XIX_BMC_CAN01: start 32, 16 bit, little-endian, data-type-policy=OVERRIDE, i-signal-type=PRIMITIVE, init-value=65534, base-type=BT_UI1_Iso_Pos, invalid-value=Invalid_UI1_Iso_Pos_XIX_UI1_05_XIX_BMC_CAN01:65535, compu-method=CM_UI1_Iso_Pos, data-constr=DC_UI1_Iso_Pos, unit=Unit_Unit_Ohm, transfer-property=PENDING, to BMC_HV(timeout 1 s)  # Isolationswiderstandswert Plus
          signal UI1_Iso_Neg_XIX_UI1_05_XIX_BMC_CAN01: start 48, 16 bit, little-endian, data-type-policy=OVERRIDE, i-signal-type=PRIMITIVE, init-value=65534, base-type=BT_UI1_Iso_Neg, invalid-value=Invalid_UI1_Iso_Neg_XIX_UI1_05_XIX_BMC_CAN01:65535, compu-method=CM_UI1_Iso_Neg, data-constr=DC_UI1_Iso_Neg, unit=Unit_Unit_Ohm, transfer-property=PENDING, to BMC_HV(timeout 1 s)  # Isolationswiderstandswert Minus
      frame UI1_Komponentenfehler_01_XIX_BMC_CAN01: id 0x12DD551E, to BMC_HV, frame-length=8, can-addressing-mode=EXTENDED, can-frame-rx-behavior=CAN-20, can-frame-tx-behavior=CAN-20
        pdu UI1_Komponentenfehler_01_XIX_BMC_CAN01: length=8, transmission-mode-true-timing=cyclic-timing={time-offset=0, time-period=0.1}, unused-bit-pattern=0
          signal UI1_KompFehlerModus2_01_XIX_UI1_Komponentenfehler_01_XIX_BMC_CAN01: start 12, 2 bit, little-endian, data-type-policy=OVERRIDE, i-signal-type=PRIMITIVE, init-value=0, base-type=BT_UI1_KompFehlerModus2_01, compu-method=CM_UI1_KompFehlerModus2_01, data-constr=DC_UI1_KompFehlerModus2_01, transfer-property=PENDING, to BMC_HV(timeout 1 s)  # Uebertragung OBD relevanter Fehlerpfade vom Secondary zum Primary Steuergeraet. Zuordnung der generischen Komponentenfehler muss zwischen Sender und Empfaenger abgestimmt werden
          signal UI1_KompFehlerModus2_02_XIX_UI1_Komponentenfehler_01_XIX_BMC_CAN01: start 14, 2 bit, little-endian, data-type-policy=OVERRIDE, i-signal-type=PRIMITIVE, init-value=0, base-type=BT_UI1_KompFehlerModus2_02, compu-method=CM_UI1_KompFehlerModus2_02, data-constr=DC_UI1_KompFehlerModus2_02, transfer-property=PENDING, to BMC_HV(timeout 1 s)  # Uebertragung OBD relevanter Fehlerpfade vom Secondary zum Primary Steuergeraet. Zuordnung der generischen Komponentenfehler muss zwischen Sender und Empfaenger abgestimmt werden
          signal UI1_KompFehlerModus2_03_XIX_UI1_Komponentenfehler_01_XIX_BMC_CAN01: start 16, 2 bit, little-endian, data-type-policy=OVERRIDE, i-signal-type=PRIMITIVE, init-value=0, base-type=BT_UI1_KompFehlerModus2_03, compu-method=CM_UI1_KompFehlerModus2_03, data-constr=DC_UI1_KompFehlerModus2_03, transfer-property=PENDING, to BMC_HV(timeout 1 s)  # Uebertragung OBD relevanter Fehlerpfade vom Secondary zum Primary Steuergeraet. Zuordnung der generischen Komponentenfehler muss zwischen Sender und Empfaenger abgestimmt werden
          signal UI1_KompFehlerModus2_04_XIX_UI1_Komponentenfehler_01_XIX_BMC_CAN01: start 18, 2 bit, little-endian, data-type-policy=OVERRIDE, i-signal-type=PRIMITIVE, init-value=0, base-type=BT_UI1_KompFehlerModus2_04, compu-method=CM_UI1_KompFehlerModus2_04, data-constr=DC_UI1_KompFehlerModus2_04, transfer-property=PENDING, to BMC_HV(timeout 1 s)  # Uebertragung OBD relevanter Fehlerpfade vom Secondary zum Primary Steuergeraet. Zuordnung der generischen Komponentenfehler muss zwischen Sender und Empfaenger abgestimmt werden
          signal UI1_KompFehlerModus2_05_XIX_UI1_Komponentenfehler_01_XIX_BMC_CAN01: start 20, 2 bit, little-endian, data-type-policy=OVERRIDE, i-signal-type=PRIMITIVE, init-value=0, base-type=BT_UI1_KompFehlerModus2_05, compu-method=CM_UI1_KompFehlerModus2_05, data-constr=DC_UI1_KompFehlerModus2_05, transfer-property=PENDING, to BMC_HV(timeout 1 s)  # Uebertragung OBD relevanter Fehlerpfade vom Secondary zum Primary Steuergeraet. Zuordnung der generischen Komponentenfehler muss zwischen Sender und Empfaenger abgestimmt werden
          signal UI1_KompFehlerModus2_06_XIX_UI1_Komponentenfehler_01_XIX_BMC_CAN01: start 22, 2 bit, little-endian, data-type-policy=OVERRIDE, i-signal-type=PRIMITIVE, init-value=0, base-type=BT_UI1_KompFehlerModus2_06, compu-method=CM_UI1_KompFehlerModus2_06, data-constr=DC_UI1_KompFehlerModus2_06, transfer-property=PENDING, to BMC_HV(timeout 1 s)  # Uebertragung OBD relevanter Fehlerpfade vom Secondary zum Primary Steuergeraet. Zuordnung der generischen Komponentenfehler muss zwischen Sender und Empfaenger abgestimmt werden
          signal UI1_KompFehlerModus2_07_XIX_UI1_Komponentenfehler_01_XIX_BMC_CAN01: start 24, 2 bit, little-endian, data-type-policy=OVERRIDE, i-signal-type=PRIMITIVE, init-value=0, base-type=BT_UI1_KompFehlerModus2_07, compu-method=CM_UI1_KompFehlerModus2_07, data-constr=DC_UI1_KompFehlerModus2_07, transfer-property=PENDING, to BMC_HV(timeout 1 s)  # Uebertragung OBD relevanter Fehlerpfade vom Secondary zum Primary Steuergeraet. Zuordnung der generischen Komponentenfehler muss zwischen Sender und Empfaenger abgestimmt werden
          signal UI1_KompFehlerModus2_08_XIX_UI1_Komponentenfehler_01_XIX_BMC_CAN01: start 26, 2 bit, little-endian, data-type-policy=OVERRIDE, i-signal-type=PRIMITIVE, init-value=0, base-type=BT_UI1_KompFehlerModus2_08, compu-method=CM_UI1_KompFehlerModus2_08, data-constr=DC_UI1_KompFehlerModus2_08, transfer-property=PENDING, to BMC_HV(timeout 1 s)  # Uebertragung OBD relevanter Fehlerpfade vom Secondary zum Primary Steuergeraet. Zuordnung der generischen Komponentenfehler muss zwischen Sender und Empfaenger abgestimmt werden
          signal UI1_KompFehlerModus2_09_XIX_UI1_Komponentenfehler_01_XIX_BMC_CAN01: start 28, 2 bit, little-endian, data-type-policy=OVERRIDE, i-signal-type=PRIMITIVE, init-value=0, base-type=BT_UI1_KompFehlerModus2_09, compu-method=CM_UI1_KompFehlerModus2_09, data-constr=DC_UI1_KompFehlerModus2_09, transfer-property=PENDING, to BMC_HV(timeout 1 s)  # Uebertragung OBD relevanter Fehlerpfade vom Secondary zum Primary Steuergeraet. Zuordnung der generischen Komponentenfehler muss zwischen Sender und Empfaenger abgestimmt werden
          signal UI1_KompFehlerModus2_10_XIX_UI1_Komponentenfehler_01_XIX_BMC_CAN01: start 30, 2 bit, little-endian, data-type-policy=OVERRIDE, i-signal-type=PRIMITIVE, init-value=0, base-type=BT_UI1_KompFehlerModus2_10, compu-method=CM_UI1_KompFehlerModus2_10, data-constr=DC_UI1_KompFehlerModus2_10, transfer-property=PENDING, to BMC_HV(timeout 1 s)  # Uebertragung OBD relevanter Fehlerpfade vom Secondary zum Primary Steuergeraet. Zuordnung der generischen Komponentenfehler muss zwischen Sender und Empfaenger abgestimmt werden
          signal UI1_KompFehlerModus2_11_XIX_UI1_Komponentenfehler_01_XIX_BMC_CAN01: start 32, 2 bit, little-endian, data-type-policy=OVERRIDE, i-signal-type=PRIMITIVE, init-value=0, base-type=BT_UI1_KompFehlerModus2_11, compu-method=CM_UI1_KompFehlerModus2_11, data-constr=DC_UI1_KompFehlerModus2_11, transfer-property=PENDING, to BMC_HV(timeout 1 s)  # Uebertragung OBD relevanter Fehlerpfade vom Secondary zum Primary Steuergeraet. Zuordnung der generischen Komponentenfehler muss zwischen Sender und Empfaenger abgestimmt werden
          signal UI1_KompFehlerModus2_12_XIX_UI1_Komponentenfehler_01_XIX_BMC_CAN01: start 34, 2 bit, little-endian, data-type-policy=OVERRIDE, i-signal-type=PRIMITIVE, init-value=0, base-type=BT_UI1_KompFehlerModus2_12, compu-method=CM_UI1_KompFehlerModus2_12, data-constr=DC_UI1_KompFehlerModus2_12, transfer-property=PENDING, to BMC_HV(timeout 1 s)  # Uebertragung OBD relevanter Fehlerpfade vom Secondary zum Primary Steuergeraet. Zuordnung der generischen Komponentenfehler muss zwischen Sender und Empfaenger abgestimmt werden
          signal UI1_KompFehlerModus2_13_XIX_UI1_Komponentenfehler_01_XIX_BMC_CAN01: start 36, 2 bit, little-endian, data-type-policy=OVERRIDE, i-signal-type=PRIMITIVE, init-value=0, base-type=BT_UI1_KompFehlerModus2_13, compu-method=CM_UI1_KompFehlerModus2_13, data-constr=DC_UI1_KompFehlerModus2_13, transfer-property=PENDING, to BMC_HV(timeout 1 s)  # Uebertragung OBD relevanter Fehlerpfade vom Secondary zum Primary Steuergeraet. Zuordnung der generischen Komponentenfehler muss zwischen Sender und Empfaenger abgestimmt werden
          signal UI1_KompFehlerModus2_14_XIX_UI1_Komponentenfehler_01_XIX_BMC_CAN01: start 38, 2 bit, little-endian, data-type-policy=OVERRIDE, i-signal-type=PRIMITIVE, init-value=0, base-type=BT_UI1_KompFehlerModus2_14, compu-method=CM_UI1_KompFehlerModus2_14, data-constr=DC_UI1_KompFehlerModus2_14, transfer-property=PENDING, to BMC_HV(timeout 1 s)  # Uebertragung OBD relevanter Fehlerpfade vom Secondary zum Primary Steuergeraet. Zuordnung der generischen Komponentenfehler muss zwischen Sender und Empfaenger abgestimmt werden
          signal UI1_KompFehlerModus2_15_XIX_UI1_Komponentenfehler_01_XIX_BMC_CAN01: start 40, 2 bit, little-endian, data-type-policy=OVERRIDE, i-signal-type=PRIMITIVE, init-value=0, base-type=BT_UI1_KompFehlerModus2_15, compu-method=CM_UI1_KompFehlerModus2_15, data-constr=DC_UI1_KompFehlerModus2_15, transfer-property=PENDING, to BMC_HV(timeout 1 s)  # Uebertragung OBD relevanter Fehlerpfade vom Secondary zum Primary Steuergeraet. Zuordnung der generischen Komponentenfehler muss zwischen Sender und Empfaenger abgestimmt werden
          signal UI1_KompFehlerModus2_16_XIX_UI1_Komponentenfehler_01_XIX_BMC_CAN01: start 42, 2 bit, little-endian, data-type-policy=OVERRIDE, i-signal-type=PRIMITIVE, init-value=0, base-type=BT_UI1_KompFehlerModus2_16, compu-method=CM_UI1_KompFehlerModus2_16, data-constr=DC_UI1_KompFehlerModus2_16, transfer-property=PENDING, to BMC_HV(timeout 1 s)  # Uebertragung OBD relevanter Fehlerpfade vom Secondary zum Primary Steuergeraet. Zuordnung der generischen Komponentenfehler muss zwischen Sender und Empfaenger abgestimmt werden
          signal UI1_KompFehlerModus2_17_XIX_UI1_Komponentenfehler_01_XIX_BMC_CAN01: start 44, 2 bit, little-endian, data-type-policy=OVERRIDE, i-signal-type=PRIMITIVE, init-value=0, base-type=BT_UI1_KompFehlerModus2_17, compu-method=CM_UI1_KompFehlerModus2_17, data-constr=DC_UI1_KompFehlerModus2_17, transfer-property=PENDING, to BMC_HV(timeout 1 s)  # Uebertragung OBD relevanter Fehlerpfade vom Secondary zum Primary Steuergeraet. Zuordnung der generischen Komponentenfehler muss zwischen Sender und Empfaenger abgestimmt werden
          signal UI1_KompFehlerModus2_18_XIX_UI1_Komponentenfehler_01_XIX_BMC_CAN01: start 46, 2 bit, little-endian, data-type-policy=OVERRIDE, i-signal-type=PRIMITIVE, init-value=0, base-type=BT_UI1_KompFehlerModus2_18, compu-method=CM_UI1_KompFehlerModus2_18, data-constr=DC_UI1_KompFehlerModus2_18, transfer-property=PENDING, to BMC_HV(timeout 1 s)  # Uebertragung OBD relevanter Fehlerpfade vom Secondary zum Primary Steuergeraet. Zuordnung der generischen Komponentenfehler muss zwischen Sender und Empfaenger abgestimmt werden
          signal UI1_KompFehlerModus2_19_XIX_UI1_Komponentenfehler_01_XIX_BMC_CAN01: start 48, 2 bit, little-endian, data-type-policy=OVERRIDE, i-signal-type=PRIMITIVE, init-value=0, base-type=BT_UI1_KompFehlerModus2_19, compu-method=CM_UI1_KompFehlerModus2_19, data-constr=DC_UI1_KompFehlerModus2_19, transfer-property=PENDING, to BMC_HV(timeout 1 s)  # Uebertragung OBD relevanter Fehlerpfade vom Secondary zum Primary Steuergeraet. Zuordnung der generischen Komponentenfehler muss zwischen Sender und Empfaenger abgestimmt werden
          signal UI1_KompFehlerModus2_20_XIX_UI1_Komponentenfehler_01_XIX_BMC_CAN01: start 50, 2 bit, little-endian, data-type-policy=OVERRIDE, i-signal-type=PRIMITIVE, init-value=0, base-type=BT_UI1_KompFehlerModus2_20, compu-method=CM_UI1_KompFehlerModus2_20, data-constr=DC_UI1_KompFehlerModus2_20, transfer-property=PENDING, to BMC_HV(timeout 1 s)  # Uebertragung OBD relevanter Fehlerpfade vom Secondary zum Primary Steuergeraet. Zuordnung der generischen Komponentenfehler muss zwischen Sender und Empfaenger abgestimmt werden
          signal UI1_KompFehlerModus2_21_XIX_UI1_Komponentenfehler_01_XIX_BMC_CAN01: start 52, 2 bit, little-endian, data-type-policy=OVERRIDE, i-signal-type=PRIMITIVE, init-value=0, base-type=BT_UI1_KompFehlerModus2_21, compu-method=CM_UI1_KompFehlerModus2_21, data-constr=DC_UI1_KompFehlerModus2_21, transfer-property=PENDING, to BMC_HV(timeout 1 s)  # Uebertragung OBD relevanter Fehlerpfade vom Secondary zum Primary Steuergeraet. Zuordnung der generischen Komponentenfehler muss zwischen Sender und Empfaenger abgestimmt werden
          signal UI1_KompFehlerModus2_22_XIX_UI1_Komponentenfehler_01_XIX_BMC_CAN01: start 54, 2 bit, little-endian, data-type-policy=OVERRIDE, i-signal-type=PRIMITIVE, init-value=0, base-type=BT_UI1_KompFehlerModus2_22, compu-method=CM_UI1_KompFehlerModus2_22, data-constr=DC_UI1_KompFehlerModus2_22, transfer-property=PENDING, to BMC_HV(timeout 1 s)  # Uebertragung OBD relevanter Fehlerpfade vom Secondary zum Primary Steuergeraet. Zuordnung der generischen Komponentenfehler muss zwischen Sender und Empfaenger abgestimmt werden
          signal UI1_KompFehlerModus2_23_XIX_UI1_Komponentenfehler_01_XIX_BMC_CAN01: start 56, 2 bit, little-endian, data-type-policy=OVERRIDE, i-signal-type=PRIMITIVE, init-value=0, base-type=BT_UI1_KompFehlerModus2_23, compu-method=CM_UI1_KompFehlerModus2_23, data-constr=DC_UI1_KompFehlerModus2_23, transfer-property=PENDING, to BMC_HV(timeout 1 s)  # Uebertragung OBD relevanter Fehlerpfade vom Secondary zum Primary Steuergeraet. Zuordnung der generischen Komponentenfehler muss zwischen Sender und Empfaenger abgestimmt werden
          signal UI1_KompFehlerModus2_24_XIX_UI1_Komponentenfehler_01_XIX_BMC_CAN01: start 58, 2 bit, little-endian, data-type-policy=OVERRIDE, i-signal-type=PRIMITIVE, init-value=0, base-type=BT_UI1_KompFehlerModus2_24, compu-method=CM_UI1_KompFehlerModus2_24, data-constr=DC_UI1_KompFehlerModus2_24, transfer-property=PENDING, to BMC_HV(timeout 1 s)  # Uebertragung OBD relevanter Fehlerpfade vom Secondary zum Primary Steuergeraet. Zuordnung der generischen Komponentenfehler muss zwischen Sender und Empfaenger abgestimmt werden
          signal UI1_KompFehlerModus2_25_XIX_UI1_Komponentenfehler_01_XIX_BMC_CAN01: start 60, 2 bit, little-endian, data-type-policy=OVERRIDE, i-signal-type=PRIMITIVE, init-value=0, base-type=BT_UI1_KompFehlerModus2_25, compu-method=CM_UI1_KompFehlerModus2_25, data-constr=DC_UI1_KompFehlerModus2_25, transfer-property=PENDING, to BMC_HV(timeout 1 s)  # Uebertragung OBD relevanter Fehlerpfade vom Secondary zum Primary Steuergeraet. Zuordnung der generischen Komponentenfehler muss zwischen Sender und Empfaenger abgestimmt werden
          signal UI1_KompFehlerModus2_26_XIX_UI1_Komponentenfehler_01_XIX_BMC_CAN01: start 62, 2 bit, little-endian, data-type-policy=OVERRIDE, i-signal-type=PRIMITIVE, init-value=0, base-type=BT_UI1_KompFehlerModus2_26, compu-method=CM_UI1_KompFehlerModus2_26, data-constr=DC_UI1_KompFehlerModus2_26, transfer-property=PENDING, to BMC_HV(timeout 1 s)  # Uebertragung OBD relevanter Fehlerpfade vom Secondary zum Primary Steuergeraet. Zuordnung der generischen Komponentenfehler muss zwischen Sender und Empfaenger abgestimmt werden
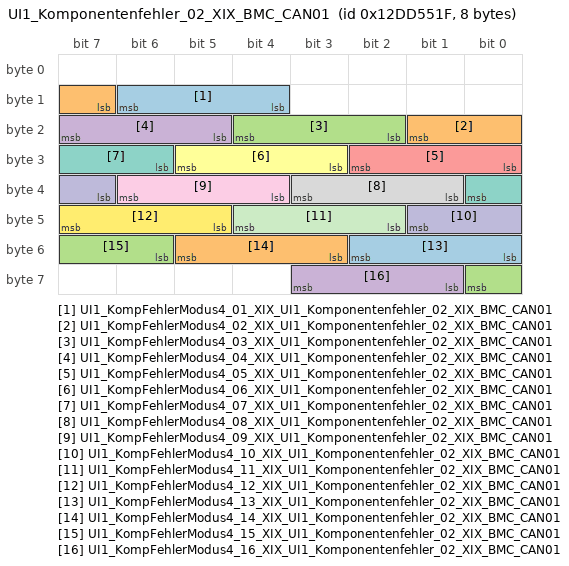
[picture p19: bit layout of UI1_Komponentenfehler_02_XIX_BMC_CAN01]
      frame UI1_Komponentenfehler_02_XIX_BMC_CAN01: id 0x12DD551F, to BMC_HV, frame-length=8, can-addressing-mode=EXTENDED, can-frame-rx-behavior=CAN-20, can-frame-tx-behavior=CAN-20
        pdu UI1_Komponentenfehler_02_XIX_BMC_CAN01: length=8, transmission-mode-true-timing=cyclic-timing={time-offset=0, time-period=0.1}, unused-bit-pattern=0
          signal UI1_KompFehlerModus4_01_XIX_UI1_Komponentenfehler_02_XIX_BMC_CAN01: start 12, 3 bit, little-endian, data-type-policy=OVERRIDE, i-signal-type=PRIMITIVE, init-value=0, base-type=BT_UI1_KompFehlerModus4_01, compu-method=CM_UI1_KompFehlerModus4_01, data-constr=DC_UI1_KompFehlerModus4_01, transfer-property=PENDING, to BMC_HV(timeout 1 s)  # Uebertragung OBD relevanter Fehlerpfade vom Secondary zum Primary Steuergeraet. Zuordnung der generischen Komponentenfehler muss zwischen Sender und Empfaenger abgestimmt werden (3bit Struktur)
          signal UI1_KompFehlerModus4_02_XIX_UI1_Komponentenfehler_02_XIX_BMC_CAN01: start 15, 3 bit, little-endian, data-type-policy=OVERRIDE, i-signal-type=PRIMITIVE, init-value=0, base-type=BT_UI1_KompFehlerModus4_02, compu-method=CM_UI1_KompFehlerModus4_02, data-constr=DC_UI1_KompFehlerModus4_02, transfer-property=PENDING, to BMC_HV(timeout 1 s)  # Uebertragung OBD relevanter Fehlerpfade vom Secondary zum Primary Steuergeraet. Zuordnung der generischen Komponentenfehler muss zwischen Sender und Empfaenger abgestimmt werden (3bit Struktur)
          signal UI1_KompFehlerModus4_03_XIX_UI1_Komponentenfehler_02_XIX_BMC_CAN01: start 18, 3 bit, little-endian, data-type-policy=OVERRIDE, i-signal-type=PRIMITIVE, init-value=0, base-type=BT_UI1_KompFehlerModus4_03, compu-method=CM_UI1_KompFehlerModus4_03, data-constr=DC_UI1_KompFehlerModus4_03, transfer-property=PENDING, to BMC_HV(timeout 1 s)  # Uebertragung OBD relevanter Fehlerpfade vom Secondary zum Primary Steuergeraet. Zuordnung der generischen Komponentenfehler muss zwischen Sender und Empfaenger abgestimmt werden (3bit Struktur)
          signal UI1_KompFehlerModus4_04_XIX_UI1_Komponentenfehler_02_XIX_BMC_CAN01: start 21, 3 bit, little-endian, data-type-policy=OVERRIDE, i-signal-type=PRIMITIVE, init-value=0, base-type=BT_UI1_KompFehlerModus4_04, compu-method=CM_UI1_KompFehlerModus4_04, data-constr=DC_UI1_KompFehlerModus4_04, transfer-property=PENDING, to BMC_HV(timeout 1 s)  # Uebertragung OBD relevanter Fehlerpfade vom Secondary zum Primary Steuergeraet. Zuordnung der generischen Komponentenfehler muss zwischen Sender und Empfaenger abgestimmt werden (3bit Struktur)
          signal UI1_KompFehlerModus4_05_XIX_UI1_Komponentenfehler_02_XIX_BMC_CAN01: start 24, 3 bit, little-endian, data-type-policy=OVERRIDE, i-signal-type=PRIMITIVE, init-value=0, base-type=BT_UI1_KompFehlerModus4_05, compu-method=CM_UI1_KompFehlerModus4_05, data-constr=DC_UI1_KompFehlerModus4_05, transfer-property=PENDING, to BMC_HV(timeout 1 s)  # Uebertragung OBD relevanter Fehlerpfade vom Secondary zum Primary Steuergeraet. Zuordnung der generischen Komponentenfehler muss zwischen Sender und Empfaenger abgestimmt werden (3bit Struktur)
          signal UI1_KompFehlerModus4_06_XIX_UI1_Komponentenfehler_02_XIX_BMC_CAN01: start 27, 3 bit, little-endian, data-type-policy=OVERRIDE, i-signal-type=PRIMITIVE, init-value=0, base-type=BT_UI1_KompFehlerModus4_06, compu-method=CM_UI1_KompFehlerModus4_06, data-constr=DC_UI1_KompFehlerModus4_06, transfer-property=PENDING, to BMC_HV(timeout 1 s)  # Uebertragung OBD relevanter Fehlerpfade vom Secondary zum Primary Steuergeraet. Zuordnung der generischen Komponentenfehler muss zwischen Sender und Empfaenger abgestimmt werden (3bit Struktur)
          signal UI1_KompFehlerModus4_07_XIX_UI1_Komponentenfehler_02_XIX_BMC_CAN01: start 30, 3 bit, little-endian, data-type-policy=OVERRIDE, i-signal-type=PRIMITIVE, init-value=0, base-type=BT_UI1_KompFehlerModus4_07, compu-method=CM_UI1_KompFehlerModus4_07, data-constr=DC_UI1_KompFehlerModus4_07, transfer-property=PENDING, to BMC_HV(timeout 1 s)  # Uebertragung OBD relevanter Fehlerpfade vom Secondary zum Primary Steuergeraet. Zuordnung der generischen Komponentenfehler muss zwischen Sender und Empfaenger abgestimmt werden (3bit Struktur)
          signal UI1_KompFehlerModus4_08_XIX_UI1_Komponentenfehler_02_XIX_BMC_CAN01: start 33, 3 bit, little-endian, data-type-policy=OVERRIDE, i-signal-type=PRIMITIVE, init-value=0, base-type=BT_UI1_KompFehlerModus4_08, compu-method=CM_UI1_KompFehlerModus4_08, data-constr=DC_UI1_KompFehlerModus4_08, transfer-property=PENDING, to BMC_HV(timeout 1 s)  # Uebertragung OBD relevanter Fehlerpfade vom Secondary zum Primary Steuergeraet. Zuordnung der generischen Komponentenfehler muss zwischen Sender und Empfaenger abgestimmt werden (3bit Struktur)
          signal UI1_KompFehlerModus4_09_XIX_UI1_Komponentenfehler_02_XIX_BMC_CAN01: start 36, 3 bit, little-endian, data-type-policy=OVERRIDE, i-signal-type=PRIMITIVE, init-value=0, base-type=BT_UI1_KompFehlerModus4_09, compu-method=CM_UI1_KompFehlerModus4_09, data-constr=DC_UI1_KompFehlerModus4_09, transfer-property=PENDING, to BMC_HV(timeout 1 s)  # Uebertragung OBD relevanter Fehlerpfade vom Secondary zum Primary Steuergeraet. Zuordnung der generischen Komponentenfehler muss zwischen Sender und Empfaenger abgestimmt werden (3bit Struktur)
          signal UI1_KompFehlerModus4_10_XIX_UI1_Komponentenfehler_02_XIX_BMC_CAN01: start 39, 3 bit, little-endian, data-type-policy=OVERRIDE, i-signal-type=PRIMITIVE, init-value=0, base-type=BT_UI1_KompFehlerModus4_10, compu-method=CM_UI1_KompFehlerModus4_10, data-constr=DC_UI1_KompFehlerModus4_10, transfer-property=PENDING, to BMC_HV(timeout 1 s)  # Uebertragung OBD relevanter Fehlerpfade vom Secondary zum Primary Steuergeraet. Zuordnung der generischen Komponentenfehler muss zwischen Sender und Empfaenger abgestimmt werden (3bit Struktur)
          signal UI1_KompFehlerModus4_11_XIX_UI1_Komponentenfehler_02_XIX_BMC_CAN01: start 42, 3 bit, little-endian, data-type-policy=OVERRIDE, i-signal-type=PRIMITIVE, init-value=0, base-type=BT_UI1_KompFehlerModus4_11, compu-method=CM_UI1_KompFehlerModus4_11, data-constr=DC_UI1_KompFehlerModus4_11, transfer-property=PENDING, to BMC_HV(timeout 1 s)  # Uebertragung OBD relevanter Fehlerpfade vom Secondary zum Primary Steuergeraet. Zuordnung der generischen Komponentenfehler muss zwischen Sender und Empfaenger abgestimmt werden (3bit Struktur)
          signal UI1_KompFehlerModus4_12_XIX_UI1_Komponentenfehler_02_XIX_BMC_CAN01: start 45, 3 bit, little-endian, data-type-policy=OVERRIDE, i-signal-type=PRIMITIVE, init-value=0, base-type=BT_UI1_KompFehlerModus4_12, compu-method=CM_UI1_KompFehlerModus4_12, data-constr=DC_UI1_KompFehlerModus4_12, transfer-property=PENDING, to BMC_HV(timeout 1 s)  # Uebertragung OBD relevanter Fehlerpfade vom Secondary zum Primary Steuergeraet. Zuordnung der generischen Komponentenfehler muss zwischen Sender und Empfaenger abgestimmt werden (3bit Struktur)
          signal UI1_KompFehlerModus4_13_XIX_UI1_Komponentenfehler_02_XIX_BMC_CAN01: start 48, 3 bit, little-endian, data-type-policy=OVERRIDE, i-signal-type=PRIMITIVE, init-value=0, base-type=BT_UI1_KompFehlerModus4_13, compu-method=CM_UI1_KompFehlerModus4_13, data-constr=DC_UI1_KompFehlerModus4_13, transfer-property=PENDING, to BMC_HV(timeout 1 s)  # Uebertragung OBD relevanter Fehlerpfade vom Secondary zum Primary Steuergeraet. Zuordnung der generischen Komponentenfehler muss zwischen Sender und Empfaenger abgestimmt werden (3bit Struktur)
          signal UI1_KompFehlerModus4_14_XIX_UI1_Komponentenfehler_02_XIX_BMC_CAN01: start 51, 3 bit, little-endian, data-type-policy=OVERRIDE, i-signal-type=PRIMITIVE, init-value=0, base-type=BT_UI1_KompFehlerModus4_14, compu-method=CM_UI1_KompFehlerModus4_14, data-constr=DC_UI1_KompFehlerModus4_14, transfer-property=PENDING, to BMC_HV(timeout 1 s)  # Uebertragung OBD relevanter Fehlerpfade vom Secondary zum Primary Steuergeraet. Zuordnung der generischen Komponentenfehler muss zwischen Sender und Empfaenger abgestimmt werden (3bit Struktur)
          signal UI1_KompFehlerModus4_15_XIX_UI1_Komponentenfehler_02_XIX_BMC_CAN01: start 54, 3 bit, little-endian, data-type-policy=OVERRIDE, i-signal-type=PRIMITIVE, init-value=0, base-type=BT_UI1_KompFehlerModus4_15, compu-method=CM_UI1_KompFehlerModus4_15, data-constr=DC_UI1_KompFehlerModus4_15, transfer-property=PENDING, to BMC_HV(timeout 1 s)  # Uebertragung OBD relevanter Fehlerpfade vom Secondary zum Primary Steuergeraet. Zuordnung der generischen Komponentenfehler muss zwischen Sender und Empfaenger abgestimmt werden (3bit Struktur)
          signal UI1_KompFehlerModus4_16_XIX_UI1_Komponentenfehler_02_XIX_BMC_CAN01: start 57, 3 bit, little-endian, data-type-policy=OVERRIDE, i-signal-type=PRIMITIVE, init-value=0, base-type=BT_UI1_KompFehlerModus4_16, compu-method=CM_UI1_KompFehlerModus4_16, data-constr=DC_UI1_KompFehlerModus4_16, transfer-property=PENDING, to BMC_HV(timeout 1 s)  # Uebertragung OBD relevanter Fehlerpfade vom Secondary zum Primary Steuergeraet. Zuordnung der generischen Komponentenfehler muss zwischen Sender und Empfaenger abgestimmt werden (3bit Struktur)
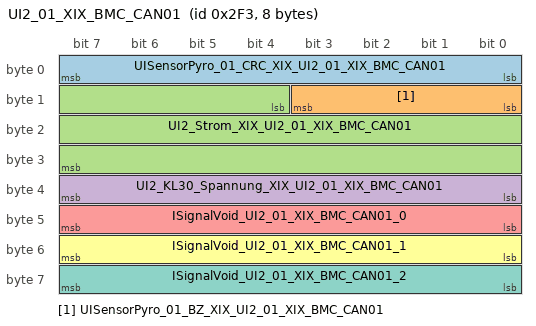
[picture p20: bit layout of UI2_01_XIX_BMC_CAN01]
      frame UI2_01_XIX_BMC_CAN01: id 0x2F3, to BMC_HV, frame-length=8, can-addressing-mode=STANDARD, can-frame-rx-behavior=CAN-20, can-frame-tx-behavior=CAN-20
        pdu UI2_01_XIX_BMC_CAN01_E2E: length=8, transmission-mode-true-timing=event-controlled-timing={number-of-repetitions=0, repetition-period=0}, unused-bit-pattern=0  # Fuer die Botschaft ist das Cyclic-Timing 0.01 zu verwenden.
          signal UISensorPyro_01_CRC_XIX_UI2_01_XIX_BMC_CAN01: start 0, 8 bit, little-endian, data-type-policy=OVERRIDE, i-signal-type=PRIMITIVE, init-value=0, base-type=BT_UISensorPyro_01_CRC, compu-method=CM_UISensorPyro_01_CRC, data-constr=DC_UISensorPyro_01_CRC, to BMC_HV(timeout 0.5 s)
          signal UISensorPyro_01_BZ_XIX_UI2_01_XIX_BMC_CAN01: start 8, 4 bit, little-endian, data-type-policy=OVERRIDE, i-signal-type=PRIMITIVE, init-value=0, base-type=BT_UISensorPyro_01_BZ, compu-method=CM_UISensorPyro_01_BZ, data-constr=DC_UISensorPyro_01_BZ, to BMC_HV(timeout 0.5 s)
          signal UI2_Strom_XIX_UI2_01_XIX_BMC_CAN01: start 12, 20 bit, little-endian, data-type-policy=OVERRIDE, i-signal-type=PRIMITIVE, init-value=1048574, base-type=BT_UI2_Strom, invalid-value=Invalid_UI2_Strom_XIX_UI2_01_XIX_BMC_CAN01:1048575, compu-method=CM_UI2_Strom, data-constr=DC_UI2_Strom, unit=Unit_Unit_Amper, to BMC_HV(timeout 0.5 s)  # "Momentanwert: Batteriestrom Stromrichtung: ein Ladestrom wird mit positiven, ein Entladestrom mit negativen Werten angegeben"
          signal UI2_KL30_Spannung_XIX_UI2_01_XIX_BMC_CAN01: start 32, 8 bit, little-endian, data-type-policy=OVERRIDE, i-signal-type=PRIMITIVE, init-value=254, base-type=BT_UI2_KL30_Spannung, invalid-value=Invalid_UI2_KL30_Spannung_XIX_UI2_01_XIX_BMC_CAN01:255, compu-method=CM_UI2_KL30_Spannung, data-constr=DC_UI2_KL30_Spannung, unit=Unit_Unit_Volt, to BMC_HV(timeout 0.5 s)  # Momentanwert: gemessene Klemme30-Spannung am UI-Sensor
          signal ISignalVoid_UI2_01_XIX_BMC_CAN01_0: start 40, 8 bit, little-endian, system signal SignalVoid_UI2_01_0, data-type-policy=OVERRIDE, i-signal-type=PRIMITIVE, base-type=BT_SignalVoid
          signal ISignalVoid_UI2_01_XIX_BMC_CAN01_1: start 48, 8 bit, little-endian, system signal SignalVoid_UI2_01_1, data-type-policy=OVERRIDE, i-signal-type=PRIMITIVE, base-type=BT_SignalVoid
          signal ISignalVoid_UI2_01_XIX_BMC_CAN01_2: start 56, 8 bit, little-endian, system signal SignalVoid_UI2_01_2, data-type-policy=OVERRIDE, i-signal-type=PRIMITIVE, base-type=BT_SignalVoid
          mapping SG_UI2_01_XIX_BMC_CAN01: i-signal-group=SG_UI2_01_XIX_BMC_CAN01, transfer-property=TRIGGERED-WITHOUT-REPETITION
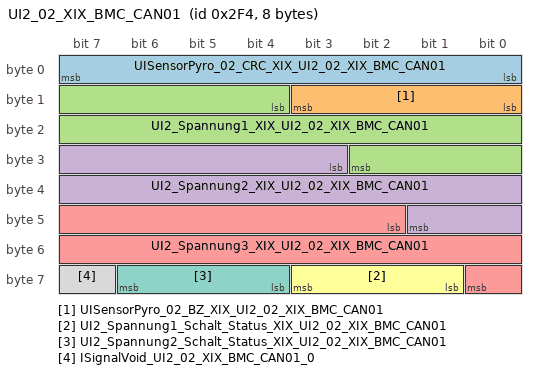
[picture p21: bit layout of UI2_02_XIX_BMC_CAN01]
      frame UI2_02_XIX_BMC_CAN01: id 0x2F4, to BMC_HV, frame-length=8, can-addressing-mode=STANDARD, can-frame-rx-behavior=CAN-20, can-frame-tx-behavior=CAN-20
        pdu UI2_02_XIX_BMC_CAN01_E2E: length=8, transmission-mode-true-timing=event-controlled-timing={number-of-repetitions=0, repetition-period=0}, unused-bit-pattern=0  # Fuer die Botschaft ist das Cyclic-Timing 0.01 zu verwenden.
          signal UISensorPyro_02_CRC_XIX_UI2_02_XIX_BMC_CAN01: start 0, 8 bit, little-endian, data-type-policy=OVERRIDE, i-signal-type=PRIMITIVE, init-value=0, base-type=BT_UISensorPyro_02_CRC, compu-method=CM_UISensorPyro_02_CRC, data-constr=DC_UISensorPyro_02_CRC, to BMC_HV(timeout 0.5 s)
          signal UISensorPyro_02_BZ_XIX_UI2_02_XIX_BMC_CAN01: start 8, 4 bit, little-endian, data-type-policy=OVERRIDE, i-signal-type=PRIMITIVE, init-value=0, base-type=BT_UISensorPyro_02_BZ, compu-method=CM_UISensorPyro_02_BZ, data-constr=DC_UISensorPyro_02_BZ, to BMC_HV(timeout 0.5 s)
          signal UI2_Spannung1_XIX_UI2_02_XIX_BMC_CAN01: start 12, 15 bit, little-endian, data-type-policy=OVERRIDE, i-signal-type=PRIMITIVE, init-value=32766, base-type=BT_UI2_Spannung1, invalid-value=Invalid_UI2_Spannung1_XIX_UI2_02_XIX_BMC_CAN01:32767, compu-method=CM_UI2_Spannung1, data-constr=DC_UI2_Spannung1, unit=Unit_Unit_Volt, to BMC_HV(timeout 0.5 s)  # Spannungsmesskanal 1
          signal UI2_Spannung2_XIX_UI2_02_XIX_BMC_CAN01: start 27, 15 bit, little-endian, data-type-policy=OVERRIDE, i-signal-type=PRIMITIVE, init-value=32766, base-type=BT_UI2_Spannung2, invalid-value=Invalid_UI2_Spannung2_XIX_UI2_02_XIX_BMC_CAN01:32767, compu-method=CM_UI2_Spannung2, data-constr=DC_UI2_Spannung2, unit=Unit_Unit_Volt, to BMC_HV(timeout 0.5 s)  # Spannungsmesskanal 2
          signal UI2_Spannung3_XIX_UI2_02_XIX_BMC_CAN01: start 42, 15 bit, little-endian, data-type-policy=OVERRIDE, i-signal-type=PRIMITIVE, init-value=32766, base-type=BT_UI2_Spannung3, invalid-value=Invalid_UI2_Spannung3_XIX_UI2_02_XIX_BMC_CAN01:32767, compu-method=CM_UI2_Spannung3, data-constr=DC_UI2_Spannung3, unit=Unit_Unit_Volt, to BMC_HV(timeout 0.5 s)  # Spannungsmesskanal 3
          signal UI2_Spannung1_Schalt_Status_XIX_UI2_02_XIX_BMC_CAN01: start 57, 3 bit, little-endian, data-type-policy=OVERRIDE, i-signal-type=PRIMITIVE, init-value=6, base-type=BT_UI2_Spannung1_Schalt_Status, invalid-value=Invalid_UI2_Spannung1_Schalt_Status_XIX_UI2_02_XIX_BMC_CAN01:7, compu-method=CM_UI2_Spannung1_Schalt_Status, data-constr=DC_UI2_Spannung1_Schalt_Status, to BMC_HV(timeout 0.5 s)  # Status des abschaltbaren Spannungsmesskanal1
          signal UI2_Spannung2_Schalt_Status_XIX_UI2_02_XIX_BMC_CAN01: start 60, 3 bit, little-endian, data-type-policy=OVERRIDE, i-signal-type=PRIMITIVE, init-value=6, base-type=BT_UI2_Spannung2_Schalt_Status, invalid-value=Invalid_UI2_Spannung2_Schalt_Status_XIX_UI2_02_XIX_BMC_CAN01:7, compu-method=CM_UI2_Spannung2_Schalt_Status, data-constr=DC_UI2_Spannung2_Schalt_Status, to BMC_HV(timeout 0.5 s)  # Status des abschaltbaren Spannungsmesskanal2
          signal ISignalVoid_UI2_02_XIX_BMC_CAN01_0: start 63, 1 bit, little-endian, system signal SignalVoid_UI2_02_0, data-type-policy=OVERRIDE, i-signal-type=PRIMITIVE, base-type=BT_SignalVoid
          mapping SG_UI2_02_XIX_BMC_CAN01: i-signal-group=SG_UI2_02_XIX_BMC_CAN01, transfer-property=TRIGGERED-WITHOUT-REPETITION
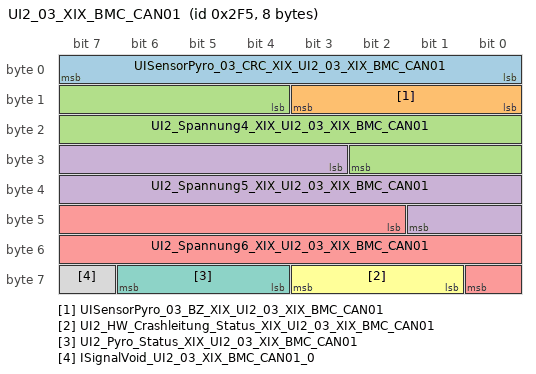
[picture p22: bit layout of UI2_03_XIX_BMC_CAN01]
      frame UI2_03_XIX_BMC_CAN01: id 0x2F5, to BMC_HV, frame-length=8, can-addressing-mode=STANDARD, can-frame-rx-behavior=CAN-20, can-frame-tx-behavior=CAN-20
        pdu UI2_03_XIX_BMC_CAN01_E2E: length=8, transmission-mode-true-timing=event-controlled-timing={number-of-repetitions=0, repetition-period=0}, unused-bit-pattern=0  # Fuer die Botschaft ist das Cyclic-Timing 0.01 zu verwenden.
          signal UISensorPyro_03_CRC_XIX_UI2_03_XIX_BMC_CAN01: start 0, 8 bit, little-endian, data-type-policy=OVERRIDE, i-signal-type=PRIMITIVE, init-value=0, base-type=BT_UISensorPyro_03_CRC, compu-method=CM_UISensorPyro_03_CRC, data-constr=DC_UISensorPyro_03_CRC, to BMC_HV(timeout 0.5 s)
          signal UISensorPyro_03_BZ_XIX_UI2_03_XIX_BMC_CAN01: start 8, 4 bit, little-endian, data-type-policy=OVERRIDE, i-signal-type=PRIMITIVE, init-value=0, base-type=BT_UISensorPyro_03_BZ, compu-method=CM_UISensorPyro_03_BZ, data-constr=DC_UISensorPyro_03_BZ, to BMC_HV(timeout 0.5 s)
          signal UI2_Spannung4_XIX_UI2_03_XIX_BMC_CAN01: start 12, 15 bit, little-endian, data-type-policy=OVERRIDE, i-signal-type=PRIMITIVE, init-value=32766, base-type=BT_UI2_Spannung4, invalid-value=Invalid_UI2_Spannung4_XIX_UI2_03_XIX_BMC_CAN01:32767, compu-method=CM_UI2_Spannung4, data-constr=DC_UI2_Spannung4, unit=Unit_Unit_Volt, to BMC_HV(timeout 0.5 s)  # Spannungsmesskanal 4
          signal UI2_Spannung5_XIX_UI2_03_XIX_BMC_CAN01: start 27, 15 bit, little-endian, data-type-policy=OVERRIDE, i-signal-type=PRIMITIVE, init-value=32766, base-type=BT_UI2_Spannung5, invalid-value=Invalid_UI2_Spannung5_XIX_UI2_03_XIX_BMC_CAN01:32767, compu-method=CM_UI2_Spannung5, data-constr=DC_UI2_Spannung5, unit=Unit_Unit_Volt, to BMC_HV(timeout 0.5 s)  # Spannungsmesskanal 5
          signal UI2_Spannung6_XIX_UI2_03_XIX_BMC_CAN01: start 42, 15 bit, little-endian, data-type-policy=OVERRIDE, i-signal-type=PRIMITIVE, init-value=32766, base-type=BT_UI2_Spannung6, invalid-value=Invalid_UI2_Spannung6_XIX_UI2_03_XIX_BMC_CAN01:32767, compu-method=CM_UI2_Spannung6, data-constr=DC_UI2_Spannung6, unit=Unit_Unit_Volt, to BMC_HV(timeout 0.5 s)  # Spannungsmesskanal 6
          signal UI2_HW_Crashleitung_Status_XIX_UI2_03_XIX_BMC_CAN01: start 57, 3 bit, little-endian, data-type-policy=OVERRIDE, i-signal-type=PRIMITIVE, init-value=0, base-type=BT_UI2_HW_Crashleitung_Status, invalid-value=Invalid_UI2_HW_Crashleitung_Status_XIX_UI2_03_XIX_BMC_CAN01:1, compu-method=CM_UI2_HW_Crashleitung_Status, data-constr=DC_UI2_HW_Crashleitung_Status, to BMC_HV(timeout 0.5 s)  # Status der HW-Crashleitung
          signal UI2_Pyro_Status_XIX_UI2_03_XIX_BMC_CAN01: start 60, 3 bit, little-endian, data-type-policy=OVERRIDE, i-signal-type=PRIMITIVE, init-value=0, base-type=BT_UI2_Pyro_Status, invalid-value=Invalid_UI2_Pyro_Status_XIX_UI2_03_XIX_BMC_CAN01:1, compu-method=CM_UI2_Pyro_Status, data-constr=DC_UI2_Pyro_Status, to BMC_HV(timeout 0.5 s)  # Status für Pyrotrenner
          signal ISignalVoid_UI2_03_XIX_BMC_CAN01_0: start 63, 1 bit, little-endian, system signal SignalVoid_UI2_03_0, data-type-policy=OVERRIDE, i-signal-type=PRIMITIVE, base-type=BT_SignalVoid
          mapping SG_UI2_03_XIX_BMC_CAN01: i-signal-group=SG_UI2_03_XIX_BMC_CAN01, transfer-property=TRIGGERED-WITHOUT-REPETITION
      frame UI2_04_XIX_BMC_CAN01: id 0x12DD545E, to BMC_HV, frame-length=8, can-addressing-mode=EXTENDED, can-frame-rx-behavior=CAN-20, can-frame-tx-behavior=CAN-20
        pdu UI2_04_XIX_BMC_CAN01: length=8, transmission-mode-true-timing=cyclic-timing={time-offset=0, time-period=0.1}, unused-bit-pattern=0
          signal UI2Sens02_ErrMem_State_XIX_UI2_04_XIX_BMC_CAN01: start 13, 2 bit, little-endian, data-type-policy=OVERRIDE, i-signal-type=PRIMITIVE, init-value=2, base-type=BT_UI2Sens02_ErrMem_State, compu-method=CM_UI2Sens02_ErrMem_State, data-constr=DC_UI2Sens02_ErrMem_State, transfer-property=PENDING, to BMC_HV(timeout 1 s)  # Error Memory State
          signal UI2_Status_XIX_UI2_04_XIX_BMC_CAN01: start 15, 1 bit, little-endian, data-type-policy=OVERRIDE, i-signal-type=PRIMITIVE, init-value=0, base-type=BT_UI2_Status, compu-method=CM_UI2_Status, data-constr=DC_UI2_Status, transfer-property=PENDING, to BMC_HV(timeout 1 s)  # dient zur Signalisierung Neustart oder Reset des UI-Sensors
          signal UI2_Stromintegral_Laden_XIX_UI2_04_XIX_BMC_CAN01: start 16, 16 bit, little-endian, data-type-policy=OVERRIDE, i-signal-type=PRIMITIVE, init-value=65534, base-type=BT_UI2_Stromintegral_Laden, invalid-value=Invalid_UI2_Stromintegral_Laden_XIX_UI2_04_XIX_BMC_CAN01:65535, compu-method=CM_UI2_Stromintegral_Laden, data-constr=DC_UI2_Stromintegral_Laden, unit=Unit_Unit_AmperSecon, transfer-property=PENDING, to BMC_HV(timeout 1 s)  # Ladungszaehler des UI-Sensors fuer Laden
          signal UI2_Stromintegral_Entladen_XIX_UI2_04_XIX_BMC_CAN01: start 32, 16 bit, little-endian, data-type-policy=OVERRIDE, i-signal-type=PRIMITIVE, init-value=65534, base-type=BT_UI2_Stromintegral_Entladen, invalid-value=Invalid_UI2_Stromintegral_Entladen_XIX_UI2_04_XIX_BMC_CAN01:65535, compu-method=CM_UI2_Stromintegral_Entladen, data-constr=DC_UI2_Stromintegral_Entladen, unit=Unit_Unit_AmperSecon, transfer-property=PENDING, to BMC_HV(timeout 1 s)  # Ladungszaehler des UI-Sensors fuer Entladen
          signal UI2_Temperatur_1_XIX_UI2_04_XIX_BMC_CAN01: start 48, 8 bit, little-endian, data-type-policy=OVERRIDE, i-signal-type=PRIMITIVE, init-value=254, base-type=BT_UI2_Temperatur_1, invalid-value=Invalid_UI2_Temperatur_1_XIX_UI2_04_XIX_BMC_CAN01:255, compu-method=CM_UI2_Temperatur_1, data-constr=DC_UI2_Temperatur_1, unit=Unit_Unit_DegreCelsi, transfer-property=PENDING, to BMC_HV(timeout 1 s)  # Temperatur 1
          signal UI2_Temperatur_2_XIX_UI2_04_XIX_BMC_CAN01: start 56, 8 bit, little-endian, data-type-policy=OVERRIDE, i-signal-type=PRIMITIVE, init-value=254, base-type=BT_UI2_Temperatur_2, invalid-value=Invalid_UI2_Temperatur_2_XIX_UI2_04_XIX_BMC_CAN01:255, compu-method=CM_UI2_Temperatur_2, data-constr=DC_UI2_Temperatur_2, unit=Unit_Unit_DegreCelsi, transfer-property=PENDING, to BMC_HV(timeout 1 s)  # Temperatur 2
      frame UI2_Komponentenfehler_01_XIX_BMC_CAN01: id 0x12DD5520, to BMC_HV, frame-length=8, can-addressing-mode=EXTENDED, can-frame-rx-behavior=CAN-20, can-frame-tx-behavior=CAN-20
        pdu UI2_Komponentenfehler_01_XIX_BMC_CAN01: length=8, transmission-mode-true-timing=cyclic-timing={time-offset=0, time-period=0.1}, unused-bit-pattern=0
          signal UI2_KompFehlerModus2_01_XIX_UI2_Komponentenfehler_01_XIX_BMC_CAN01: start 12, 2 bit, little-endian, data-type-policy=OVERRIDE, i-signal-type=PRIMITIVE, init-value=0, base-type=BT_UI2_KompFehlerModus2_01, compu-method=CM_UI2_KompFehlerModus2_01, data-constr=DC_UI2_KompFehlerModus2_01, transfer-property=PENDING, to BMC_HV(timeout 1 s)  # Übertragung OBD relevanter Fehlerpfade vom Secondary zum Primary Steuergerät. Zuordnung der generischen Komponentenfehler muss zwischen Sender und Empfänger abgestimmt werden
          signal UI2_KompFehlerModus2_02_XIX_UI2_Komponentenfehler_01_XIX_BMC_CAN01: start 14, 2 bit, little-endian, data-type-policy=OVERRIDE, i-signal-type=PRIMITIVE, init-value=0, base-type=BT_UI2_KompFehlerModus2_02, compu-method=CM_UI2_KompFehlerModus2_02, data-constr=DC_UI2_KompFehlerModus2_02, transfer-property=PENDING, to BMC_HV(timeout 1 s)  # Übertragung OBD relevanter Fehlerpfade vom Secondary zum Primary Steuergerät. Zuordnung der generischen Komponentenfehler muss zwischen Sender und Empfänger abgestimmt werden
          signal UI2_KompFehlerModus2_03_XIX_UI2_Komponentenfehler_01_XIX_BMC_CAN01: start 16, 2 bit, little-endian, data-type-policy=OVERRIDE, i-signal-type=PRIMITIVE, init-value=0, base-type=BT_UI2_KompFehlerModus2_03, compu-method=CM_UI2_KompFehlerModus2_03, data-constr=DC_UI2_KompFehlerModus2_03, transfer-property=PENDING, to BMC_HV(timeout 1 s)  # Übertragung OBD relevanter Fehlerpfade vom Secondary zum Primary Steuergerät. Zuordnung der generischen Komponentenfehler muss zwischen Sender und Empfänger abgestimmt werden
          signal UI2_KompFehlerModus2_04_XIX_UI2_Komponentenfehler_01_XIX_BMC_CAN01: start 18, 2 bit, little-endian, data-type-policy=OVERRIDE, i-signal-type=PRIMITIVE, init-value=0, base-type=BT_UI2_KompFehlerModus2_04, compu-method=CM_UI2_KompFehlerModus2_04, data-constr=DC_UI2_KompFehlerModus2_04, transfer-property=PENDING, to BMC_HV(timeout 1 s)  # Übertragung OBD relevanter Fehlerpfade vom Secondary zum Primary Steuergerät. Zuordnung der generischen Komponentenfehler muss zwischen Sender und Empfänger abgestimmt werden
          signal UI2_KompFehlerModus2_05_XIX_UI2_Komponentenfehler_01_XIX_BMC_CAN01: start 20, 2 bit, little-endian, data-type-policy=OVERRIDE, i-signal-type=PRIMITIVE, init-value=0, base-type=BT_UI2_KompFehlerModus2_05, compu-method=CM_UI2_KompFehlerModus2_05, data-constr=DC_UI2_KompFehlerModus2_05, transfer-property=PENDING, to BMC_HV(timeout 1 s)  # Übertragung OBD relevanter Fehlerpfade vom Secondary zum Primary Steuergerät. Zuordnung der generischen Komponentenfehler muss zwischen Sender und Empfänger abgestimmt werden
          signal UI2_KompFehlerModus2_06_XIX_UI2_Komponentenfehler_01_XIX_BMC_CAN01: start 22, 2 bit, little-endian, data-type-policy=OVERRIDE, i-signal-type=PRIMITIVE, init-value=0, base-type=BT_UI2_KompFehlerModus2_06, compu-method=CM_UI2_KompFehlerModus2_06, data-constr=DC_UI2_KompFehlerModus2_06, transfer-property=PENDING, to BMC_HV(timeout 1 s)  # Übertragung OBD relevanter Fehlerpfade vom Secondary zum Primary Steuergerät. Zuordnung der generischen Komponentenfehler muss zwischen Sender und Empfänger abgestimmt werden
          signal UI2_KompFehlerModus2_07_XIX_UI2_Komponentenfehler_01_XIX_BMC_CAN01: start 24, 2 bit, little-endian, data-type-policy=OVERRIDE, i-signal-type=PRIMITIVE, init-value=0, base-type=BT_UI2_KompFehlerModus2_07, compu-method=CM_UI2_KompFehlerModus2_07, data-constr=DC_UI2_KompFehlerModus2_07, transfer-property=PENDING, to BMC_HV(timeout 1 s)  # Übertragung OBD relevanter Fehlerpfade vom Secondary zum Primary Steuergerät. Zuordnung der generischen Komponentenfehler muss zwischen Sender und Empfänger abgestimmt werden
          signal UI2_KompFehlerModus2_08_XIX_UI2_Komponentenfehler_01_XIX_BMC_CAN01: start 26, 2 bit, little-endian, data-type-policy=OVERRIDE, i-signal-type=PRIMITIVE, init-value=0, base-type=BT_UI2_KompFehlerModus2_08, compu-method=CM_UI2_KompFehlerModus2_08, data-constr=DC_UI2_KompFehlerModus2_08, transfer-property=PENDING, to BMC_HV(timeout 1 s)  # Übertragung OBD relevanter Fehlerpfade vom Secondary zum Primary Steuergerät. Zuordnung der generischen Komponentenfehler muss zwischen Sender und Empfänger abgestimmt werden
          signal UI2_KompFehlerModus2_09_XIX_UI2_Komponentenfehler_01_XIX_BMC_CAN01: start 28, 2 bit, little-endian, data-type-policy=OVERRIDE, i-signal-type=PRIMITIVE, init-value=0, base-type=BT_UI2_KompFehlerModus2_09, compu-method=CM_UI2_KompFehlerModus2_09, data-constr=DC_UI2_KompFehlerModus2_09, transfer-property=PENDING, to BMC_HV(timeout 1 s)  # Übertragung OBD relevanter Fehlerpfade vom Secondary zum Primary Steuergerät. Zuordnung der generischen Komponentenfehler muss zwischen Sender und Empfänger abgestimmt werden
          signal UI2_KompFehlerModus2_10_XIX_UI2_Komponentenfehler_01_XIX_BMC_CAN01: start 30, 2 bit, little-endian, data-type-policy=OVERRIDE, i-signal-type=PRIMITIVE, init-value=0, base-type=BT_UI2_KompFehlerModus2_10, compu-method=CM_UI2_KompFehlerModus2_10, data-constr=DC_UI2_KompFehlerModus2_10, transfer-property=PENDING, to BMC_HV(timeout 1 s)  # Übertragung OBD relevanter Fehlerpfade vom Secondary zum Primary Steuergerät. Zuordnung der generischen Komponentenfehler muss zwischen Sender und Empfänger abgestimmt werden
          signal UI2_KompFehlerModus2_11_XIX_UI2_Komponentenfehler_01_XIX_BMC_CAN01: start 32, 2 bit, little-endian, data-type-policy=OVERRIDE, i-signal-type=PRIMITIVE, init-value=0, base-type=BT_UI2_KompFehlerModus2_11, compu-method=CM_UI2_KompFehlerModus2_11, data-constr=DC_UI2_KompFehlerModus2_11, transfer-property=PENDING, to BMC_HV(timeout 1 s)  # Übertragung OBD relevanter Fehlerpfade vom Secondary zum Primary Steuergerät. Zuordnung der generischen Komponentenfehler muss zwischen Sender und Empfänger abgestimmt werden
          signal UI2_KompFehlerModus2_12_XIX_UI2_Komponentenfehler_01_XIX_BMC_CAN01: start 34, 2 bit, little-endian, data-type-policy=OVERRIDE, i-signal-type=PRIMITIVE, init-value=0, base-type=BT_UI2_KompFehlerModus2_12, compu-method=CM_UI2_KompFehlerModus2_12, data-constr=DC_UI2_KompFehlerModus2_12, transfer-property=PENDING, to BMC_HV(timeout 1 s)  # Übertragung OBD relevanter Fehlerpfade vom Secondary zum Primary Steuergerät. Zuordnung der generischen Komponentenfehler muss zwischen Sender und Empfänger abgestimmt werden
          signal UI2_KompFehlerModus2_13_XIX_UI2_Komponentenfehler_01_XIX_BMC_CAN01: start 36, 2 bit, little-endian, data-type-policy=OVERRIDE, i-signal-type=PRIMITIVE, init-value=0, base-type=BT_UI2_KompFehlerModus2_13, compu-method=CM_UI2_KompFehlerModus2_13, data-constr=DC_UI2_KompFehlerModus2_13, transfer-property=PENDING, to BMC_HV(timeout 1 s)  # Übertragung OBD relevanter Fehlerpfade vom Secondary zum Primary Steuergerät. Zuordnung der generischen Komponentenfehler muss zwischen Sender und Empfänger abgestimmt werden
          signal UI2_KompFehlerModus2_14_XIX_UI2_Komponentenfehler_01_XIX_BMC_CAN01: start 38, 2 bit, little-endian, data-type-policy=OVERRIDE, i-signal-type=PRIMITIVE, init-value=0, base-type=BT_UI2_KompFehlerModus2_14, compu-method=CM_UI2_KompFehlerModus2_14, data-constr=DC_UI2_KompFehlerModus2_14, transfer-property=PENDING, to BMC_HV(timeout 1 s)  # Übertragung OBD relevanter Fehlerpfade vom Secondary zum Primary Steuergerät. Zuordnung der generischen Komponentenfehler muss zwischen Sender und Empfänger abgestimmt werden
          signal UI2_KompFehlerModus2_15_XIX_UI2_Komponentenfehler_01_XIX_BMC_CAN01: start 40, 2 bit, little-endian, data-type-policy=OVERRIDE, i-signal-type=PRIMITIVE, init-value=0, base-type=BT_UI2_KompFehlerModus2_15, compu-method=CM_UI2_KompFehlerModus2_15, data-constr=DC_UI2_KompFehlerModus2_15, transfer-property=PENDING, to BMC_HV(timeout 1 s)  # Übertragung OBD relevanter Fehlerpfade vom Secondary zum Primary Steuergerät. Zuordnung der generischen Komponentenfehler muss zwischen Sender und Empfänger abgestimmt werden
          signal UI2_KompFehlerModus2_16_XIX_UI2_Komponentenfehler_01_XIX_BMC_CAN01: start 42, 2 bit, little-endian, data-type-policy=OVERRIDE, i-signal-type=PRIMITIVE, init-value=0, base-type=BT_UI2_KompFehlerModus2_16, compu-method=CM_UI2_KompFehlerModus2_16, data-constr=DC_UI2_KompFehlerModus2_16, transfer-property=PENDING, to BMC_HV(timeout 1 s)  # Übertragung OBD relevanter Fehlerpfade vom Secondary zum Primary Steuergerät. Zuordnung der generischen Komponentenfehler muss zwischen Sender und Empfänger abgestimmt werden
          signal UI2_KompFehlerModus2_17_XIX_UI2_Komponentenfehler_01_XIX_BMC_CAN01: start 44, 2 bit, little-endian, data-type-policy=OVERRIDE, i-signal-type=PRIMITIVE, init-value=0, base-type=BT_UI2_KompFehlerModus2_17, compu-method=CM_UI2_KompFehlerModus2_17, data-constr=DC_UI2_KompFehlerModus2_17, transfer-property=PENDING, to BMC_HV(timeout 1 s)  # Übertragung OBD relevanter Fehlerpfade vom Secondary zum Primary Steuergerät. Zuordnung der generischen Komponentenfehler muss zwischen Sender und Empfänger abgestimmt werden
          signal UI2_KompFehlerModus2_18_XIX_UI2_Komponentenfehler_01_XIX_BMC_CAN01: start 46, 2 bit, little-endian, data-type-policy=OVERRIDE, i-signal-type=PRIMITIVE, init-value=0, base-type=BT_UI2_KompFehlerModus2_18, compu-method=CM_UI2_KompFehlerModus2_18, data-constr=DC_UI2_KompFehlerModus2_18, transfer-property=PENDING, to BMC_HV(timeout 1 s)  # Übertragung OBD relevanter Fehlerpfade vom Secondary zum Primary Steuergerät. Zuordnung der generischen Komponentenfehler muss zwischen Sender und Empfänger abgestimmt werden
          signal UI2_KompFehlerModus2_19_XIX_UI2_Komponentenfehler_01_XIX_BMC_CAN01: start 48, 2 bit, little-endian, data-type-policy=OVERRIDE, i-signal-type=PRIMITIVE, init-value=0, base-type=BT_UI2_KompFehlerModus2_19, compu-method=CM_UI2_KompFehlerModus2_19, data-constr=DC_UI2_KompFehlerModus2_19, transfer-property=PENDING, to BMC_HV(timeout 1 s)  # Übertragung OBD relevanter Fehlerpfade vom Secondary zum Primary Steuergerät. Zuordnung der generischen Komponentenfehler muss zwischen Sender und Empfänger abgestimmt werden
          signal UI2_KompFehlerModus2_20_XIX_UI2_Komponentenfehler_01_XIX_BMC_CAN01: start 50, 2 bit, little-endian, data-type-policy=OVERRIDE, i-signal-type=PRIMITIVE, init-value=0, base-type=BT_UI2_KompFehlerModus2_20, compu-method=CM_UI2_KompFehlerModus2_20, data-constr=DC_UI2_KompFehlerModus2_20, transfer-property=PENDING, to BMC_HV(timeout 1 s)  # Übertragung OBD relevanter Fehlerpfade vom Secondary zum Primary Steuergerät. Zuordnung der generischen Komponentenfehler muss zwischen Sender und Empfänger abgestimmt werden
          signal UI2_KompFehlerModus2_21_XIX_UI2_Komponentenfehler_01_XIX_BMC_CAN01: start 52, 2 bit, little-endian, data-type-policy=OVERRIDE, i-signal-type=PRIMITIVE, init-value=0, base-type=BT_UI2_KompFehlerModus2_21, compu-method=CM_UI2_KompFehlerModus2_21, data-constr=DC_UI2_KompFehlerModus2_21, transfer-property=PENDING, to BMC_HV(timeout 1 s)  # Übertragung OBD relevanter Fehlerpfade vom Secondary zum Primary Steuergerät. Zuordnung der generischen Komponentenfehler muss zwischen Sender und Empfänger abgestimmt werden
          signal UI2_KompFehlerModus2_22_XIX_UI2_Komponentenfehler_01_XIX_BMC_CAN01: start 54, 2 bit, little-endian, data-type-policy=OVERRIDE, i-signal-type=PRIMITIVE, init-value=0, base-type=BT_UI2_KompFehlerModus2_22, compu-method=CM_UI2_KompFehlerModus2_22, data-constr=DC_UI2_KompFehlerModus2_22, transfer-property=PENDING, to BMC_HV(timeout 1 s)  # Übertragung OBD relevanter Fehlerpfade vom Secondary zum Primary Steuergerät. Zuordnung der generischen Komponentenfehler muss zwischen Sender und Empfänger abgestimmt werden
          signal UI2_KompFehlerModus2_23_XIX_UI2_Komponentenfehler_01_XIX_BMC_CAN01: start 56, 2 bit, little-endian, data-type-policy=OVERRIDE, i-signal-type=PRIMITIVE, init-value=0, base-type=BT_UI2_KompFehlerModus2_23, compu-method=CM_UI2_KompFehlerModus2_23, data-constr=DC_UI2_KompFehlerModus2_23, transfer-property=PENDING, to BMC_HV(timeout 1 s)  # Übertragung OBD relevanter Fehlerpfade vom Secondary zum Primary Steuergerät. Zuordnung der generischen Komponentenfehler muss zwischen Sender und Empfänger abgestimmt werden
          signal UI2_KompFehlerModus2_24_XIX_UI2_Komponentenfehler_01_XIX_BMC_CAN01: start 58, 2 bit, little-endian, data-type-policy=OVERRIDE, i-signal-type=PRIMITIVE, init-value=0, base-type=BT_UI2_KompFehlerModus2_24, compu-method=CM_UI2_KompFehlerModus2_24, data-constr=DC_UI2_KompFehlerModus2_24, transfer-property=PENDING, to BMC_HV(timeout 1 s)  # Übertragung OBD relevanter Fehlerpfade vom Secondary zum Primary Steuergerät. Zuordnung der generischen Komponentenfehler muss zwischen Sender und Empfänger abgestimmt werden
          signal UI2_KompFehlerModus2_25_XIX_UI2_Komponentenfehler_01_XIX_BMC_CAN01: start 60, 2 bit, little-endian, data-type-policy=OVERRIDE, i-signal-type=PRIMITIVE, init-value=0, base-type=BT_UI2_KompFehlerModus2_25, compu-method=CM_UI2_KompFehlerModus2_25, data-constr=DC_UI2_KompFehlerModus2_25, transfer-property=PENDING, to BMC_HV(timeout 1 s)  # Uebertragung OBD relevanter Fehlerpfade vom Secondary zum Primary Steuergeraet. Zuordnung der generischen Komponentenfehler muss zwischen Sender und Empfaenger abgestimmt werden
          signal UI2_KompFehlerModus2_26_XIX_UI2_Komponentenfehler_01_XIX_BMC_CAN01: start 62, 2 bit, little-endian, data-type-policy=OVERRIDE, i-signal-type=PRIMITIVE, init-value=0, base-type=BT_UI2_KompFehlerModus2_26, compu-method=CM_UI2_KompFehlerModus2_26, data-constr=DC_UI2_KompFehlerModus2_26, transfer-property=PENDING, to BMC_HV(timeout 1 s)  # Uebertragung OBD relevanter Fehlerpfade vom Secondary zum Primary Steuergeraet. Zuordnung der generischen Komponentenfehler muss zwischen Sender und Empfaenger abgestimmt werden
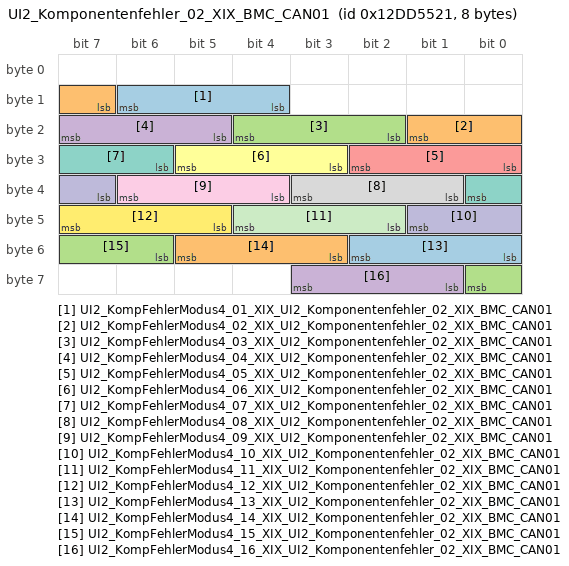
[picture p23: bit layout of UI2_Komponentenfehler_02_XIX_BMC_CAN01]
      frame UI2_Komponentenfehler_02_XIX_BMC_CAN01: id 0x12DD5521, to BMC_HV, frame-length=8, can-addressing-mode=EXTENDED, can-frame-rx-behavior=CAN-20, can-frame-tx-behavior=CAN-20
        pdu UI2_Komponentenfehler_02_XIX_BMC_CAN01: length=8, transmission-mode-true-timing=cyclic-timing={time-offset=0, time-period=0.1}, unused-bit-pattern=0
          signal UI2_KompFehlerModus4_01_XIX_UI2_Komponentenfehler_02_XIX_BMC_CAN01: start 12, 3 bit, little-endian, data-type-policy=OVERRIDE, i-signal-type=PRIMITIVE, init-value=0, base-type=BT_UI2_KompFehlerModus4_01, compu-method=CM_UI2_KompFehlerModus4_01, data-constr=DC_UI2_KompFehlerModus4_01, transfer-property=PENDING, to BMC_HV(timeout 1 s)  # Übertragung OBD relevanter Fehlerpfade vom Secondary zum Primary Steuergerät. Zuordnung der generischen Komponentenfehler muss zwischen Sender und Empfänger abgestimmt werden (3bit Struktur)
          signal UI2_KompFehlerModus4_02_XIX_UI2_Komponentenfehler_02_XIX_BMC_CAN01: start 15, 3 bit, little-endian, data-type-policy=OVERRIDE, i-signal-type=PRIMITIVE, init-value=0, base-type=BT_UI2_KompFehlerModus4_02, compu-method=CM_UI2_KompFehlerModus4_02, data-constr=DC_UI2_KompFehlerModus4_02, transfer-property=PENDING, to BMC_HV(timeout 1 s)  # Übertragung OBD relevanter Fehlerpfade vom Secondary zum Primary Steuergerät. Zuordnung der generischen Komponentenfehler muss zwischen Sender und Empfänger abgestimmt werden (3bit Struktur)
          signal UI2_KompFehlerModus4_03_XIX_UI2_Komponentenfehler_02_XIX_BMC_CAN01: start 18, 3 bit, little-endian, data-type-policy=OVERRIDE, i-signal-type=PRIMITIVE, init-value=0, base-type=BT_UI2_KompFehlerModus4_03, compu-method=CM_UI2_KompFehlerModus4_03, data-constr=DC_UI2_KompFehlerModus4_03, transfer-property=PENDING, to BMC_HV(timeout 1 s)  # Übertragung OBD relevanter Fehlerpfade vom Secondary zum Primary Steuergerät. Zuordnung der generischen Komponentenfehler muss zwischen Sender und Empfänger abgestimmt werden (3bit Struktur)
          signal UI2_KompFehlerModus4_04_XIX_UI2_Komponentenfehler_02_XIX_BMC_CAN01: start 21, 3 bit, little-endian, data-type-policy=OVERRIDE, i-signal-type=PRIMITIVE, init-value=0, base-type=BT_UI2_KompFehlerModus4_04, compu-method=CM_UI2_KompFehlerModus4_04, data-constr=DC_UI2_KompFehlerModus4_04, transfer-property=PENDING, to BMC_HV(timeout 1 s)  # Übertragung OBD relevanter Fehlerpfade vom Secondary zum Primary Steuergerät. Zuordnung der generischen Komponentenfehler muss zwischen Sender und Empfänger abgestimmt werden (3bit Struktur)
          signal UI2_KompFehlerModus4_05_XIX_UI2_Komponentenfehler_02_XIX_BMC_CAN01: start 24, 3 bit, little-endian, data-type-policy=OVERRIDE, i-signal-type=PRIMITIVE, init-value=0, base-type=BT_UI2_KompFehlerModus4_05, compu-method=CM_UI2_KompFehlerModus4_05, data-constr=DC_UI2_KompFehlerModus4_05, transfer-property=PENDING, to BMC_HV(timeout 1 s)  # Übertragung OBD relevanter Fehlerpfade vom Secondary zum Primary Steuergerät. Zuordnung der generischen Komponentenfehler muss zwischen Sender und Empfänger abgestimmt werden (3bit Struktur)
          signal UI2_KompFehlerModus4_06_XIX_UI2_Komponentenfehler_02_XIX_BMC_CAN01: start 27, 3 bit, little-endian, data-type-policy=OVERRIDE, i-signal-type=PRIMITIVE, init-value=0, base-type=BT_UI2_KompFehlerModus4_06, compu-method=CM_UI2_KompFehlerModus4_06, data-constr=DC_UI2_KompFehlerModus4_06, transfer-property=PENDING, to BMC_HV(timeout 1 s)  # Übertragung OBD relevanter Fehlerpfade vom Secondary zum Primary Steuergerät. Zuordnung der generischen Komponentenfehler muss zwischen Sender und Empfänger abgestimmt werden (3bit Struktur)
          signal UI2_KompFehlerModus4_07_XIX_UI2_Komponentenfehler_02_XIX_BMC_CAN01: start 30, 3 bit, little-endian, data-type-policy=OVERRIDE, i-signal-type=PRIMITIVE, init-value=0, base-type=BT_UI2_KompFehlerModus4_07, compu-method=CM_UI2_KompFehlerModus4_07, data-constr=DC_UI2_KompFehlerModus4_07, transfer-property=PENDING, to BMC_HV(timeout 1 s)  # Übertragung OBD relevanter Fehlerpfade vom Secondary zum Primary Steuergerät. Zuordnung der generischen Komponentenfehler muss zwischen Sender und Empfänger abgestimmt werden (3bit Struktur)
          signal UI2_KompFehlerModus4_08_XIX_UI2_Komponentenfehler_02_XIX_BMC_CAN01: start 33, 3 bit, little-endian, data-type-policy=OVERRIDE, i-signal-type=PRIMITIVE, init-value=0, base-type=BT_UI2_KompFehlerModus4_08, compu-method=CM_UI2_KompFehlerModus4_08, data-constr=DC_UI2_KompFehlerModus4_08, transfer-property=PENDING, to BMC_HV(timeout 1 s)  # Übertragung OBD relevanter Fehlerpfade vom Secondary zum Primary Steuergerät. Zuordnung der generischen Komponentenfehler muss zwischen Sender und Empfänger abgestimmt werden (3bit Struktur)
          signal UI2_KompFehlerModus4_09_XIX_UI2_Komponentenfehler_02_XIX_BMC_CAN01: start 36, 3 bit, little-endian, data-type-policy=OVERRIDE, i-signal-type=PRIMITIVE, init-value=0, base-type=BT_UI2_KompFehlerModus4_09, compu-method=CM_UI2_KompFehlerModus4_09, data-constr=DC_UI2_KompFehlerModus4_09, transfer-property=PENDING, to BMC_HV(timeout 1 s)  # Übertragung OBD relevanter Fehlerpfade vom Secondary zum Primary Steuergerät. Zuordnung der generischen Komponentenfehler muss zwischen Sender und Empfänger abgestimmt werden (3bit Struktur)
          signal UI2_KompFehlerModus4_10_XIX_UI2_Komponentenfehler_02_XIX_BMC_CAN01: start 39, 3 bit, little-endian, data-type-policy=OVERRIDE, i-signal-type=PRIMITIVE, init-value=0, base-type=BT_UI2_KompFehlerModus4_10, compu-method=CM_UI2_KompFehlerModus4_10, data-constr=DC_UI2_KompFehlerModus4_10, transfer-property=PENDING, to BMC_HV(timeout 1 s)  # Übertragung OBD relevanter Fehlerpfade vom Secondary zum Primary Steuergerät. Zuordnung der generischen Komponentenfehler muss zwischen Sender und Empfänger abgestimmt werden (3bit Struktur)
          signal UI2_KompFehlerModus4_11_XIX_UI2_Komponentenfehler_02_XIX_BMC_CAN01: start 42, 3 bit, little-endian, data-type-policy=OVERRIDE, i-signal-type=PRIMITIVE, init-value=0, base-type=BT_UI2_KompFehlerModus4_11, compu-method=CM_UI2_KompFehlerModus4_11, data-constr=DC_UI2_KompFehlerModus4_11, transfer-property=PENDING, to BMC_HV(timeout 1 s)  # Übertragung OBD relevanter Fehlerpfade vom Secondary zum Primary Steuergerät. Zuordnung der generischen Komponentenfehler muss zwischen Sender und Empfänger abgestimmt werden (3bit Struktur)
          signal UI2_KompFehlerModus4_12_XIX_UI2_Komponentenfehler_02_XIX_BMC_CAN01: start 45, 3 bit, little-endian, data-type-policy=OVERRIDE, i-signal-type=PRIMITIVE, init-value=0, base-type=BT_UI2_KompFehlerModus4_12, compu-method=CM_UI2_KompFehlerModus4_12, data-constr=DC_UI2_KompFehlerModus4_12, transfer-property=PENDING, to BMC_HV(timeout 1 s)  # Übertragung OBD relevanter Fehlerpfade vom Secondary zum Primary Steuergerät. Zuordnung der generischen Komponentenfehler muss zwischen Sender und Empfänger abgestimmt werden (3bit Struktur)
          signal UI2_KompFehlerModus4_13_XIX_UI2_Komponentenfehler_02_XIX_BMC_CAN01: start 48, 3 bit, little-endian, data-type-policy=OVERRIDE, i-signal-type=PRIMITIVE, init-value=0, base-type=BT_UI2_KompFehlerModus4_13, compu-method=CM_UI2_KompFehlerModus4_13, data-constr=DC_UI2_KompFehlerModus4_13, transfer-property=PENDING, to BMC_HV(timeout 1 s)  # Übertragung OBD relevanter Fehlerpfade vom Secondary zum Primary Steuergerät. Zuordnung der generischen Komponentenfehler muss zwischen Sender und Empfänger abgestimmt werden (3bit Struktur)
          signal UI2_KompFehlerModus4_14_XIX_UI2_Komponentenfehler_02_XIX_BMC_CAN01: start 51, 3 bit, little-endian, data-type-policy=OVERRIDE, i-signal-type=PRIMITIVE, init-value=0, base-type=BT_UI2_KompFehlerModus4_14, compu-method=CM_UI2_KompFehlerModus4_14, data-constr=DC_UI2_KompFehlerModus4_14, transfer-property=PENDING, to BMC_HV(timeout 1 s)  # Übertragung OBD relevanter Fehlerpfade vom Secondary zum Primary Steuergerät. Zuordnung der generischen Komponentenfehler muss zwischen Sender und Empfänger abgestimmt werden (3bit Struktur)
          signal UI2_KompFehlerModus4_15_XIX_UI2_Komponentenfehler_02_XIX_BMC_CAN01: start 54, 3 bit, little-endian, data-type-policy=OVERRIDE, i-signal-type=PRIMITIVE, init-value=0, base-type=BT_UI2_KompFehlerModus4_15, compu-method=CM_UI2_KompFehlerModus4_15, data-constr=DC_UI2_KompFehlerModus4_15, transfer-property=PENDING, to BMC_HV(timeout 1 s)  # Übertragung OBD relevanter Fehlerpfade vom Secondary zum Primary Steuergerät. Zuordnung der generischen Komponentenfehler muss zwischen Sender und Empfänger abgestimmt werden (3bit Struktur)
          signal UI2_KompFehlerModus4_16_XIX_UI2_Komponentenfehler_02_XIX_BMC_CAN01: start 57, 3 bit, little-endian, data-type-policy=OVERRIDE, i-signal-type=PRIMITIVE, init-value=0, base-type=BT_UI2_KompFehlerModus4_16, compu-method=CM_UI2_KompFehlerModus4_16, data-constr=DC_UI2_KompFehlerModus4_16, transfer-property=PENDING, to BMC_HV(timeout 1 s)  # Übertragung OBD relevanter Fehlerpfade vom Secondary zum Primary Steuergerät. Zuordnung der generischen Komponentenfehler muss zwischen Sender und Empfänger abgestimmt werden (3bit Struktur)
      frame UI2Sens01_CALID_01_XIX_BMC_CAN01: id 0x1A5554C6, to BMC_HV, frame-length=8, can-addressing-mode=EXTENDED, can-frame-rx-behavior=CAN-20, can-frame-tx-behavior=CAN-20
        pdu UI2Sens01_CALID_01_XIX_BMC_CAN01: length=8, transmission-mode-true-timing=cyclic-timing={time-offset=0, time-period=1}, unused-bit-pattern=0
          signal UI2Sens01_CALID_Index_01_XIX_UI2Sens01_CALID_01_XIX_BMC_CAN01: start 0, 8 bit, little-endian, data-type-policy=OVERRIDE, i-signal-type=PRIMITIVE, init-value=63, base-type=BT_UI2Sens01_CALID_Index_01, compu-method=CM_UI2Sens01_CALID_Index_01, data-constr=DC_UI2Sens01_CALID_Index_01, transfer-property=PENDING, to BMC_HV(timeout 5 s)  # Calibration Identification
          signal UI2Sens01_CALID_Index_02_XIX_UI2Sens01_CALID_01_XIX_BMC_CAN01: start 8, 8 bit, little-endian, data-type-policy=OVERRIDE, i-signal-type=PRIMITIVE, init-value=63, base-type=BT_UI2Sens01_CALID_Index_02, compu-method=CM_UI2Sens01_CALID_Index_02, data-constr=DC_UI2Sens01_CALID_Index_02, transfer-property=PENDING, to BMC_HV(timeout 5 s)  # Calibration Identification
          signal UI2Sens01_CALID_Index_03_XIX_UI2Sens01_CALID_01_XIX_BMC_CAN01: start 16, 8 bit, little-endian, data-type-policy=OVERRIDE, i-signal-type=PRIMITIVE, init-value=63, base-type=BT_UI2Sens01_CALID_Index_03, compu-method=CM_UI2Sens01_CALID_Index_03, data-constr=DC_UI2Sens01_CALID_Index_03, transfer-property=PENDING, to BMC_HV(timeout 5 s)  # Calibration Identification
          signal UI2Sens01_CALID_Index_04_XIX_UI2Sens01_CALID_01_XIX_BMC_CAN01: start 24, 8 bit, little-endian, data-type-policy=OVERRIDE, i-signal-type=PRIMITIVE, init-value=63, base-type=BT_UI2Sens01_CALID_Index_04, compu-method=CM_UI2Sens01_CALID_Index_04, data-constr=DC_UI2Sens01_CALID_Index_04, transfer-property=PENDING, to BMC_HV(timeout 5 s)  # Calibration Identification
          signal UI2Sens01_CALID_Index_05_XIX_UI2Sens01_CALID_01_XIX_BMC_CAN01: start 32, 8 bit, little-endian, data-type-policy=OVERRIDE, i-signal-type=PRIMITIVE, init-value=63, base-type=BT_UI2Sens01_CALID_Index_05, compu-method=CM_UI2Sens01_CALID_Index_05, data-constr=DC_UI2Sens01_CALID_Index_05, transfer-property=PENDING, to BMC_HV(timeout 5 s)  # Calibration Identification
          signal UI2Sens01_CALID_Index_06_XIX_UI2Sens01_CALID_01_XIX_BMC_CAN01: start 40, 8 bit, little-endian, data-type-policy=OVERRIDE, i-signal-type=PRIMITIVE, init-value=63, base-type=BT_UI2Sens01_CALID_Index_06, compu-method=CM_UI2Sens01_CALID_Index_06, data-constr=DC_UI2Sens01_CALID_Index_06, transfer-property=PENDING, to BMC_HV(timeout 5 s)  # Calibration Identification
          signal UI2Sens01_CALID_Index_07_XIX_UI2Sens01_CALID_01_XIX_BMC_CAN01: start 48, 8 bit, little-endian, data-type-policy=OVERRIDE, i-signal-type=PRIMITIVE, init-value=63, base-type=BT_UI2Sens01_CALID_Index_07, compu-method=CM_UI2Sens01_CALID_Index_07, data-constr=DC_UI2Sens01_CALID_Index_07, transfer-property=PENDING, to BMC_HV(timeout 5 s)  # Calibration Identification
          signal UI2Sens01_CALID_Index_08_XIX_UI2Sens01_CALID_01_XIX_BMC_CAN01: start 56, 8 bit, little-endian, data-type-policy=OVERRIDE, i-signal-type=PRIMITIVE, init-value=63, base-type=BT_UI2Sens01_CALID_Index_08, compu-method=CM_UI2Sens01_CALID_Index_08, data-constr=DC_UI2Sens01_CALID_Index_08, transfer-property=PENDING, to BMC_HV(timeout 5 s)  # Calibration Identification
      frame UI2Sens01_CALID_02_XIX_BMC_CAN01: id 0x1A5554C7, to BMC_HV, frame-length=8, can-addressing-mode=EXTENDED, can-frame-rx-behavior=CAN-20, can-frame-tx-behavior=CAN-20
        pdu UI2Sens01_CALID_02_XIX_BMC_CAN01: length=8, transmission-mode-true-timing=cyclic-timing={time-offset=0, time-period=1}, unused-bit-pattern=0
          signal UI2Sens01_CALID_Index_09_XIX_UI2Sens01_CALID_02_XIX_BMC_CAN01: start 0, 8 bit, little-endian, data-type-policy=OVERRIDE, i-signal-type=PRIMITIVE, init-value=63, base-type=BT_UI2Sens01_CALID_Index_09, compu-method=CM_UI2Sens01_CALID_Index_09, data-constr=DC_UI2Sens01_CALID_Index_09, transfer-property=PENDING, to BMC_HV(timeout 5 s)  # Calibration Identification
          signal UI2Sens01_CALID_Index_10_XIX_UI2Sens01_CALID_02_XIX_BMC_CAN01: start 8, 8 bit, little-endian, data-type-policy=OVERRIDE, i-signal-type=PRIMITIVE, init-value=63, base-type=BT_UI2Sens01_CALID_Index_10, compu-method=CM_UI2Sens01_CALID_Index_10, data-constr=DC_UI2Sens01_CALID_Index_10, transfer-property=PENDING, to BMC_HV(timeout 5 s)  # Calibration Identification
          signal UI2Sens01_CALID_Index_11_XIX_UI2Sens01_CALID_02_XIX_BMC_CAN01: start 16, 8 bit, little-endian, data-type-policy=OVERRIDE, i-signal-type=PRIMITIVE, init-value=63, base-type=BT_UI2Sens01_CALID_Index_11, compu-method=CM_UI2Sens01_CALID_Index_11, data-constr=DC_UI2Sens01_CALID_Index_11, transfer-property=PENDING, to BMC_HV(timeout 5 s)  # Calibration Identification
          signal UI2Sens01_CALID_Index_12_XIX_UI2Sens01_CALID_02_XIX_BMC_CAN01: start 24, 8 bit, little-endian, data-type-policy=OVERRIDE, i-signal-type=PRIMITIVE, init-value=63, base-type=BT_UI2Sens01_CALID_Index_12, compu-method=CM_UI2Sens01_CALID_Index_12, data-constr=DC_UI2Sens01_CALID_Index_12, transfer-property=PENDING, to BMC_HV(timeout 5 s)  # Calibration Identification
          signal UI2Sens01_CALID_Index_13_XIX_UI2Sens01_CALID_02_XIX_BMC_CAN01: start 32, 8 bit, little-endian, data-type-policy=OVERRIDE, i-signal-type=PRIMITIVE, init-value=63, base-type=BT_UI2Sens01_CALID_Index_13, compu-method=CM_UI2Sens01_CALID_Index_13, data-constr=DC_UI2Sens01_CALID_Index_13, transfer-property=PENDING, to BMC_HV(timeout 5 s)  # Calibration Identification
          signal UI2Sens01_CALID_Index_14_XIX_UI2Sens01_CALID_02_XIX_BMC_CAN01: start 40, 8 bit, little-endian, data-type-policy=OVERRIDE, i-signal-type=PRIMITIVE, init-value=63, base-type=BT_UI2Sens01_CALID_Index_14, compu-method=CM_UI2Sens01_CALID_Index_14, data-constr=DC_UI2Sens01_CALID_Index_14, transfer-property=PENDING, to BMC_HV(timeout 5 s)  # Calibration Identification
          signal UI2Sens01_CALID_Index_15_XIX_UI2Sens01_CALID_02_XIX_BMC_CAN01: start 48, 8 bit, little-endian, data-type-policy=OVERRIDE, i-signal-type=PRIMITIVE, init-value=63, base-type=BT_UI2Sens01_CALID_Index_15, compu-method=CM_UI2Sens01_CALID_Index_15, data-constr=DC_UI2Sens01_CALID_Index_15, transfer-property=PENDING, to BMC_HV(timeout 5 s)  # Calibration Identification
          signal UI2Sens01_CALID_Index_16_XIX_UI2Sens01_CALID_02_XIX_BMC_CAN01: start 56, 8 bit, little-endian, data-type-policy=OVERRIDE, i-signal-type=PRIMITIVE, init-value=63, base-type=BT_UI2Sens01_CALID_Index_16, compu-method=CM_UI2Sens01_CALID_Index_16, data-constr=DC_UI2Sens01_CALID_Index_16, transfer-property=PENDING, to BMC_HV(timeout 5 s)  # Calibration Identification
      frame UI2Sens01_CVN_XIX_BMC_CAN01: id 0x1A5554CA, to BMC_HV, frame-length=8, can-addressing-mode=EXTENDED, can-frame-rx-behavior=CAN-20, can-frame-tx-behavior=CAN-20
        pdu UI2Sens01_CVN_XIX_BMC_CAN01: length=8, transmission-mode-true-timing=cyclic-timing={time-offset=0, time-period=1}, unused-bit-pattern=0
          signal UI2Sens01_CVN_VLD_XIX_UI2Sens01_CVN_XIX_BMC_CAN01: start 0, 1 bit, little-endian, data-type-policy=OVERRIDE, i-signal-type=PRIMITIVE, init-value=0, base-type=BT_UI2Sens01_CVN_VLD, compu-method=CM_UI2Sens01_CVN_VLD, data-constr=DC_UI2Sens01_CVN_VLD, transfer-property=PENDING, to BMC_HV(timeout 5 s)  # Über dieses Signal wird gekennzeichnet, ob die Berechnung der CVN im SecondaryOBDECU abgeschlossen ist.
          signal UI2Sens01_CVN_Byte_1_XIX_UI2Sens01_CVN_XIX_BMC_CAN01: start 1, 8 bit, little-endian, data-type-policy=OVERRIDE, i-signal-type=PRIMITIVE, init-value=0, base-type=BT_UI2Sens01_CVN_Byte_1, compu-method=CM_UI2Sens01_CVN_Byte_1, data-constr=DC_UI2Sens01_CVN_Byte_1, transfer-property=PENDING, to BMC_HV(timeout 5 s)  # Calibration Verification Number
          signal UI2Sens01_CVN_Byte_2_XIX_UI2Sens01_CVN_XIX_BMC_CAN01: start 9, 8 bit, little-endian, data-type-policy=OVERRIDE, i-signal-type=PRIMITIVE, init-value=0, base-type=BT_UI2Sens01_CVN_Byte_2, compu-method=CM_UI2Sens01_CVN_Byte_2, data-constr=DC_UI2Sens01_CVN_Byte_2, transfer-property=PENDING, to BMC_HV(timeout 5 s)  # Calibration Verification Number
          signal UI2Sens01_CVN_Byte_3_XIX_UI2Sens01_CVN_XIX_BMC_CAN01: start 17, 8 bit, little-endian, data-type-policy=OVERRIDE, i-signal-type=PRIMITIVE, init-value=0, base-type=BT_UI2Sens01_CVN_Byte_3, compu-method=CM_UI2Sens01_CVN_Byte_3, data-constr=DC_UI2Sens01_CVN_Byte_3, transfer-property=PENDING, to BMC_HV(timeout 5 s)  # Calibration Verification Number
          signal UI2Sens01_CVN_Byte_4_XIX_UI2Sens01_CVN_XIX_BMC_CAN01: start 25, 8 bit, little-endian, data-type-policy=OVERRIDE, i-signal-type=PRIMITIVE, init-value=0, base-type=BT_UI2Sens01_CVN_Byte_4, compu-method=CM_UI2Sens01_CVN_Byte_4, data-constr=DC_UI2Sens01_CVN_Byte_4, transfer-property=PENDING, to BMC_HV(timeout 5 s)  # Calibration Verification Number
      frame UI2Sens02_CALID_01_XIX_BMC_CAN01: id 0x1A5554C8, to BMC_HV, frame-length=8, can-addressing-mode=EXTENDED, can-frame-rx-behavior=CAN-20, can-frame-tx-behavior=CAN-20
        pdu UI2Sens02_CALID_01_XIX_BMC_CAN01: length=8, transmission-mode-true-timing=cyclic-timing={time-offset=0, time-period=1}, unused-bit-pattern=0
          signal UI2Sens02_CALID_Index_01_XIX_UI2Sens02_CALID_01_XIX_BMC_CAN01: start 0, 8 bit, little-endian, data-type-policy=OVERRIDE, i-signal-type=PRIMITIVE, init-value=63, base-type=BT_UI2Sens02_CALID_Index_01, compu-method=CM_UI2Sens02_CALID_Index_01, data-constr=DC_UI2Sens02_CALID_Index_01, transfer-property=PENDING, to BMC_HV(timeout 5 s)  # Calibration Identification
          signal UI2Sens02_CALID_Index_02_XIX_UI2Sens02_CALID_01_XIX_BMC_CAN01: start 8, 8 bit, little-endian, data-type-policy=OVERRIDE, i-signal-type=PRIMITIVE, init-value=63, base-type=BT_UI2Sens02_CALID_Index_02, compu-method=CM_UI2Sens02_CALID_Index_02, data-constr=DC_UI2Sens02_CALID_Index_02, transfer-property=PENDING, to BMC_HV(timeout 5 s)  # Calibration Identification
          signal UI2Sens02_CALID_Index_03_XIX_UI2Sens02_CALID_01_XIX_BMC_CAN01: start 16, 8 bit, little-endian, data-type-policy=OVERRIDE, i-signal-type=PRIMITIVE, init-value=63, base-type=BT_UI2Sens02_CALID_Index_03, compu-method=CM_UI2Sens02_CALID_Index_03, data-constr=DC_UI2Sens02_CALID_Index_03, transfer-property=PENDING, to BMC_HV(timeout 5 s)  # Calibration Identification
          signal UI2Sens02_CALID_Index_04_XIX_UI2Sens02_CALID_01_XIX_BMC_CAN01: start 24, 8 bit, little-endian, data-type-policy=OVERRIDE, i-signal-type=PRIMITIVE, init-value=63, base-type=BT_UI2Sens02_CALID_Index_04, compu-method=CM_UI2Sens02_CALID_Index_04, data-constr=DC_UI2Sens02_CALID_Index_04, transfer-property=PENDING, to BMC_HV(timeout 5 s)  # Calibration Identification
          signal UI2Sens02_CALID_Index_05_XIX_UI2Sens02_CALID_01_XIX_BMC_CAN01: start 32, 8 bit, little-endian, data-type-policy=OVERRIDE, i-signal-type=PRIMITIVE, init-value=63, base-type=BT_UI2Sens02_CALID_Index_05, compu-method=CM_UI2Sens02_CALID_Index_05, data-constr=DC_UI2Sens02_CALID_Index_05, transfer-property=PENDING, to BMC_HV(timeout 5 s)  # Calibration Identification
          signal UI2Sens02_CALID_Index_06_XIX_UI2Sens02_CALID_01_XIX_BMC_CAN01: start 40, 8 bit, little-endian, data-type-policy=OVERRIDE, i-signal-type=PRIMITIVE, init-value=63, base-type=BT_UI2Sens02_CALID_Index_06, compu-method=CM_UI2Sens02_CALID_Index_06, data-constr=DC_UI2Sens02_CALID_Index_06, transfer-property=PENDING, to BMC_HV(timeout 5 s)  # Calibration Identification
          signal UI2Sens02_CALID_Index_07_XIX_UI2Sens02_CALID_01_XIX_BMC_CAN01: start 48, 8 bit, little-endian, data-type-policy=OVERRIDE, i-signal-type=PRIMITIVE, init-value=63, base-type=BT_UI2Sens02_CALID_Index_07, compu-method=CM_UI2Sens02_CALID_Index_07, data-constr=DC_UI2Sens02_CALID_Index_07, transfer-property=PENDING, to BMC_HV(timeout 5 s)  # Calibration Identification
          signal UI2Sens02_CALID_Index_08_XIX_UI2Sens02_CALID_01_XIX_BMC_CAN01: start 56, 8 bit, little-endian, data-type-policy=OVERRIDE, i-signal-type=PRIMITIVE, init-value=63, base-type=BT_UI2Sens02_CALID_Index_08, compu-method=CM_UI2Sens02_CALID_Index_08, data-constr=DC_UI2Sens02_CALID_Index_08, transfer-property=PENDING, to BMC_HV(timeout 5 s)  # Calibration Identification
      frame UI2Sens02_CALID_02_XIX_BMC_CAN01: id 0x1A5554C9, to BMC_HV, frame-length=8, can-addressing-mode=EXTENDED, can-frame-rx-behavior=CAN-20, can-frame-tx-behavior=CAN-20
        pdu UI2Sens02_CALID_02_XIX_BMC_CAN01: length=8, transmission-mode-true-timing=cyclic-timing={time-offset=0, time-period=1}, unused-bit-pattern=0
          signal UI2Sens02_CALID_Index_09_XIX_UI2Sens02_CALID_02_XIX_BMC_CAN01: start 0, 8 bit, little-endian, data-type-policy=OVERRIDE, i-signal-type=PRIMITIVE, init-value=63, base-type=BT_UI2Sens02_CALID_Index_09, compu-method=CM_UI2Sens02_CALID_Index_09, data-constr=DC_UI2Sens02_CALID_Index_09, transfer-property=PENDING, to BMC_HV(timeout 5 s)  # Calibration Identification
          signal UI2Sens02_CALID_Index_10_XIX_UI2Sens02_CALID_02_XIX_BMC_CAN01: start 8, 8 bit, little-endian, data-type-policy=OVERRIDE, i-signal-type=PRIMITIVE, init-value=63, base-type=BT_UI2Sens02_CALID_Index_10, compu-method=CM_UI2Sens02_CALID_Index_10, data-constr=DC_UI2Sens02_CALID_Index_10, transfer-property=PENDING, to BMC_HV(timeout 5 s)  # Calibration Identification
          signal UI2Sens02_CALID_Index_11_XIX_UI2Sens02_CALID_02_XIX_BMC_CAN01: start 16, 8 bit, little-endian, data-type-policy=OVERRIDE, i-signal-type=PRIMITIVE, init-value=63, base-type=BT_UI2Sens02_CALID_Index_11, compu-method=CM_UI2Sens02_CALID_Index_11, data-constr=DC_UI2Sens02_CALID_Index_11, transfer-property=PENDING, to BMC_HV(timeout 5 s)  # Calibration Identification
          signal UI2Sens02_CALID_Index_12_XIX_UI2Sens02_CALID_02_XIX_BMC_CAN01: start 24, 8 bit, little-endian, data-type-policy=OVERRIDE, i-signal-type=PRIMITIVE, init-value=63, base-type=BT_UI2Sens02_CALID_Index_12, compu-method=CM_UI2Sens02_CALID_Index_12, data-constr=DC_UI2Sens02_CALID_Index_12, transfer-property=PENDING, to BMC_HV(timeout 5 s)  # Calibration Identification
          signal UI2Sens02_CALID_Index_13_XIX_UI2Sens02_CALID_02_XIX_BMC_CAN01: start 32, 8 bit, little-endian, data-type-policy=OVERRIDE, i-signal-type=PRIMITIVE, init-value=63, base-type=BT_UI2Sens02_CALID_Index_13, compu-method=CM_UI2Sens02_CALID_Index_13, data-constr=DC_UI2Sens02_CALID_Index_13, transfer-property=PENDING, to BMC_HV(timeout 5 s)  # Calibration Identification
          signal UI2Sens02_CALID_Index_14_XIX_UI2Sens02_CALID_02_XIX_BMC_CAN01: start 40, 8 bit, little-endian, data-type-policy=OVERRIDE, i-signal-type=PRIMITIVE, init-value=63, base-type=BT_UI2Sens02_CALID_Index_14, compu-method=CM_UI2Sens02_CALID_Index_14, data-constr=DC_UI2Sens02_CALID_Index_14, transfer-property=PENDING, to BMC_HV(timeout 5 s)  # Calibration Identification
          signal UI2Sens02_CALID_Index_15_XIX_UI2Sens02_CALID_02_XIX_BMC_CAN01: start 48, 8 bit, little-endian, data-type-policy=OVERRIDE, i-signal-type=PRIMITIVE, init-value=63, base-type=BT_UI2Sens02_CALID_Index_15, compu-method=CM_UI2Sens02_CALID_Index_15, data-constr=DC_UI2Sens02_CALID_Index_15, transfer-property=PENDING, to BMC_HV(timeout 5 s)  # Calibration Identification
          signal UI2Sens02_CALID_Index_16_XIX_UI2Sens02_CALID_02_XIX_BMC_CAN01: start 56, 8 bit, little-endian, data-type-policy=OVERRIDE, i-signal-type=PRIMITIVE, init-value=63, base-type=BT_UI2Sens02_CALID_Index_16, compu-method=CM_UI2Sens02_CALID_Index_16, data-constr=DC_UI2Sens02_CALID_Index_16, transfer-property=PENDING, to BMC_HV(timeout 5 s)  # Calibration Identification
      frame UI2Sens02_CVN_XIX_BMC_CAN01: id 0x1A5554CB, to BMC_HV, frame-length=8, can-addressing-mode=EXTENDED, can-frame-rx-behavior=CAN-20, can-frame-tx-behavior=CAN-20
        pdu UI2Sens02_CVN_XIX_BMC_CAN01: length=8, transmission-mode-true-timing=cyclic-timing={time-offset=0, time-period=1}, unused-bit-pattern=0
          signal UI2Sens02_CVN_VLD_XIX_UI2Sens02_CVN_XIX_BMC_CAN01: start 0, 1 bit, little-endian, data-type-policy=OVERRIDE, i-signal-type=PRIMITIVE, init-value=0, base-type=BT_UI2Sens02_CVN_VLD, compu-method=CM_UI2Sens02_CVN_VLD, data-constr=DC_UI2Sens02_CVN_VLD, transfer-property=PENDING, to BMC_HV(timeout 5 s)  # Über dieses Signal wird gekennzeichnet, ob die Berechnung der CVN im SecondaryOBDECU abgeschlossen ist.
          signal UI2Sens02_CVN_Byte_1_XIX_UI2Sens02_CVN_XIX_BMC_CAN01: start 1, 8 bit, little-endian, data-type-policy=OVERRIDE, i-signal-type=PRIMITIVE, init-value=0, base-type=BT_UI2Sens02_CVN_Byte_1, compu-method=CM_UI2Sens02_CVN_Byte_1, data-constr=DC_UI2Sens02_CVN_Byte_1, transfer-property=PENDING, to BMC_HV(timeout 5 s)  # Calibration Verification Number
          signal UI2Sens02_CVN_Byte_2_XIX_UI2Sens02_CVN_XIX_BMC_CAN01: start 9, 8 bit, little-endian, data-type-policy=OVERRIDE, i-signal-type=PRIMITIVE, init-value=0, base-type=BT_UI2Sens02_CVN_Byte_2, compu-method=CM_UI2Sens02_CVN_Byte_2, data-constr=DC_UI2Sens02_CVN_Byte_2, transfer-property=PENDING, to BMC_HV(timeout 5 s)  # Calibration Verification Number
          signal UI2Sens02_CVN_Byte_3_XIX_UI2Sens02_CVN_XIX_BMC_CAN01: start 17, 8 bit, little-endian, data-type-policy=OVERRIDE, i-signal-type=PRIMITIVE, init-value=0, base-type=BT_UI2Sens02_CVN_Byte_3, compu-method=CM_UI2Sens02_CVN_Byte_3, data-constr=DC_UI2Sens02_CVN_Byte_3, transfer-property=PENDING, to BMC_HV(timeout 5 s)  # Calibration Verification Number
          signal UI2Sens02_CVN_Byte_4_XIX_UI2Sens02_CVN_XIX_BMC_CAN01: start 25, 8 bit, little-endian, data-type-policy=OVERRIDE, i-signal-type=PRIMITIVE, init-value=0, base-type=BT_UI2Sens02_CVN_Byte_4, compu-method=CM_UI2Sens02_CVN_Byte_4, data-constr=DC_UI2Sens02_CVN_Byte_4, transfer-property=PENDING, to BMC_HV(timeout 5 s)  # Calibration Verification Number
      frame XCP_BJB_CRO_01_XIX_BMC_CAN01: id 0x18FCD000, from BMC_HV, frame-length=8, can-addressing-mode=EXTENDED, can-frame-rx-behavior=CAN-20, can-frame-tx-behavior=CAN-20
        user defined pdu CDD_XCP_BJB_CRO_01_XIX_BMC_CAN01: length=8, cdd-type=EID
      frame XCP_BJB_DTO_01_XIX_BMC_CAN01: id 0x18FCD001, to BMC_HV, frame-length=8, can-addressing-mode=EXTENDED, can-frame-rx-behavior=CAN-20, can-frame-tx-behavior=CAN-20
        user defined pdu CDD_XCP_BJB_DTO_01_XIX_BMC_CAN01: length=8, cdd-type=EID
      pdu triggering PT_BMC_CAN01_XIX_TPCHType_CANHS_Flash_DIA_XIX_0x17FC16D0_XIX_0x17FE16D0_XIX_Physical: pdu=DCM_BMC_CAN01_XIX_TPCHType_CANHS_Flash_DIA_XIX_0x17FC16D0_XIX_0x17FE16D0_XIX_Physical, from BMC_HV
      pdu triggering PT_BMC_CAN01_XIX_TPCHType_CANHS_Flash_DIA_XIX_0x17FC17B1_XIX_0x17FE17B1_XIX_Physical: pdu=DCM_BMC_CAN01_XIX_TPCHType_CANHS_Flash_DIA_XIX_0x17FC17B1_XIX_0x17FE17B1_XIX_Physical, from BMC_HV
      pdu triggering PT_BMC_CAN01_XIX_TPCHType_CANHS_Flash_DIA_XIX_0x17FC17B2_XIX_0x17FE17B2_XIX_Physical: pdu=DCM_BMC_CAN01_XIX_TPCHType_CANHS_Flash_DIA_XIX_0x17FC17B2_XIX_0x17FE17B2_XIX_Physical, from BMC_HV
      pdu triggering PT_BMC_CAN01_XIX_TPCHType_CANHS_Flash_DIA_XIX_0x17FE16D0_XIX_0x17FC16D0_XIX_Physical: pdu=DCM_BMC_CAN01_XIX_TPCHType_CANHS_Flash_DIA_XIX_0x17FE16D0_XIX_0x17FC16D0_XIX_Physical, to BMC_HV
      pdu triggering PT_BMC_CAN01_XIX_TPCHType_CANHS_Flash_DIA_XIX_0x17FE17B1_XIX_0x17FC17B1_XIX_Physical: pdu=DCM_BMC_CAN01_XIX_TPCHType_CANHS_Flash_DIA_XIX_0x17FE17B1_XIX_0x17FC17B1_XIX_Physical, to BMC_HV
      pdu triggering PT_BMC_CAN01_XIX_TPCHType_CANHS_Flash_DIA_XIX_0x17FE17B2_XIX_0x17FC17B2_XIX_Physical: pdu=DCM_BMC_CAN01_XIX_TPCHType_CANHS_Flash_DIA_XIX_0x17FE17B2_XIX_0x17FC17B2_XIX_Physical, to BMC_HV
      pdu triggering PT_BMC_CAN01_XIX_TPCHType_CANHS_ISO_Diagnose_XIX_0x700_XIX_Functional: pdu=DCM_BMC_CAN01_XIX_TPCHType_CANHS_ISO_Diagnose_XIX_0x700_XIX_Functional, from BMC_HV
      pdu triggering PT_BMC_CAN01_XIX_TPCHType_CANHS_OBDC_Diagnose_XIX_0x17FD0200_XIX_Functional: pdu=DCM_BMC_CAN01_XIX_TPCHType_CANHS_OBDC_Diagnose_XIX_0x17FD0200_XIX_Functional, from BMC_HV
      pdu triggering PT_BMC_CAN01_XIX_TPCHType_CANHS_OBDC_SSN_Diagnose_XIX_0x17FC70D0_XIX_0x17FE70D0_XIX_Physical: pdu=DCM_BMC_CAN01_XIX_TPCHType_CANHS_OBDC_SSN_Diagnose_XIX_0x17FC70D0_XIX_0x17FE70D0_XIX_Physical, from BMC_HV
      pdu triggering PT_BMC_CAN01_XIX_TPCHType_CANHS_OBDC_SSN_Diagnose_XIX_0x17FC71B1_XIX_0x17FE71B1_XIX_Physical: pdu=DCM_BMC_CAN01_XIX_TPCHType_CANHS_OBDC_SSN_Diagnose_XIX_0x17FC71B1_XIX_0x17FE71B1_XIX_Physical, from BMC_HV
      pdu triggering PT_BMC_CAN01_XIX_TPCHType_CANHS_OBDC_SSN_Diagnose_XIX_0x17FC71B2_XIX_0x17FE71B2_XIX_Physical: pdu=DCM_BMC_CAN01_XIX_TPCHType_CANHS_OBDC_SSN_Diagnose_XIX_0x17FC71B2_XIX_0x17FE71B2_XIX_Physical, from BMC_HV
      pdu triggering PT_BMC_CAN01_XIX_TPCHType_CANHS_OBDC_SSN_Diagnose_XIX_0x17FE70D0_XIX_0x17FC70D0_XIX_Physical: pdu=DCM_BMC_CAN01_XIX_TPCHType_CANHS_OBDC_SSN_Diagnose_XIX_0x17FE70D0_XIX_0x17FC70D0_XIX_Physical, to BMC_HV
      pdu triggering PT_BMC_CAN01_XIX_TPCHType_CANHS_OBDC_SSN_Diagnose_XIX_0x17FE71B1_XIX_0x17FC71B1_XIX_Physical: pdu=DCM_BMC_CAN01_XIX_TPCHType_CANHS_OBDC_SSN_Diagnose_XIX_0x17FE71B1_XIX_0x17FC71B1_XIX_Physical, to BMC_HV
      pdu triggering PT_BMC_CAN01_XIX_TPCHType_CANHS_OBDC_SSN_Diagnose_XIX_0x17FE71B2_XIX_0x17FC71B2_XIX_Physical: pdu=DCM_BMC_CAN01_XIX_TPCHType_CANHS_OBDC_SSN_Diagnose_XIX_0x17FE71B2_XIX_0x17FC71B2_XIX_Physical, to BMC_HV
package /NmConfig
  nm config NmConfig: can-nm-cluster-coupling{coupled-cluster=[NmCluster_BMC_CAN01, NmCluster_HCP5_CANFD01], nm-busload-reduction-enabled=false, nm-immediate-restart-enabled=false}
    can nm cluster NmCluster_BMC_CAN01: communication-cluster=BMC_CAN01, nm-channel-sleep-master=false, nm-pnc-participation=true, nm-synchronizing-network=false, nm-busload-reduction-active=false, nm-cbv-position=1, nm-immediate-nm-cycle-time=0.02, nm-immediate-nm-transmissions=10, nm-message-timeout-time=0.1, nm-msg-cycle-time=0.2, nm-network-timeout=1, nm-remote-sleep-indication-time=0.5, nm-repeat-message-time=4, nm-wait-bus-sleep-time=0.75
      can nm node NmNode_BMC_HV_XIX_BMC_CAN01: controller=CT_BMC_CAN01, nm-if-ecu=NmEcu_BMC_HV, nm-passive-mode-enabled=false, rx-nm-pdu=NM_Dummy01_XIX_BMC_CAN01, tx-nm-pdu=NMH_Hybrid_01_XIX_BMC_CAN01, nm-car-wake-up-rx-enabled=false, nm-msg-cycle-offset=0
    can nm cluster NmCluster_HCP5_CANFD01: communication-cluster=HCP5_CANFD01, nm-channel-sleep-master=false, nm-pnc-participation=true, nm-synchronizing-network=false, nm-busload-reduction-active=false, nm-cbv-position=0, nm-immediate-nm-cycle-time=0.02, nm-immediate-nm-transmissions=10, nm-message-timeout-time=0.1, nm-msg-cycle-time=0.2, nm-network-timeout=1, nm-remote-sleep-indication-time=0.5, nm-repeat-message-time=4, nm-wait-bus-sleep-time=0.75
      can nm node NmNode_BMC_HV_XIX_HCP5_CANFD01: controller=CT_HCP5_CANFD01, nm-if-ecu=NmEcu_BMC_HV, nm-passive-mode-enabled=false, rx-nm-pdu=[NM_AWC_XIX_HCP5_CANFD01, NM_Gateway_XIX_HCP5_CANFD01, NM_HVZB_XIX_HCP5_CANFD01, NM_Ladegeraet_XIX_HCP5_CANFD01, NM_SACID_1_XIX_HCP5_CANFD01, NM_SACID_2_XIX_HCP5_CANFD01], tx-nm-pdu=NM_Hybrid_01_XIX_HCP5_CANFD01, nm-car-wake-up-rx-enabled=false, nm-msg-cycle-offset=0
    nm-if-ecus:
      nm ecu NmEcu_BMC_HV: ecu-instance=BMC_HV, nm-bus-synchronization-enabled=false, nm-com-control-enabled=false, nm-node-detection-enabled=false, nm-node-id-enabled=false, nm-pdu-rx-indication-enabled=true, nm-remote-sleep-ind-enabled=false, nm-repeat-msg-ind-enabled=false, nm-state-change-ind-enabled=true, nm-user-data-enabled=true
